VERSION "HNNBNNNYNNNNNNNNNNNNNNNNNNNNNNNNNNNNNNNNNN/4/%%%/4/'%**4NNN///"

NS_ :

BS_:

BU_: Airbag_MQB BAP_Tester_MQB BMS_MQB Datenlogger_MQB Gateway_MQB Getriebe_DQ_Hybrid_MQB Getriebe_DQ_MQB LEH_MQB Motor_Diesel_MQB Motor_Hybrid_MQB Motor_Otto_MQB SAK_MQB Waehlhebel_MQB

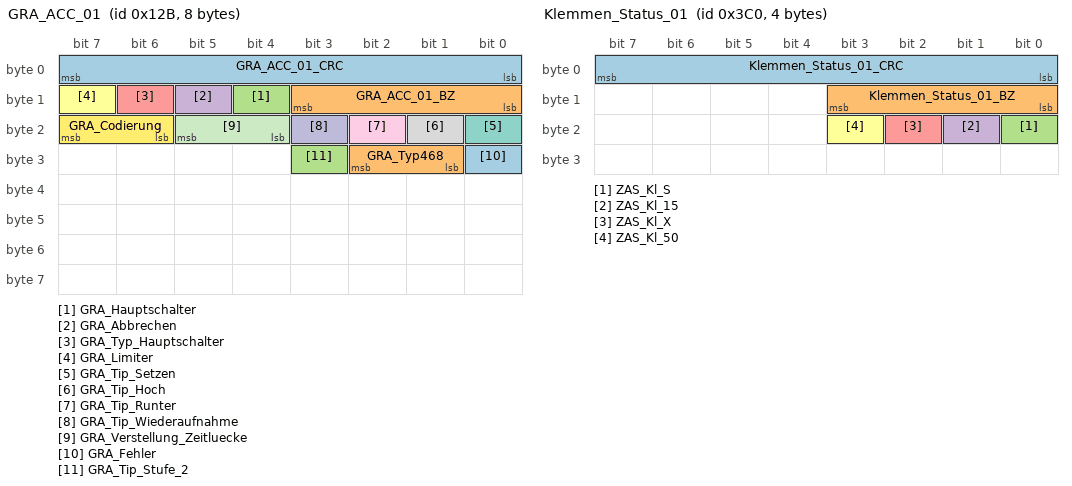
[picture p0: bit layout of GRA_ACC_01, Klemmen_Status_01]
BO_ 299 GRA_ACC_01: 8 Gateway_MQB
 SG_ GRA_ACC_01_CRC : 0|8@1+ (1,0) [0|255] ""  Motor_Diesel_MQB,Motor_Hybrid_MQB,Motor_Otto_MQB
 SG_ GRA_ACC_01_BZ : 8|4@1+ (1,0) [0|15] ""  Motor_Diesel_MQB,Motor_Hybrid_MQB,Motor_Otto_MQB
 SG_ GRA_Hauptschalter : 12|1@1+ (1,0) [0|1] ""  Motor_Diesel_MQB,Motor_Hybrid_MQB,Motor_Otto_MQB
 SG_ GRA_Abbrechen : 13|1@1+ (1,0) [0|1] ""  Motor_Diesel_MQB,Motor_Hybrid_MQB,Motor_Otto_MQB
 SG_ GRA_Typ_Hauptschalter : 14|1@1+ (1,0) [0|1] ""  Motor_Diesel_MQB,Motor_Hybrid_MQB,Motor_Otto_MQB
 SG_ GRA_Limiter : 15|1@1+ (1,0) [0|1] ""  Getriebe_DQ_Hybrid_MQB,Getriebe_DQ_MQB,Motor_Diesel_MQB,Motor_Hybrid_MQB,Motor_Otto_MQB
 SG_ GRA_Tip_Setzen : 16|1@1+ (1,0) [0|1] ""  Getriebe_DQ_Hybrid_MQB,Getriebe_DQ_MQB,Motor_Diesel_MQB,Motor_Hybrid_MQB,Motor_Otto_MQB
 SG_ GRA_Tip_Hoch : 17|1@1+ (1,0) [0|1] ""  Getriebe_DQ_Hybrid_MQB,Getriebe_DQ_MQB,Motor_Diesel_MQB,Motor_Hybrid_MQB,Motor_Otto_MQB
 SG_ GRA_Tip_Runter : 18|1@1+ (1,0) [0|1] ""  Getriebe_DQ_Hybrid_MQB,Getriebe_DQ_MQB,Motor_Diesel_MQB,Motor_Hybrid_MQB,Motor_Otto_MQB
 SG_ GRA_Tip_Wiederaufnahme : 19|1@1+ (1,0) [0|1] ""  Getriebe_DQ_Hybrid_MQB,Getriebe_DQ_MQB,Motor_Diesel_MQB,Motor_Hybrid_MQB,Motor_Otto_MQB
 SG_ GRA_Verstellung_Zeitluecke : 20|2@1+ (1,0) [0|3] ""  Motor_Diesel_MQB,Motor_Hybrid_MQB,Motor_Otto_MQB
 SG_ GRA_Codierung : 22|2@1+ (1,0) [0|3] ""  Motor_Diesel_MQB,Motor_Hybrid_MQB,Motor_Otto_MQB
 SG_ GRA_Fehler : 24|1@1+ (1,0) [0|1] ""  Getriebe_DQ_Hybrid_MQB,Getriebe_DQ_MQB,Motor_Diesel_MQB,Motor_Hybrid_MQB,Motor_Otto_MQB
 SG_ GRA_Typ468 : 25|2@1+ (1,0) [0|3] ""  Motor_Diesel_MQB,Motor_Hybrid_MQB,Motor_Otto_MQB
 SG_ GRA_Tip_Stufe_2 : 27|1@1+ (1,0) [0|1] ""  Motor_Diesel_MQB,Motor_Hybrid_MQB,Motor_Otto_MQB

BO_ 18 GSG_WFS_Anfrage: 8 Getriebe_DQ_Hybrid_MQB
 SG_ WFS_GSG_RND : 0|32@1+ (1,0) [0|4294967295] ""  Gateway_MQB
 SG_ WFS_GSG_CRC : 32|32@1+ (1,0) [0|4294967295] ""  Gateway_MQB

BO_ 19 IMMO_GSG_Antwort: 8 Gateway_MQB
 SG_ WFS_IMMO_GSG_CRC : 0|32@1+ (1,0) [0|4294967295] ""  Getriebe_DQ_Hybrid_MQB,Getriebe_DQ_MQB
 SG_ WFS_IMMO_GSG_Status : 56|8@1+ (1,0) [0|255] ""  Getriebe_DQ_Hybrid_MQB,Getriebe_DQ_MQB

BO_ 17 IMMO_MSG1_Antwort: 8 Gateway_MQB
 SG_ WFS_IMMO_MSG1_CRC : 0|32@1+ (1,0) [0|4294967295] ""  Motor_Diesel_MQB,Motor_Hybrid_MQB,Motor_Otto_MQB
 SG_ WFS_IMMO_MSG1_Status : 56|8@1+ (1,0) [0|255] ""  Motor_Diesel_MQB,Motor_Hybrid_MQB,Motor_Otto_MQB

BO_ 21 IMMO_MSG2_Antwort: 8 Gateway_MQB
 SG_ WFS_IMMO_MSG2_CRC : 0|32@1+ (1,0) [0|4294967295] "" Vector__XXX
 SG_ WFS_IMMO_MSG2_Status : 56|8@1+ (1,0) [0|255] "" Vector__XXX

BO_ 23 IMMO_MSG3_Antwort: 8 Gateway_MQB
 SG_ WFS_IMMO_MSG3_CRC : 0|32@1+ (1,0) [0|4294967295] "" Vector__XXX
 SG_ WFS_IMMO_MSG3_Status : 56|8@1+ (1,0) [0|255] "" Vector__XXX

BO_ 25 IMMO_MSG4_Antwort: 8 Gateway_MQB
 SG_ WFS_IMMO_MSG4_CRC : 0|32@1+ (1,0) [0|4294967295] ""  LEH_MQB
 SG_ WFS_IMMO_MSG4_Status : 56|8@1+ (1,0) [0|255] ""  LEH_MQB

BO_ 1813 ISO_Airbag_01_Req: 8 Gateway_MQB
 SG_ ISO_Airbag_01_Req_Data : 0|64@1+ (1,0) [0|4294967295] ""  Airbag_MQB

BO_ 1919 ISO_Airbag_01_Resp: 8 Airbag_MQB
 SG_ ISO_Airbag_01_Resp_Data : 0|64@1+ (1,0) [0|4294967295] ""  Gateway_MQB

BO_ 2022 ISO_EMotor_01_Req: 8 Gateway_MQB
 SG_ ISO_EMotor_01_Req_Data : 0|64@1+ (1,0) [0|4294967295] ""  LEH_MQB

BO_ 2030 ISO_EMotor_01_Resp: 8 LEH_MQB
 SG_ ISO_EMotor_01_Resp_Data : 0|64@1+ (1,0) [0|4294967295] ""  Gateway_MQB

BO_ 1793 ISO_Funktionaler_Req_01: 8 Gateway_MQB
 SG_ ISO_01_Req_Data : 0|64@1+ (1,0) [0|4294967295] "" Vector__XXX

BO_ 1794 ISO_Funktionaler_Req_02: 8 Gateway_MQB
 SG_ ISO_02_Req_Data : 0|64@1+ (1,0) [0|4294967295] "" Vector__XXX

BO_ 1796 ISO_Funktionaler_Req_04: 8 Gateway_MQB
 SG_ ISO_04_Req_Data : 0|64@1+ (1,0) [0|4294967295] "" Vector__XXX

BO_ 1797 ISO_Funktionaler_Req_05: 8 Gateway_MQB
 SG_ ISO_05_Req_Data : 0|64@1+ (1,0) [0|4294967295] "" Vector__XXX

BO_ 1798 ISO_Funktionaler_Req_06: 8 Gateway_MQB
 SG_ ISO_06_Req_Data : 0|64@1+ (1,0) [0|4294967295] "" Vector__XXX

BO_ 1799 ISO_Funktionaler_Req_07: 8 Gateway_MQB
 SG_ ISO_07_Req_Data : 0|64@1+ (1,0) [0|4294967295] "" Vector__XXX

BO_ 1800 ISO_Funktionaler_Req_08: 8 Gateway_MQB
 SG_ ISO_08_Req_Data : 0|64@1+ (1,0) [0|4294967295] "" Vector__XXX

BO_ 1801 ISO_Funktionaler_Req_09: 8 Gateway_MQB
 SG_ ISO_09_Req_Data : 0|64@1+ (1,0) [0|4294967295] "" Vector__XXX

BO_ 1795 ISO_Funktionaler_Req_Aggregate: 8 Gateway_MQB
 SG_ ISO_Functionaler_Req_Aggregate : 0|64@1+ (1,0) [0|4294967295] ""  Getriebe_DQ_Hybrid_MQB,Getriebe_DQ_MQB,LEH_MQB,Motor_Diesel_MQB,Motor_Hybrid_MQB,Motor_Otto_MQB

BO_ 1792 ISO_Funktionaler_Req_All: 8 Gateway_MQB
 SG_ ISO_ALL_01_Req_Data : 0|64@1+ (1,0) [0|4294967295] ""  Airbag_MQB,BMS_MQB,Getriebe_DQ_Hybrid_MQB,Getriebe_DQ_MQB,LEH_MQB,Motor_Diesel_MQB,Motor_Hybrid_MQB,Motor_Otto_MQB,SAK_MQB

BO_ 2015 ISO_Funktionaler_Req_OBD: 8 Gateway_MQB
 SG_ ISO_OBD_Funktionaler_Req_Data : 0|64@1+ (1,0) [0|4294967295] ""  BMS_MQB,Getriebe_DQ_Hybrid_MQB,Getriebe_DQ_MQB,LEH_MQB,Motor_Diesel_MQB,Motor_Hybrid_MQB,Motor_Otto_MQB

BO_ 2017 ISO_Getriebe_01_Req: 8 Gateway_MQB
 SG_ ISO_Getriebe_01_Req_Data : 0|64@1+ (1,0) [0|4294967295] ""  Getriebe_DQ_Hybrid_MQB,Getriebe_DQ_MQB

BO_ 2025 ISO_Getriebe_01_Resp: 8 Getriebe_DQ_Hybrid_MQB
 SG_ ISO_Getriebe_01_Resp_Data : 0|64@1+ (1,0) [0|4294967295] ""  Gateway_MQB

BO_ 2021 ISO_Hybrid_01_Req: 8 Gateway_MQB
 SG_ ISO_Hybrid_01_Req_Data : 0|64@1+ (1,0) [0|4294967295] ""  BMS_MQB

BO_ 2029 ISO_Hybrid_01_Resp: 8 BMS_MQB
 SG_ ISO_Hybrid_01_Resp_Data : 0|64@1+ (1,0) [0|4294967295] ""  Gateway_MQB

BO_ 2016 ISO_MO_01_Req: 8 Gateway_MQB
 SG_ ISO_MO_01_Req_Data : 0|64@1+ (1,0) [0|4294967295] ""  Motor_Diesel_MQB,Motor_Hybrid_MQB,Motor_Otto_MQB

BO_ 2024 ISO_MO_01_Resp: 8 Motor_Diesel_MQB
 SG_ ISO_MO_01_Resp_Data : 0|64@1+ (1,0) [0|4294967295] ""  Gateway_MQB

BO_ 2018 ISO_MOS_01_Req: 8 Gateway_MQB
 SG_ ISO_MOS_01_Req_Data : 0|64@1+ (1,0) [0|4294967295] "" Vector__XXX

BO_ 2026 ISO_MOS_01_Resp: 8 Vector__XXX
 SG_ ISO_MOS_01_Resp_Data : 0|64@1+ (1,0) [0|4294967295] ""  Gateway_MQB

BO_ 2023 ISO_OBD_reserv3_Req: 8 Gateway_MQB
 SG_ ISO_OBD_reserv3_Req_Data : 0|64@1+ (1,0) [0|4294967295] "" Vector__XXX

BO_ 2031 ISO_OBD_reserv3_Resp: 8 Vector__XXX
 SG_ ISO_OBD_reserv3_Resp_Data : 0|64@1+ (1,0) [0|4294967295] ""  Gateway_MQB

BO_ 2020 ISO_OBD_reserv4_Req: 8 Gateway_MQB
 SG_ ISO_OBD_reserv4_Req_Data : 0|64@1+ (1,0) [0|4294967295] "" Vector__XXX

BO_ 2028 ISO_OBD_reserv4_Resp: 8 Vector__XXX
 SG_ ISO_OBD_reserv4_Resp_Data : 0|64@1+ (1,0) [0|4294967295] ""  Gateway_MQB

BO_ 2019 ISO_OBD_reserv5_Req: 8 Gateway_MQB
 SG_ ISO_OBD_reserv5_Req_Data : 0|64@1+ (1,0) [0|4294967295] "" Vector__XXX

BO_ 2027 ISO_OBD_reserv5_Resp: 8 Vector__XXX
 SG_ ISO_OBD_reserv5_Resp_Data : 0|64@1+ (1,0) [0|4294967295] ""  Gateway_MQB

BO_ 1820 ISO_Soundaktor_Req: 8 Gateway_MQB
 SG_ ISO_Soundaktor_Req_Data : 0|64@1+ (1,0) [0|4294967295] ""  SAK_MQB

BO_ 1926 ISO_Soundaktor_Resp: 8 SAK_MQB
 SG_ ISO_Soundaktor_Resp_Data : 0|64@1+ (1,0) [0|4294967295] ""  Gateway_MQB

BO_ 960 Klemmen_Status_01: 4 Gateway_MQB
 SG_ Klemmen_Status_01_CRC : 0|8@1+ (1,0) [0|255] ""  Airbag_MQB,BMS_MQB,Motor_Diesel_MQB,Motor_Hybrid_MQB,Motor_Otto_MQB
 SG_ Klemmen_Status_01_BZ : 8|4@1+ (1,0) [0|15] ""  Airbag_MQB,BMS_MQB,Motor_Diesel_MQB,Motor_Hybrid_MQB,Motor_Otto_MQB
 SG_ ZAS_Kl_S : 16|1@1+ (1,0) [0|1] "" Vector__XXX
 SG_ ZAS_Kl_15 : 17|1@1+ (1,0) [0|1] ""  Airbag_MQB,BMS_MQB,Motor_Diesel_MQB,Motor_Hybrid_MQB,Motor_Otto_MQB
 SG_ ZAS_Kl_X : 18|1@1+ (1,0) [0|1] "" Vector__XXX
 SG_ ZAS_Kl_50 : 19|1@1+ (1,0) [0|1] "" Vector__XXX

BO_ 949 Klima_11: 8 Gateway_MQB
 SG_ KL_Drehz_Anh : 0|1@1+ (1,0) [0|1] ""  Motor_Diesel_MQB,Motor_Hybrid_MQB,Motor_Otto_MQB
 SG_ KL_Vorwarn_Komp_ein : 1|1@1+ (1,0) [0|1] ""  Motor_Diesel_MQB,Motor_Hybrid_MQB,Motor_Otto_MQB
 SG_ KL_AC_Schalter : 2|1@1+ (1,0) [0|1] "" Vector__XXX
 SG_ KL_Komp_Moment_alt : 3|1@1+ (1,0) [0|1] "" Vector__XXX
 SG_ KL_Zonen : 4|2@1+ (1,0) [0|3] ""  Motor_Diesel_MQB,Motor_Hybrid_MQB,Motor_Otto_MQB
 SG_ KL_Vorwarn_Zuheizer_ein : 6|1@1+ (1,0) [0|1] "" Vector__XXX
 SG_ KL_Zustand : 7|1@1+ (1,0) [0|1] ""  Motor_Diesel_MQB,Motor_Hybrid_MQB,Motor_Otto_MQB
 SG_ KL_Comp_rev_rq : 8|8@1+ (50,0) [0|8600] "Unit_MinutInver" Vector__XXX
 SG_ KL_Charisma_FahrPr : 16|4@1+ (1,0) [0|15] "" Vector__XXX
 SG_ KL_Charisma_Status : 20|2@1+ (1,0) [0|3] "" Vector__XXX
 SG_ KL_Comp_enable : 23|1@1+ (1,0) [0|1] "" Vector__XXX
 SG_ KL_Last_Kompr : 24|8@1+ (0.25,0) [0|63.5] "Unit_NewtoMeter"  Motor_Diesel_MQB,Motor_Hybrid_MQB,Motor_Otto_MQB
 SG_ KL_Spannungs_Anf : 32|2@1+ (1,0) [0|3] "" Vector__XXX
 SG_ KL_Thermomanagement : 34|2@1+ (1,0) [0|3] ""  Motor_Diesel_MQB,Motor_Hybrid_MQB,Motor_Otto_MQB
 SG_ KL_StartStopp_Info : 36|2@1+ (1,0) [0|3] ""  Motor_Diesel_MQB,Motor_Otto_MQB
 SG_ KL_Anf_KL : 40|8@1+ (0.4,0) [0|101.6] "Unit_PerCent"  Motor_Diesel_MQB,Motor_Hybrid_MQB,Motor_Otto_MQB
 SG_ KL_el_Zuheizer_Stufe : 48|3@1+ (1,0) [0|7] ""  Motor_Diesel_MQB

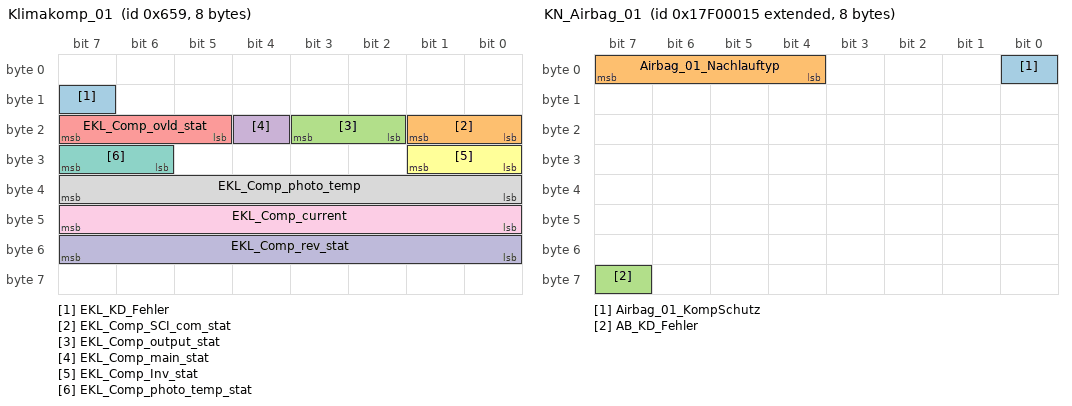
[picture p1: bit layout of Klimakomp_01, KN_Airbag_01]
BO_ 1625 Klimakomp_01: 8 Gateway_MQB
 SG_ EKL_KD_Fehler : 15|1@1+ (1,0) [0|1] "" Vector__XXX
 SG_ EKL_Comp_SCI_com_stat : 16|2@1+ (1,0) [0|3] "" Vector__XXX
 SG_ EKL_Comp_output_stat : 18|2@1+ (1,0) [0|3] "" Vector__XXX
 SG_ EKL_Comp_main_stat : 20|1@1+ (1,0) [0|1] "" Vector__XXX
 SG_ EKL_Comp_ovld_stat : 21|3@1+ (1,0) [0|7] "" Vector__XXX
 SG_ EKL_Comp_Inv_stat : 24|2@1+ (1,0) [0|3] "" Vector__XXX
 SG_ EKL_Comp_photo_temp_stat : 30|2@1+ (1,0) [0|3] "" Vector__XXX
 SG_ EKL_Comp_photo_temp : 32|8@1+ (1,0) [0|254] "Unit_DegreCelsi" Vector__XXX
 SG_ EKL_Comp_current : 40|8@1+ (0.1,0) [0|25.4] "Unit_Amper"  Motor_Hybrid_MQB
 SG_ EKL_Comp_rev_stat : 48|8@1+ (50,0) [0|8600] "Unit_MinutInver" Vector__XXX

BO_ 2549088277 KN_Airbag_01: 8 Airbag_MQB
 SG_ Airbag_01_KompSchutz : 0|1@1+ (1,0) [0|1] "" Vector__XXX
 SG_ Airbag_01_Nachlauftyp : 4|4@1+ (1,0) [0|15] ""  Gateway_MQB
 SG_ AB_KD_Fehler : 63|1@1+ (1,0) [0|1] ""  Gateway_MQB

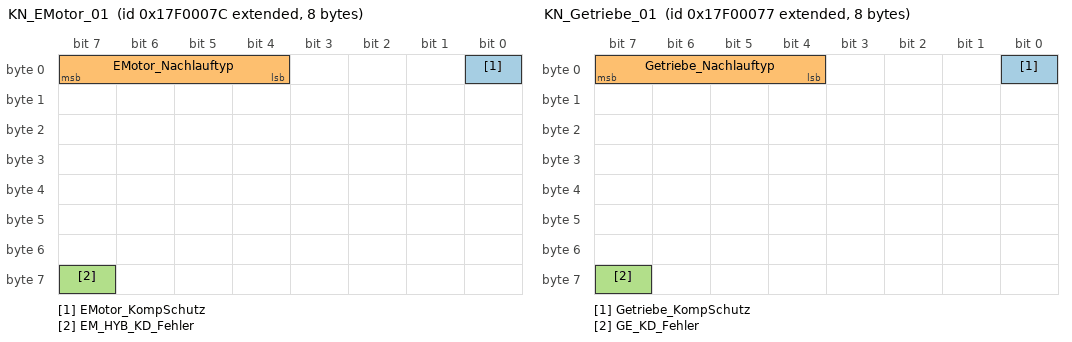
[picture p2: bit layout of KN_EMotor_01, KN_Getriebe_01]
BO_ 2549088380 KN_EMotor_01: 8 LEH_MQB
 SG_ EMotor_KompSchutz : 0|1@1+ (1,0) [0|1] "" Vector__XXX
 SG_ EMotor_Nachlauftyp : 4|4@1+ (1,0) [0|15] ""  Gateway_MQB
 SG_ EM_HYB_KD_Fehler : 63|1@1+ (1,0) [0|1] ""  Gateway_MQB

BO_ 2549088375 KN_Getriebe_01: 8 Getriebe_DQ_Hybrid_MQB
 SG_ Getriebe_KompSchutz : 0|1@1+ (1,0) [0|1] "" Vector__XXX
 SG_ Getriebe_Nachlauftyp : 4|4@1+ (1,0) [0|15] ""  Gateway_MQB
 SG_ GE_KD_Fehler : 63|1@1+ (1,0) [0|1] ""  Gateway_MQB

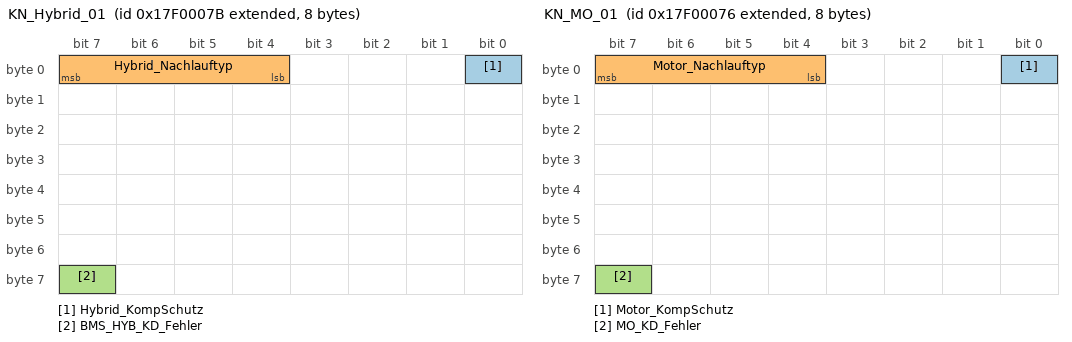
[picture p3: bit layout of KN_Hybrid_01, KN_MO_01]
BO_ 2549088379 KN_Hybrid_01: 8 BMS_MQB
 SG_ Hybrid_KompSchutz : 0|1@1+ (1,0) [0|1] "" Vector__XXX
 SG_ Hybrid_Nachlauftyp : 4|4@1+ (1,0) [0|15] ""  Gateway_MQB
 SG_ BMS_HYB_KD_Fehler : 63|1@1+ (1,0) [0|1] ""  Gateway_MQB

BO_ 2549088374 KN_MO_01: 8 Motor_Diesel_MQB
 SG_ Motor_KompSchutz : 0|1@1+ (1,0) [0|1] "" Vector__XXX
 SG_ Motor_Nachlauftyp : 4|4@1+ (1,0) [0|15] ""  Gateway_MQB
 SG_ MO_KD_Fehler : 63|1@1+ (1,0) [0|1] ""  Gateway_MQB

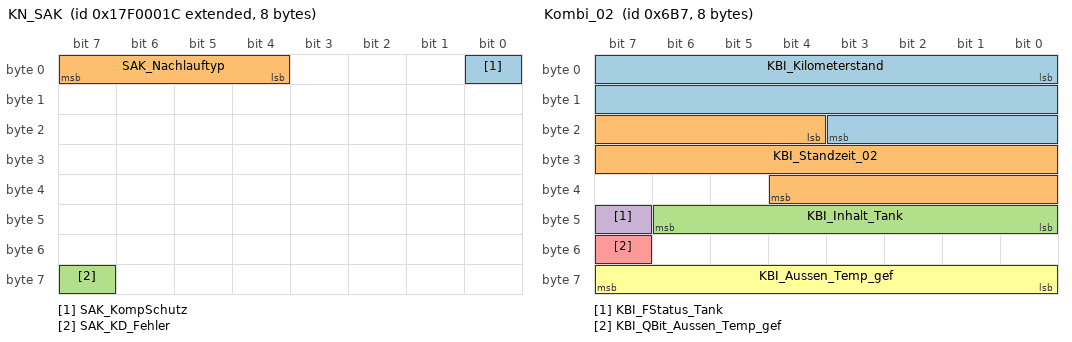
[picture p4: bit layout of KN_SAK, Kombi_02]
BO_ 2549088284 KN_SAK: 8 SAK_MQB
 SG_ SAK_KompSchutz : 0|1@1+ (1,0) [0|1] "" Vector__XXX
 SG_ SAK_Nachlauftyp : 4|4@1+ (1,0) [0|15] ""  Gateway_MQB
 SG_ SAK_KD_Fehler : 63|1@1+ (1,0) [0|1] ""  Gateway_MQB

BO_ 779 Kombi_01: 8 Gateway_MQB
 SG_ KBI_ABS_Lampe : 0|1@1+ (1,0) [0|1] "" Vector__XXX
 SG_ KBI_ESP_Lampe : 1|1@1+ (1,0) [0|1] "" Vector__XXX
 SG_ KBI_BKL_Lampe : 2|1@1+ (1,0) [0|1] "" Vector__XXX
 SG_ KBI_Airbag_Lampe : 3|1@1+ (1,0) [0|1] ""  Airbag_MQB
 SG_ KBI_SILA_gueltig : 4|1@1+ (1,0) [0|1] ""  Airbag_MQB
 SG_ KBI_Lenkung_Lampe : 5|1@1+ (1,0) [0|1] "" Vector__XXX
 SG_ KBI_Vorglueh_System_Lampe : 6|1@1+ (1,0) [0|1] ""  Motor_Diesel_MQB
 SG_ KBI_NV_in_Anzeige : 7|1@1+ (1,0) [0|1] "" Vector__XXX
 SG_ Kombi_01_BZ : 8|4@1+ (1,0) [0|15] ""  Motor_Diesel_MQB,Motor_Hybrid_MQB,Motor_Otto_MQB
 SG_ KBI_Anzeigestatus_ACC : 12|1@1+ (1,0) [0|1] "" Vector__XXX
 SG_ KBI_Anzeigestatus_GRA : 13|2@1+ (1,0) [0|3] ""  Motor_Diesel_MQB,Motor_Hybrid_MQB,Motor_Otto_MQB
 SG_ KBI_Oeldruck_Schalter : 15|1@1+ (1,0) [0|1] "" Vector__XXX
 SG_ KBI_Tankwarnung : 16|1@1+ (1,0) [0|1] ""  Motor_Diesel_MQB,Motor_Hybrid_MQB,Motor_Otto_MQB
 SG_ KBI_MFA_v_Einheit_01 : 17|1@1+ (1,0) [0|1] ""  Motor_Diesel_MQB,Motor_Hybrid_MQB,Motor_Otto_MQB
 SG_ KBI_im_Stellgliedtest : 18|1@1+ (1,0) [0|1] ""  Airbag_MQB
 SG_ KBI_Anzeigefehler_LDW : 19|2@1+ (1,0) [0|3] "" Vector__XXX
 SG_ KBI_Variante_USA : 21|1@1+ (1,0) [0|1] "" Vector__XXX
 SG_ KBI_Oeldruckwarnung : 22|1@1+ (1,0) [0|1] "" Vector__XXX
 SG_ KBI_Handbremse : 23|1@1+ (1,0) [0|1] ""  Getriebe_DQ_Hybrid_MQB,Getriebe_DQ_MQB
 SG_ KBI_V_Digital : 24|9@1+ (1,0) [0|511] "" Vector__XXX
 SG_ KBI_PLA_in_Anzeige : 33|1@1+ (1,0) [0|1] "" Vector__XXX
 SG_ KBI_Anzeigefehler_NV : 34|1@1+ (1,0) [0|1] "" Vector__XXX
 SG_ KBI_Anzeigestatus_LIM : 35|2@1+ (1,0) [0|3] ""  Motor_Diesel_MQB,Motor_Hybrid_MQB,Motor_Otto_MQB
 SG_ KBI_angez_Geschw : 48|10@1+ (0.32,0) [0|325.12] "Unit_KiloMeterPerHour"  Getriebe_DQ_Hybrid_MQB,Getriebe_DQ_MQB,Motor_Diesel_MQB,Motor_Hybrid_MQB,Motor_Otto_MQB
 SG_ KBI_Einheit_Tacho : 58|1@1+ (1,0) [0|1] ""  Motor_Diesel_MQB,Motor_Hybrid_MQB,Motor_Otto_MQB
 SG_ KBI_Konsistenz_ACC : 59|1@1+ (1,0) [0|1] "" Vector__XXX
 SG_ KBI_Fehler_Anzeige_ACC : 60|1@1+ (1,0) [0|1] "" Vector__XXX
 SG_ KBI_Anzeigefehler_SWA : 61|2@1+ (1,0) [0|3] "" Vector__XXX

BO_ 1719 Kombi_02: 8 Gateway_MQB
 SG_ KBI_Kilometerstand : 0|20@1+ (1,0) [0|1048573] "Unit_KiloMeter" Vector__XXX
 SG_ KBI_Standzeit_02 : 20|17@1+ (1,0) [0|131068] "Unit_Secon"  Getriebe_DQ_Hybrid_MQB,Getriebe_DQ_MQB,Motor_Diesel_MQB,Motor_Hybrid_MQB,Motor_Otto_MQB
 SG_ KBI_Inhalt_Tank : 40|7@1+ (1,0) [0|125] "Unit_Liter"  Motor_Diesel_MQB,Motor_Hybrid_MQB,Motor_Otto_MQB
 SG_ KBI_FStatus_Tank : 47|1@1+ (1,0) [0|1] ""  Motor_Diesel_MQB,Motor_Hybrid_MQB,Motor_Otto_MQB
 SG_ KBI_QBit_Aussen_Temp_gef : 55|1@1+ (1,0) [0|1] ""  Getriebe_DQ_Hybrid_MQB,Getriebe_DQ_MQB,Motor_Diesel_MQB,Motor_Hybrid_MQB,Motor_Otto_MQB
 SG_ KBI_Aussen_Temp_gef : 56|8@1+ (0.5,-50) [-50|75] "Unit_DegreCelsi"  Getriebe_DQ_Hybrid_MQB,Getriebe_DQ_MQB,Motor_Diesel_MQB,Motor_Hybrid_MQB,Motor_Otto_MQB

BO_ 2549874965 KS_Airbag_01_Req: 8 Gateway_MQB
 SG_ KS_Airbag_01_Req_Data : 0|64@1+ (1,0) [0|4294967295] ""  Airbag_MQB

BO_ 2550006037 KS_Airbag_01_Resp: 8 Airbag_MQB
 SG_ KS_Airbag_01_Resp_Data : 0|64@1+ (1,0) [0|4294967295] ""  Gateway_MQB

BO_ 982 Licht_hinten_01: 8 Gateway_MQB
 SG_ Licht_hinten_01_BZ : 0|4@1+ (1,0) [0|15] ""  Motor_Diesel_MQB,Motor_Hybrid_MQB,Motor_Otto_MQB
 SG_ BCM2_Bremsl_durch_ECD : 5|1@1+ (1,0) [0|1] ""  Motor_Diesel_MQB,Motor_Hybrid_MQB,Motor_Otto_MQB
 SG_ LH_Aussenlicht_def : 7|1@1+ (1,0) [0|1] "" Vector__XXX
 SG_ LH_Standlicht_H_aktiv : 8|1@1+ (1,0) [0|1] "" Vector__XXX
 SG_ LH_Parklicht_HL_aktiv : 9|1@1+ (1,0) [0|1] "" Vector__XXX
 SG_ LH_Parklicht_HR_aktiv : 10|1@1+ (1,0) [0|1] "" Vector__XXX
 SG_ LH_Bremslicht_H_aktiv : 11|1@1+ (1,0) [0|1] "" Vector__XXX
 SG_ LH_Nebelschluss_aktiv : 12|1@1+ (1,0) [0|1] "" Vector__XXX
 SG_ LH_Rueckfahrlicht_aktiv : 13|1@1+ (1,0) [0|1] "" Vector__XXX
 SG_ LH_Blinker_HL_akt : 14|1@1+ (1,0) [0|1] "" Vector__XXX
 SG_ LH_Blinker_HR_akt : 15|1@1+ (1,0) [0|1] "" Vector__XXX
 SG_ LH_Blinker_li_def : 16|1@1+ (1,0) [0|1] "" Vector__XXX
 SG_ LH_Bremsl_li_def : 17|1@1+ (1,0) [0|1] "" Vector__XXX
 SG_ LH_Schlusslicht_li_def : 18|1@1+ (1,0) [0|1] "" Vector__XXX
 SG_ LH_Rueckf_li_def : 19|1@1+ (1,0) [0|1] "" Vector__XXX
 SG_ LH_Nebel_li_def : 20|1@1+ (1,0) [0|1] "" Vector__XXX
 SG_ LH_Schluss_Brems_Nebel_li_def : 21|1@1+ (1,0) [0|1] "" Vector__XXX
 SG_ LH_Schluss_Brems_Nebel_re_def : 22|1@1+ (1,0) [0|1] "" Vector__XXX
 SG_ LH_Schluss_Brems_li_def : 24|1@1+ (1,0) [0|1] "" Vector__XXX
 SG_ LH_Schluss_Nebel_li_def : 25|1@1+ (1,0) [0|1] "" Vector__XXX
 SG_ LH_SL_BRL_BLK_li_def : 26|1@1+ (1,0) [0|1] "" Vector__XXX
 SG_ LH_Brems_Blk_li_def : 27|1@1+ (1,0) [0|1] "" Vector__XXX
 SG_ LH_Blinker_re_def : 32|1@1+ (1,0) [0|1] "" Vector__XXX
 SG_ LH_Bremsl_re_def : 33|1@1+ (1,0) [0|1] "" Vector__XXX
 SG_ LH_Schlusslicht_re_def : 34|1@1+ (1,0) [0|1] "" Vector__XXX
 SG_ LH_Rueckf_re_def : 35|1@1+ (1,0) [0|1] "" Vector__XXX
 SG_ LH_Nebel_re_def : 36|1@1+ (1,0) [0|1] "" Vector__XXX
 SG_ LH_Schluss_Brems_re_def : 40|1@1+ (1,0) [0|1] "" Vector__XXX
 SG_ LH_Schluss_Nebel_re_def : 41|1@1+ (1,0) [0|1] "" Vector__XXX
 SG_ LH_SL_BRL_BLK_re_def : 42|1@1+ (1,0) [0|1] "" Vector__XXX
 SG_ LH_Brems_Blk_re_def : 43|1@1+ (1,0) [0|1] "" Vector__XXX
 SG_ LH_Kennzl_def : 48|1@1+ (1,0) [0|1] "" Vector__XXX
 SG_ LH_3_Bremsl_def : 49|1@1+ (1,0) [0|1] ""  Motor_Diesel_MQB,Motor_Hybrid_MQB,Motor_Otto_MQB
 SG_ LH_Nebel_mi_def : 50|1@1+ (1,0) [0|1] "" Vector__XXX
 SG_ LH_Rueckf_mi_def : 51|1@1+ (1,0) [0|1] "" Vector__XXX
 SG_ LH_Bremsl_li_ges_def : 54|1@1+ (1,0) [0|1] ""  Motor_Diesel_MQB,Motor_Hybrid_MQB,Motor_Otto_MQB
 SG_ LH_Bremsl_re_ges_def : 55|1@1+ (1,0) [0|1] ""  Motor_Diesel_MQB,Motor_Hybrid_MQB,Motor_Otto_MQB

BO_ 2549875733 Log_Airbag_01_Req: 8 Datenlogger_MQB
 SG_ Log_Airbag_01_Req_Data : 0|64@1+ (1,0) [0|4294967295] ""  Airbag_MQB

BO_ 2550006805 Log_Airbag_01_Resp: 8 Airbag_MQB
 SG_ Log_Airbag_01_Resp_Data : 0|64@1+ (1,0) [0|4294967295] ""  Datenlogger_MQB

BO_ 2549941257 Log_Datenlogger_Req: 8 Datenlogger_MQB
 SG_ Log_Datenlogger_Req_Data : 0|64@1+ (1,0) [0|4294967295] ""  Airbag_MQB,BMS_MQB,Getriebe_DQ_Hybrid_MQB,Getriebe_DQ_MQB,LEH_MQB,Motor_Diesel_MQB,Motor_Hybrid_MQB,Motor_Otto_MQB,SAK_MQB

BO_ 2549875836 Log_EMotor_01_Req: 8 Datenlogger_MQB
 SG_ Log_EMotor_01_Req_Data : 0|64@1+ (1,0) [0|4294967295] ""  LEH_MQB

BO_ 2550006908 Log_EMotor_01_Resp: 8 LEH_MQB
 SG_ Log_EMotor_01_Resp_Data : 0|64@1+ (1,0) [0|4294967295] ""  Datenlogger_MQB

BO_ 2549875831 Log_Getriebe_01_Req: 8 Datenlogger_MQB
 SG_ Log_Getriebe_01_Req_Data : 0|64@1+ (1,0) [0|4294967295] ""  Getriebe_DQ_Hybrid_MQB,Getriebe_DQ_MQB

BO_ 2550006903 Log_Getriebe_01_Resp: 8 Getriebe_DQ_Hybrid_MQB
 SG_ Log_Getriebe_01_Resp_Data : 0|64@1+ (1,0) [0|4294967295] ""  Datenlogger_MQB

BO_ 2549875835 Log_Hybrid_01_Req: 8 Datenlogger_MQB
 SG_ Log_Hybrid_01_Req_Data : 0|64@1+ (1,0) [0|4294967295] ""  BMS_MQB

BO_ 2550006907 Log_Hybrid_01_Resp: 8 BMS_MQB
 SG_ Log_Hybrid_01_Resp_Data : 0|64@1+ (1,0) [0|4294967295] ""  Datenlogger_MQB

BO_ 2549875830 Log_MO_01_Req: 8 Datenlogger_MQB
 SG_ Log_MO_01_Req_Data : 0|64@1+ (1,0) [0|4294967295] ""  Motor_Diesel_MQB,Motor_Hybrid_MQB,Motor_Otto_MQB

BO_ 2550006902 Log_MO_01_Resp: 8 Motor_Diesel_MQB
 SG_ Log_MO_01_Resp_Data : 0|64@1+ (1,0) [0|4294967295] ""  Datenlogger_MQB

BO_ 2549875740 Log_Soundaktor_Req: 8 Datenlogger_MQB
 SG_ Log_Soundaktor_Req_Data : 0|64@1+ (1,0) [0|4294967295] ""  SAK_MQB

BO_ 2550006812 Log_Soundaktor_Resp: 8 SAK_MQB
 SG_ Log_Soundaktor_Resp_Data : 0|64@1+ (1,0) [0|4294967295] ""  Datenlogger_MQB

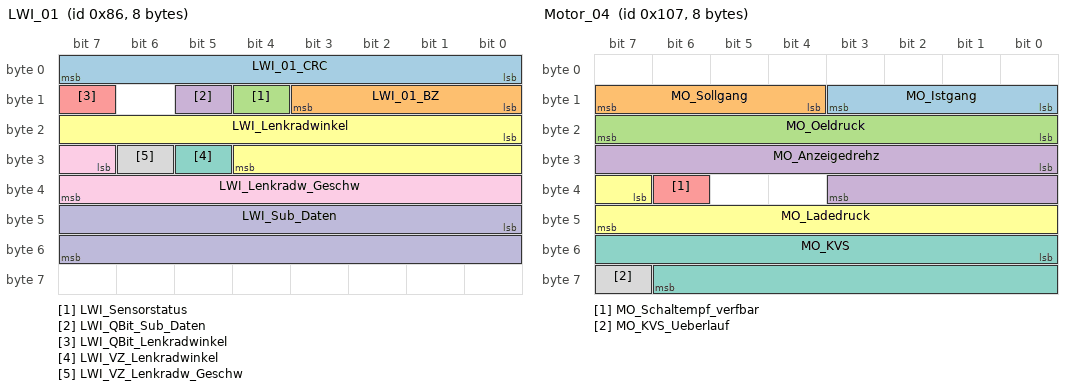
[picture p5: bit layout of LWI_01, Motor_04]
BO_ 134 LWI_01: 8 Gateway_MQB
 SG_ LWI_01_CRC : 0|8@1+ (1,0) [0|255] ""  Airbag_MQB,Getriebe_DQ_Hybrid_MQB,Getriebe_DQ_MQB,Motor_Diesel_MQB,Motor_Hybrid_MQB,Motor_Otto_MQB
 SG_ LWI_01_BZ : 8|4@1+ (1,0) [0|15] ""  Airbag_MQB,Getriebe_DQ_Hybrid_MQB,Getriebe_DQ_MQB,Motor_Diesel_MQB,Motor_Hybrid_MQB,Motor_Otto_MQB
 SG_ LWI_Sensorstatus : 12|1@1+ (1,0) [0|1] ""  Airbag_MQB,Getriebe_DQ_Hybrid_MQB,Getriebe_DQ_MQB,Motor_Diesel_MQB,Motor_Hybrid_MQB,Motor_Otto_MQB
 SG_ LWI_QBit_Sub_Daten : 13|1@1+ (1,0) [0|1] "" Vector__XXX
 SG_ LWI_QBit_Lenkradwinkel : 15|1@1+ (1,0) [0|1] ""  Airbag_MQB,Getriebe_DQ_Hybrid_MQB,Getriebe_DQ_MQB,Motor_Diesel_MQB,Motor_Hybrid_MQB,Motor_Otto_MQB
 SG_ LWI_Lenkradwinkel : 16|13@1+ (0.1,0) [0|800] "Unit_DegreOfArc"  Airbag_MQB,Getriebe_DQ_Hybrid_MQB,Getriebe_DQ_MQB,Motor_Diesel_MQB,Motor_Hybrid_MQB,Motor_Otto_MQB
 SG_ LWI_VZ_Lenkradwinkel : 29|1@1+ (1,0) [0|1] ""  Airbag_MQB,Getriebe_DQ_Hybrid_MQB,Getriebe_DQ_MQB,Motor_Diesel_MQB,Motor_Hybrid_MQB,Motor_Otto_MQB
 SG_ LWI_VZ_Lenkradw_Geschw : 30|1@1+ (1,0) [0|1] "" Vector__XXX
 SG_ LWI_Lenkradw_Geschw : 31|9@1+ (5,0) [0|2500] "Unit_DegreOfArcPerSecon" Vector__XXX
 SG_ LWI_Sub_Daten : 40|16@1+ (1,0) [0|65535] "" Vector__XXX

BO_ 263 Motor_04: 8 Motor_Diesel_MQB
 SG_ MO_Istgang : 8|4@1+ (1,0) [0|15] ""  Gateway_MQB
 SG_ MO_Sollgang : 12|4@1+ (1,0) [0|15] ""  Gateway_MQB
 SG_ MO_Oeldruck : 16|8@1+ (0.04,0) [0|10] "Unit_Bar"  Gateway_MQB
 SG_ MO_Anzeigedrehz : 24|12@1+ (3,0) [0|12282] "Unit_MinutInver"  Gateway_MQB
 SG_ MO_Schaltempf_verfbar : 38|1@1+ (1,0) [0|1] ""  Gateway_MQB
 SG_ MO_Ladedruck : 39|9@1+ (0.01,0) [0|5.1] "Unit_Bar"  Gateway_MQB
 SG_ MO_KVS : 48|15@1+ (1,0) [0|32767] "Unit_MicroLiter"  Gateway_MQB
 SG_ MO_KVS_Ueberlauf : 63|1@1+ (1,0) [0|1] ""  Gateway_MQB

BO_ 1600 Motor_07: 8 Motor_Diesel_MQB
 SG_ MO_QBit_Ansaugluft_Temp : 0|1@1+ (1,0) [0|1] ""  Gateway_MQB
 SG_ MO_QBit_Oel_Temp : 1|1@1+ (1,0) [0|1] ""  Gateway_MQB,Getriebe_DQ_Hybrid_MQB,Getriebe_DQ_MQB
 SG_ MO_QBit_Kuehlmittel_Temp : 2|1@1+ (1,0) [0|1] ""  Gateway_MQB,Getriebe_DQ_Hybrid_MQB,Getriebe_DQ_MQB,LEH_MQB
 SG_ MO_Stellgliedtest_Soundaktuator : 3|1@1+ (1,0) [0|1] ""  Gateway_MQB
 SG_ MO_HYB_Fehler_HV_Netz : 4|1@1+ (1,0) [0|1] ""  Gateway_MQB
 SG_ MO_aktives_Getriebeheizen : 5|1@1+ (1,0) [0|1] ""  Gateway_MQB,Getriebe_DQ_Hybrid_MQB,Getriebe_DQ_MQB
 SG_ MO_Absperrventil_oeffnen : 6|2@1+ (1,0) [0|3] ""  Gateway_MQB
 SG_ MO_Ansaugluft_Temp : 8|8@1+ (0.75,-48) [-48|141.75] "Unit_DegreCelsi"  Gateway_MQB
 SG_ MO_Oel_Temp : 16|8@1+ (1,-60) [-60|192] "Unit_DegreCelsi"  Gateway_MQB,Getriebe_DQ_Hybrid_MQB,Getriebe_DQ_MQB
 SG_ MO_Kuehlmittel_Temp : 24|8@1+ (0.75,-48) [-48|141.75] "Unit_DegreCelsi"  Gateway_MQB,Getriebe_DQ_Hybrid_MQB,Getriebe_DQ_MQB,LEH_MQB
 SG_ MO_Hoeheninfo : 32|8@1+ (0.00781,0) [0|1.98374] ""  Gateway_MQB,Getriebe_DQ_Hybrid_MQB,Getriebe_DQ_MQB
 SG_ MO_Kennfeldk : 40|1@1+ (1,0) [0|1] ""  Gateway_MQB
 SG_ MO_Versionsinfo : 41|6@1+ (1,0) [0|63] ""  Gateway_MQB
 SG_ MO_Getriebe_kuehlen : 47|1@1+ (1,0) [0|1] ""  Gateway_MQB,Getriebe_DQ_Hybrid_MQB,Getriebe_DQ_MQB
 SG_ MO_Mom_Traegheit_02 : 48|5@1+ (0.01,0) [0|0.31] "Unit_KiloGramMeterSquar"  Gateway_MQB,Getriebe_DQ_Hybrid_MQB,Getriebe_DQ_MQB
 SG_ MO_Heizungspumpenansteuerung : 53|4@1+ (10,0) [0|100] "Unit_PerCent"  Gateway_MQB
 SG_ MO_SpannungsAnf : 57|1@1+ (1,0) [0|1] ""  Gateway_MQB
 SG_ MO_Nachlaufzeit_Heizungspumpe : 58|6@1+ (15,0) [0|945] "Unit_Secon"  Gateway_MQB

BO_ 1607 Motor_09: 8 Motor_Diesel_MQB
 SG_ MO_ITM_Kuehlmittel_Temp : 0|8@1+ (0.75,-48) [-45.75|143.25] "Unit_DegreCelsi"  Gateway_MQB,Getriebe_DQ_Hybrid_MQB,Getriebe_DQ_MQB
 SG_ MO_E85_Sensor : 8|4@1+ (10,0) [0|100] "Unit_PerCent"  Gateway_MQB
 SG_ SCR_Anz_Motorstarts : 12|4@1+ (1,0) [0|8] ""  Gateway_MQB
 SG_ SCR_Reichweite : 16|15@1+ (1,0) [0|32766] ""  Gateway_MQB
 SG_ SCR_Warnstufe_1 : 32|1@1+ (1,0) [0|1] ""  Gateway_MQB
 SG_ SCR_Warnstufe_2 : 33|1@1+ (1,0) [0|1] ""  Gateway_MQB
 SG_ SCR_Text : 34|3@1+ (1,0) [0|7] ""  Gateway_MQB
 SG_ SCR_Akustik : 37|2@1+ (1,0) [0|3] ""  Gateway_MQB
 SG_ MO_Kraftstofffilter_Wasser : 40|1@1+ (1,0) [0|1] ""  Gateway_MQB
 SG_ SCR_Systemfehler : 41|1@1+ (1,0) [0|1] ""  Gateway_MQB
 SG_ SCR_Inducement_Strategie : 42|2@1+ (1,0) [0|3] ""  Gateway_MQB
 SG_ MO_CO2_Faktor : 44|12@1+ (1,0) [1|4094] "Unit_GramPerLiter"  Gateway_MQB
 SG_ MO_MKB_MUX M : 56|2@1+ (1,0) [0|3] ""  Gateway_MQB
 SG_ MO_MKB_01 m0 : 59|5@1+ (1,0) [0|31] ""  Gateway_MQB
 SG_ MO_MKB_02 m1 : 59|5@1+ (1,0) [0|31] ""  Gateway_MQB
 SG_ MO_MKB_03 m2 : 59|5@1+ (1,0) [0|31] ""  Gateway_MQB
 SG_ MO_MKB_04 m3 : 59|5@1+ (1,0) [0|31] ""  Gateway_MQB

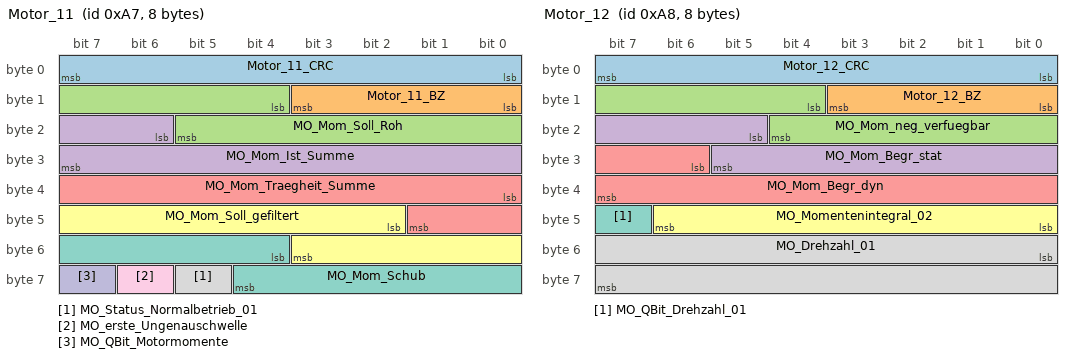
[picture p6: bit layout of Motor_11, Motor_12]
BO_ 167 Motor_11: 8 Motor_Diesel_MQB
 SG_ Motor_11_CRC : 0|8@1+ (1,0) [0|255] ""  Gateway_MQB,Getriebe_DQ_Hybrid_MQB,Getriebe_DQ_MQB
 SG_ Motor_11_BZ : 8|4@1+ (1,0) [0|15] ""  Gateway_MQB,Getriebe_DQ_Hybrid_MQB,Getriebe_DQ_MQB
 SG_ MO_Mom_Soll_Roh : 12|10@1+ (1,-509) [-509|509] "Unit_NewtoMeter"  Gateway_MQB,Getriebe_DQ_Hybrid_MQB,Getriebe_DQ_MQB
 SG_ MO_Mom_Ist_Summe : 22|10@1+ (1,-509) [-509|509] "Unit_NewtoMeter"  Gateway_MQB,Getriebe_DQ_Hybrid_MQB,Getriebe_DQ_MQB,SAK_MQB
 SG_ MO_Mom_Traegheit_Summe : 32|10@1+ (1,-509) [-509|509] "Unit_NewtoMeter"  Gateway_MQB,Getriebe_DQ_Hybrid_MQB,Getriebe_DQ_MQB
 SG_ MO_Mom_Soll_gefiltert : 42|10@1+ (1,-509) [-509|509] "Unit_NewtoMeter"  Gateway_MQB,Getriebe_DQ_Hybrid_MQB,Getriebe_DQ_MQB
 SG_ MO_Mom_Schub : 52|9@1+ (1,-509) [-509|0] "Unit_NewtoMeter"  Gateway_MQB,Getriebe_DQ_Hybrid_MQB,Getriebe_DQ_MQB
 SG_ MO_Status_Normalbetrieb_01 : 61|1@1+ (1,0) [0|1] ""  Gateway_MQB,Getriebe_DQ_Hybrid_MQB,Getriebe_DQ_MQB
 SG_ MO_erste_Ungenauschwelle : 62|1@1+ (1,0) [0|1] ""  Gateway_MQB
 SG_ MO_QBit_Motormomente : 63|1@1+ (1,0) [0|1] ""  Gateway_MQB,Getriebe_DQ_Hybrid_MQB,Getriebe_DQ_MQB

BO_ 168 Motor_12: 8 Motor_Diesel_MQB
 SG_ Motor_12_CRC : 0|8@1+ (1,0) [0|255] ""  Gateway_MQB,Getriebe_DQ_Hybrid_MQB,Getriebe_DQ_MQB,LEH_MQB
 SG_ Motor_12_BZ : 8|4@1+ (1,0) [0|15] ""  BMS_MQB,Gateway_MQB,Getriebe_DQ_Hybrid_MQB,Getriebe_DQ_MQB,LEH_MQB
 SG_ MO_Mom_neg_verfuegbar : 12|9@1+ (1,-509) [-509|0] "Unit_NewtoMeter"  Gateway_MQB
 SG_ MO_Mom_Begr_stat : 21|9@1+ (1,0) [0|509] "Unit_NewtoMeter"  Gateway_MQB,Getriebe_DQ_Hybrid_MQB,Getriebe_DQ_MQB
 SG_ MO_Mom_Begr_dyn : 30|10@1+ (1,-509) [-509|509] "Unit_NewtoMeter"  Gateway_MQB
 SG_ MO_Momentenintegral_02 : 40|7@1+ (1,0) [0|100] "Unit_PerCent"  Gateway_MQB,Getriebe_DQ_Hybrid_MQB,Getriebe_DQ_MQB
 SG_ MO_QBit_Drehzahl_01 : 47|1@1+ (1,0) [0|1] ""  BMS_MQB,Gateway_MQB,Getriebe_DQ_Hybrid_MQB,Getriebe_DQ_MQB,LEH_MQB
 SG_ MO_Drehzahl_01 : 48|16@1+ (0.25,0) [0|16383] "Unit_MinutInver"  BMS_MQB,Gateway_MQB,Getriebe_DQ_Hybrid_MQB,Getriebe_DQ_MQB,LEH_MQB,SAK_MQB

BO_ 958 Motor_14: 8 Motor_Diesel_MQB
 SG_ MO_StartStopp_Status : 12|2@1+ (1,0) [0|3] ""  Gateway_MQB,Getriebe_DQ_Hybrid_MQB,Getriebe_DQ_MQB
 SG_ MO_StartStopp_Wiederstart : 14|1@1+ (1,0) [0|1] ""  Gateway_MQB,Getriebe_DQ_Hybrid_MQB,Getriebe_DQ_MQB
 SG_ MO_StartStopp_Motorstopp : 15|1@1+ (1,0) [0|1] ""  Gateway_MQB,Getriebe_DQ_Hybrid_MQB,Getriebe_DQ_MQB
 SG_ MO_Freig_Reku : 16|2@1+ (1,0) [0|3] ""  Gateway_MQB
 SG_ MO_Kl_75 : 18|1@1+ (1,0) [0|1] ""  Gateway_MQB
 SG_ MO_Kl_50 : 19|1@1+ (1,0) [0|1] ""  Gateway_MQB,LEH_MQB
 SG_ MO_Gangposition : 20|4@1+ (1,0) [0|15] ""  Gateway_MQB
 SG_ MO_StartStopp_Fahrerwunsch : 24|2@1+ (1,0) [0|3] ""  Gateway_MQB,Getriebe_DQ_Hybrid_MQB,Getriebe_DQ_MQB
 SG_ MO_HYB_Fahrbereitschaft : 26|1@1+ (1,0) [0|1] ""  BMS_MQB,Gateway_MQB
 SG_ MO_Ext_E_Fahrt_aktiv : 27|1@1+ (1,0) [0|1] ""  Gateway_MQB
 SG_ MO_Fahrer_bremst : 28|1@1+ (1,0) [0|1] ""  Gateway_MQB,Getriebe_DQ_Hybrid_MQB,Getriebe_DQ_MQB
 SG_ MO_QBit_Fahrer_bremst : 29|1@1+ (1,0) [0|1] ""  Gateway_MQB,Getriebe_DQ_Hybrid_MQB,Getriebe_DQ_MQB
 SG_ MO_BLS : 30|1@1+ (1,0) [0|1] ""  Gateway_MQB,Getriebe_DQ_Hybrid_MQB,Getriebe_DQ_MQB
 SG_ MO_Konsistenz_Bremsped : 31|1@1+ (1,0) [0|1] ""  Gateway_MQB
 SG_ MO_Timeout_ESP : 32|1@1+ (1,0) [0|1] ""  Gateway_MQB
 SG_ MO_Klima_Eingr : 33|2@1+ (1,0) [0|3] ""  Gateway_MQB
 SG_ MO_Aussp_Anlass : 35|1@1+ (1,0) [0|1] ""  Gateway_MQB
 SG_ MO_Freig_Anlass : 36|1@1+ (1,0) [0|1] ""  Gateway_MQB
 SG_ MO_Kuppl_schalter : 37|1@1+ (1,0) [0|1] ""  Gateway_MQB
 SG_ MO_Interlock : 38|1@1+ (1,0) [0|1] ""  Gateway_MQB
 SG_ MO_Motor_laeuft : 39|1@1+ (1,0) [0|1] ""  Gateway_MQB,Getriebe_DQ_Hybrid_MQB,Getriebe_DQ_MQB
 SG_ MO_Kickdown : 40|1@1+ (1,0) [0|1] ""  Gateway_MQB,Getriebe_DQ_Hybrid_MQB,Getriebe_DQ_MQB
 SG_ MO_Status_Zylabschalt_01 : 41|1@1+ (1,0) [0|1] ""  Gateway_MQB
 SG_ MO_EKlKomLeiRed : 42|2@1+ (1,0) [0|3] ""  Gateway_MQB
 SG_ MO_Handshake_STH : 44|1@1+ (1,0) [0|1] ""  Gateway_MQB
 SG_ MO_BKV_Unterdruckwarnung : 45|1@1+ (1,0) [0|1] ""  Gateway_MQB
 SG_ MO_Freigabe_Segeln : 46|1@1+ (1,0) [0|1] ""  Gateway_MQB,Getriebe_DQ_Hybrid_MQB,Getriebe_DQ_MQB
 SG_ MO_PTC_Status : 47|3@1+ (1,0) [0|7] ""  Gateway_MQB
 SG_ MO_QBit_Gangposition : 50|1@1+ (1,0) [0|1] ""  Gateway_MQB
 SG_ MO_Signalquelle_Gangposition : 51|1@1+ (1,0) [0|1] ""  Gateway_MQB
 SG_ MO_Remotestart_Betrieb : 52|1@1+ (1,0) [0|1] ""  Gateway_MQB

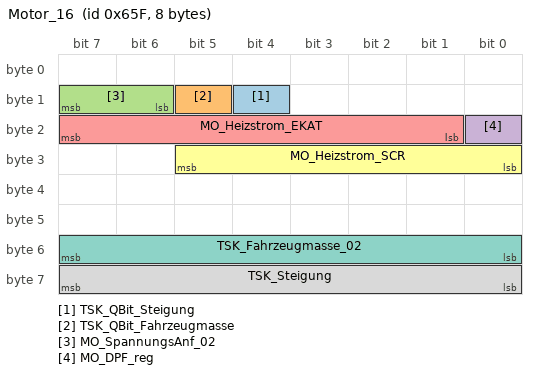
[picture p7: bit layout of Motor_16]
BO_ 1631 Motor_16: 8 Motor_Diesel_MQB
 SG_ TSK_QBit_Steigung : 12|1@1+ (1,0) [0|1] ""  Gateway_MQB,Getriebe_DQ_Hybrid_MQB,Getriebe_DQ_MQB
 SG_ TSK_QBit_Fahrzeugmasse : 13|1@1+ (1,0) [0|1] ""  Gateway_MQB,Getriebe_DQ_Hybrid_MQB,Getriebe_DQ_MQB
 SG_ MO_SpannungsAnf_02 : 14|2@1+ (1,0) [0|3] ""  Gateway_MQB
 SG_ MO_DPF_reg : 16|1@1+ (1,0) [0|1] ""  Gateway_MQB,Getriebe_DQ_Hybrid_MQB,Getriebe_DQ_MQB
 SG_ MO_Heizstrom_EKAT : 17|7@1+ (1,0) [0|126] "Unit_Amper"  Gateway_MQB
 SG_ MO_Heizstrom_SCR : 24|6@1+ (1,0) [0|62] "Unit_Amper"  Gateway_MQB
 SG_ TSK_Fahrzeugmasse_02 : 48|8@1+ (32,0) [0|8128] "Unit_KiloGram"  Gateway_MQB,Getriebe_DQ_Hybrid_MQB,Getriebe_DQ_MQB
 SG_ TSK_Steigung : 56|8@1+ (0.8,-101.6) [-101.6|101.6] "Unit_PerCent"  Gateway_MQB,Getriebe_DQ_Hybrid_MQB,Getriebe_DQ_MQB

BO_TX_BU_ 18 : Getriebe_DQ_Hybrid_MQB,Getriebe_DQ_MQB;
BO_TX_BU_ 2025 : Getriebe_DQ_Hybrid_MQB,Getriebe_DQ_MQB;
BO_TX_BU_ 2024 : Motor_Diesel_MQB,Motor_Hybrid_MQB,Motor_Otto_MQB;
BO_TX_BU_ 2549088375 : Getriebe_DQ_Hybrid_MQB,Getriebe_DQ_MQB;
BO_TX_BU_ 2549088374 : Motor_Diesel_MQB,Motor_Hybrid_MQB,Motor_Otto_MQB;
BO_TX_BU_ 2550006903 : Getriebe_DQ_Hybrid_MQB,Getriebe_DQ_MQB;
BO_TX_BU_ 2550006902 : Motor_Diesel_MQB,Motor_Hybrid_MQB,Motor_Otto_MQB;
BO_TX_BU_ 263 : Motor_Diesel_MQB,Motor_Hybrid_MQB,Motor_Otto_MQB;
BO_TX_BU_ 1600 : Motor_Diesel_MQB,Motor_Hybrid_MQB,Motor_Otto_MQB;
BO_TX_BU_ 1607 : Motor_Diesel_MQB,Motor_Hybrid_MQB,Motor_Otto_MQB;
BO_TX_BU_ 167 : Motor_Diesel_MQB,Motor_Hybrid_MQB,Motor_Otto_MQB;
BO_TX_BU_ 168 : Motor_Diesel_MQB,Motor_Hybrid_MQB,Motor_Otto_MQB;
BO_TX_BU_ 958 : Motor_Diesel_MQB,Motor_Hybrid_MQB,Motor_Otto_MQB;
BO_TX_BU_ 1631 : Motor_Diesel_MQB,Motor_Hybrid_MQB,Motor_Otto_MQB;
CM_ SG_ 299 GRA_ACC_01_CRC "Für MLB:
Berechnung siehe Lastenheft 'Kommunikationsabsicherung für FlexRay und CAN''

Ab MQB und MLBevo:
Berechnung siehe Lastenheft 'End-to-End Kommunikationsabsicherung''

Endwerte siehe Begleitdokument 'S-PDU Kennungsfolgen'";
CM_ SG_ 299 GRA_ACC_01_BZ "4bit Botschaftszaehler, wird mit jeder Sendebotschaft inkrementiert";
CM_ SG_ 299 GRA_Abbrechen "GRA : aus mit speichern
ACC : Soft aus";
CM_ SG_ 299 GRA_Limiter "Limiter setzen";
CM_ SG_ 299 GRA_Tip_Setzen "ACC : Tippschalter Set";
CM_ SG_ 299 GRA_Tip_Hoch "GRA : Tip Up 
ACC : Tip Up";
CM_ SG_ 299 GRA_Tip_Runter "GRA : Tip Down 
ACC : Tip Down";
CM_ SG_ 299 GRA_Tip_Wiederaufnahme "ACC : Tippschalter Wiederaufnahme";
CM_ SG_ 299 GRA_Verstellung_Zeitluecke "Verstellung der Zeitlücke für ACC

DIST -1 = Zeitluecke um 1 Stufe kleiner
DIST +1 = Zeitluecke um 1 Stufe groeßer";
CM_ SG_ 299 GRA_Fehler "0 = in Ordnung
1 = Fehler Bedienteil";
CM_ SG_ 299 GRA_Tip_Stufe_2 "Signal zeigt an, dass der zweistufige GRA/ACC-Hebel in der 2. Tip-Stufe betätigt wird. Das Signal wird nur gleichzeitig mit dem Signal GRA_Tip_Hoch oder GRA_Tip_Runter gesetzt, wobei die Bits GRA_Tip_Hoch bzw. GRA_Tip_Runter die Richtung der Hebelbetätigu";
CM_ BO_ 960 "MQB";
CM_ SG_ 960 Klemmen_Status_01_CRC "Für MLB:
Berechnung siehe Lastenheft 'Kommunikationsabsicherung für FlexRay und CAN''

Ab MQB und MLBevo:
Berechnung siehe Lastenheft 'End-to-End Kommunikationsabsicherung''

Endwerte siehe Begleitdokument 'S-PDU Kennungsfolgen'";
CM_ SG_ 960 Klemmen_Status_01_BZ "4bit Botschaftszaehler; wird in jeder Sendebotschaft inkrementiert";
CM_ SG_ 960 ZAS_Kl_S "Klemme S: S-Kontakt (Schluessel steckt)
";
CM_ SG_ 960 ZAS_Kl_15 "Klemme 15: Zuendung (SW-Kl.15)
";
CM_ SG_ 960 ZAS_Kl_X "Klemme 75
";
CM_ SG_ 960 ZAS_Kl_50 "Klemme 50: Startwunsch Fahrer
";
CM_ BO_ 949 "ab MQB 7.4";
CM_ SG_ 949 KL_Drehz_Anh "Drehzahlanhebung vom Motor angefordert

";
CM_ SG_ 949 KL_Vorwarn_Komp_ein "Vorwarnung Kompressor ein; 140ms vorher; Information für Motor zum Aufbau Momentenreserve";
CM_ SG_ 949 KL_AC_Schalter "AC Schalter
";
CM_ SG_ 949 KL_Komp_Moment_alt "Veraltet-Bit für Kompressor-Moment
";
CM_ SG_ 949 KL_Zonen "Mittelung der Anzahl an Klimazonen im Fahrzeug. (1 bis 4 Zonen)
";
CM_ SG_ 949 KL_Vorwarn_Zuheizer_ein "Vorwarnung Zuheizerbetrieb
";
CM_ SG_ 949 KL_Zustand "Betrieb Klimaanlage
";
CM_ SG_ 949 KL_Comp_rev_rq "Requested compressor revolution
over 8600 rpm = compressor stop";
CM_ SG_ 949 KL_Charisma_FahrPr "MLBevo: Aktuelles Fahrprogramm des Charisma-Teilnehmers (siehe Systemlastenheft Drive Select)
MQB: Istwert der Kennlinie (siehe Systemlastenheft MQB FPA)";
CM_ SG_ 949 KL_Charisma_Status "Charisma Systemstatus des Charisma-Teilnehmers

Wert 0x3 ist nur für Fahrzeuge ab MQB relevant";
CM_ SG_ 949 KL_Comp_enable "Enable to start for compressor
After 1 second when High-voltage becomes available, turn on '1'";
CM_ SG_ 949 KL_Last_Kompr "Verlustmoment der Klimaanlage

";
CM_ SG_ 949 KL_Spannungs_Anf "Mit diesem Signal kann die Klimaanlage den Spannungsvariationsbereich der Rekuperation z.B. bei hohen Lüfterstufen einschränken.

0 = keine Anforderung
1 = Spannungsanforderung 13,5 V
2 = Spanungsanforderung 14,7 V
3 = Rekuperation verboten";
CM_ SG_ 949 KL_Thermomanagement "Stufen des Thermomanagements";
CM_ SG_ 949 KL_StartStopp_Info "Stopp-Freigabe und Start-Anforderung an den Start-Stopp-Koordinator";
CM_ SG_ 949 KL_Anf_KL "Anforderung Kühlerlüfter der Klimaanlage in Prozent

";
CM_ SG_ 949 KL_el_Zuheizer_Stufe "Vorgabe für Motorsteuergeraet PTC-Stufe; im B8 nur Stufe 0...3
Nur für B8 und C7 relevant
";
CM_ SG_ 1625 EKL_KD_Fehler "Bei gesetztem Bit ist mindestens ein Kundendienstfehler eingetragen";
CM_ SG_ 1625 EKL_Comp_SCI_com_stat "'00' normal
x1' CAN_error (abnormal)
1x' Inverter_error";
CM_ SG_ 1625 EKL_Comp_output_stat "Diagnosis series 1 'Output'
0' normal
1' output line short
2' output line cut out
3' abnormal current detection";
CM_ SG_ 1625 EKL_Comp_main_stat "Real compressor status not CAN board status";
CM_ SG_ 1625 EKL_Comp_ovld_stat "Diagnosis series 1 'Over load'
0 normal
1 voltage restriction
2 current restriction
3 software over current
4 over load
6 over input current";
CM_ SG_ 1625 EKL_Comp_Inv_stat "Diagnosis series 2 'Startability'
0' normal
1' start fail
2' temperature protection
3' system abnormal stop";
CM_ SG_ 1625 EKL_Comp_photo_temp_stat "Diagnosis series 2 'Inverter temp.'
0' normal
1' over heat L
2' over heat S
3' sermister abnormal";
CM_ SG_ 1625 EKL_Comp_photo_temp "IGBT temp. measured by inverter.
Photo coupler temp. is not  measured in compressor temp. of IGBT (same as EK1_Comp_Inv_temp) will be sent";
CM_ SG_ 1625 EKL_Comp_current "Compressor input current";
CM_ SG_ 1625 EKL_Comp_rev_stat "compressor real revolution
0-8624 rpm is outputted
output = (actual speed + 25) / 50'   speed over 8625rpm: '172'";
CM_ SG_ 2549088277 Airbag_01_KompSchutz "Funktionseinschränkung aufgrund Komponentenschutz aktiv";
CM_ SG_ 2549088277 Airbag_01_Nachlauftyp "Abgebildet wird die von der Hardware vorgegebene Möglichkeit, die Kommunikation nach Klemme 15 = AUS aufrecht zu erhalten. Es wird ein Init-Wert gesendet.
0 = Kommunikation nur bei KL15=EIN (kein Nachlauf, nicht weckfähig)
1 = Kommunikation nach KL15=AU";
CM_ SG_ 2549088277 AB_KD_Fehler "Bei gesetztem Bit ist mindestens ein Kundendienstfehler eingetragen
";
CM_ SG_ 2549088380 EMotor_KompSchutz "Funktionseinschränkung aufgrund Komponentenschutz aktiv";
CM_ SG_ 2549088380 EMotor_Nachlauftyp "Abgebildet wird die von der Hardware vorgegebene Möglichkeit, die Kommunikation nach Klemme 15 = AUS aufrecht zu erhalten. Es wird ein Init-Wert gesendet.
0 = Kommunikation nur bei KL15=EIN (kein Nachlauf, nicht weckfähig)
1 = Kommunikation nach KL15=AU";
CM_ SG_ 2549088380 EM_HYB_KD_Fehler "Bei gesetztem Bit ist mindestens ein Kundendienstfehler eingetragen";
CM_ SG_ 2549088375 Getriebe_KompSchutz "Funktionseinschränkung aufgrund Komponentenschutz aktiv";
CM_ SG_ 2549088375 Getriebe_Nachlauftyp "Abgebildet wird die von der Hardware vorgegebene Möglichkeit, die Kommunikation nach Klemme 15 = AUS aufrecht zu erhalten. Es wird ein Init-Wert gesendet.
0 = Kommunikation nur bei KL15=EIN (kein Nachlauf, nicht weckfähig)
1 = Kommunikation nach KL15=AU";
CM_ SG_ 2549088375 GE_KD_Fehler "Status Kundendienst-Fehlerspeicher";
CM_ SG_ 2549088379 Hybrid_KompSchutz "Funktionseinschränkung aufgrund Komponentenschutz aktiv";
CM_ SG_ 2549088379 Hybrid_Nachlauftyp "Abgebildet wird die von der Hardware vorgegebene Möglichkeit, die Kommunikation nach Klemme 15 = AUS aufrecht zu erhalten. Es wird ein Init-Wert gesendet.
0 = Kommunikation nur bei KL15=EIN (kein Nachlauf, nicht weckfähig)
1 = Kommunikation nach KL15=AU";
CM_ SG_ 2549088379 BMS_HYB_KD_Fehler "Bei gesetztem Bit ist mindestens ein Kundendienstfehler eingetragen";
CM_ SG_ 2549088374 Motor_KompSchutz "Funktionseinschränkung aufgrund Komponentenschutz aktiv";
CM_ SG_ 2549088374 Motor_Nachlauftyp "Abgebildet wird die von der Hardware vorgegebene Möglichkeit, die Kommunikation nach Klemme 15 = AUS aufrecht zu erhalten. Es wird ein Init-Wert gesendet.
0 = Kommunikation nur bei KL15=EIN (kein Nachlauf, nicht weckfähig)
1 = Kommunikation nach KL15=AU";
CM_ SG_ 2549088374 MO_KD_Fehler "Kundendienstfehlerspeicherbit";
CM_ SG_ 2549088284 SAK_KompSchutz "Funktionseinschränkung aufgrund Komponentenschutz aktiv";
CM_ SG_ 2549088284 SAK_Nachlauftyp "Abgebildet wird die von der Hardware vorgegebene Möglichkeit, die Kommunikation nach Klemme 15 = AUS aufrecht zu erhalten. Es wird ein Init-Wert gesendet.
0 = Kommunikation nur bei KL15=EIN (kein Nachlauf, nicht weckfähig)
1 = Kommunikation nach KL15=AU";
CM_ SG_ 2549088284 SAK_KD_Fehler "Bei gesetztem Bit ist mindestens ein Kundendienstfehler eingetragen";
CM_ BO_ 779 "MQB";
CM_ SG_ 779 KBI_ABS_Lampe "ABS-Sicherheits-Lampe wurde eingeschaltet.";
CM_ SG_ 779 KBI_ESP_Lampe "ESP-Sicherheits-Lampe wurde eingeschaltet ";
CM_ SG_ 779 KBI_BKL_Lampe "Sicherheits-Lampe Bremskontrolle wurde eingeschaltet;
";
CM_ SG_ 779 KBI_Airbag_Lampe "Airbag Sicherheits-Lampe wurde eingeschaltet ";
CM_ SG_ 779 KBI_SILA_gueltig "Rückmeldeinformation (Bit 1-6) ist gültig";
CM_ SG_ 779 KBI_Lenkung_Lampe "Sicherheits-Lampe der Lenkung (Lenkhilfe EPS, Audi-Dynamic-Steering ...) wurde eingeschaltet.

0x0 = Lenkungs-Lampe aus
0x1 = Lenkungs-Lampe ein";
CM_ SG_ 779 KBI_Vorglueh_System_Lampe "Rückmeldung der Vorglühlampe bzw. Motor Systemlampe (MO_Systemlampe) an den Motor (bei Diesel und Otto!). Hardwaremässig gleiche LED im Kombi (EPC- oder Glühwendel), Unterscheidung nur über Ziffernblatt.";
CM_ SG_ 779 KBI_NV_in_Anzeige "Das Bit gibt dem NV die Information, ob NV-Bild im Kombi in der Anzeige ist. (Information ist notwendig um Kontrasverstellungen nur dann zuzulassen, wenn der Fahrer das Feedback über das  Kombidisplay bekommt.)";
CM_ SG_ 779 KBI_Anzeigestatus_ACC "Status der ACC-Anzeige im nicht permanenten Displaybereich";
CM_ SG_ 779 KBI_Anzeigestatus_GRA "Anzeigestatus der GRA High Wunschgeschwindigkeitsanzeige im Kombiinstrument.
Bei VW bedeutet 'nicht vorhanden' GRA-low fähig (LED immer verbaut).
0 = nicht vorhanden
1 = Wunschgeschwindigkeits-Anzeigemöglichkeit vorhanden
2 = reserviert
3 = Fehler (B";
CM_ SG_ 779 KBI_Oeldruck_Schalter "Das Signal bildet den Status des Öldrucks über den am Kombi angeschlossenen Öldruckschalter ab.";
CM_ SG_ 779 KBI_Tankwarnung "Fahrer wird gewarnt, dass er den Reservebereich erreicht hat. Fzg.spezifische Warnschwelle";
CM_ SG_ 779 KBI_MFA_v_Einheit_01 "Einheit der Geschwindigkeit, die vom Fahrer im Car-Menü gewählt wurde. Veränderliche Grösse, im Gegensatz zur Einheit des Tachokranzes.";
CM_ SG_ 779 KBI_im_Stellgliedtest "Kombi im Stellgliedtest, Signal muss eingelesen werden, um Fehlfunktion aufgrund der Bewegung der Stellglieder (Drehzahlmesser, Tacho) des Kombis zu verhindern";
CM_ SG_ 779 KBI_Variante_USA "In diesem Signal wird die HW-Variante des Kombis ausgegeben, ACC plausibilisiert auf dieses Signal hin seine US-Codierung";
CM_ SG_ 779 KBI_Oeldruckwarnung "Öldruckwarnung im Kombi aktiv";
CM_ SG_ 779 KBI_Handbremse "Handbremsen-Information vom Kombi";
CM_ SG_ 779 KBI_V_Digital "Ausgabe der im Kombi angezeigten digitalen Geschwindigkeit.

Einheit ist im KBI_MFA_v_Einheit_01 definiert";
CM_ SG_ 779 KBI_PLA_in_Anzeige "Das Signal wird als aktive Rückmeldung genutzt, ob die Info des PLA im Kombi angezeigt wird. Wenn nach Anforderung des Displays das Signal zweimal auf 0 ist, wird der Parkvorgang abgebrochen.
Ein Kombi, dass PLA Anzeige nicht unterstützt, schickt dauerha";
CM_ SG_ 779 KBI_Anzeigefehler_NV "Über dieses Signal teilt das Kombiinstrument dem Nightvision-Steuergerät mit, dass ein Fehler vom Kombiinstrument diagnostiziert wurde, der zur Abschaltung der Nightvision-Funktion führen muss.";
CM_ SG_ 779 KBI_Anzeigestatus_LIM "Anzeigestatus der Speedlimiter Wunschgeschwindigkeitsanzeige im Kombiinstrument (permanenter Anzeigebereich)
0 = nicht vorhanden
1 = Wunschgeschwindigkeits-Anzeigemöglichkeit vorhanden
2 = reserviert
3 = Fehler (Botschaftsüberwachung, Timeout, Akustik";
CM_ SG_ 779 KBI_angez_Geschw "Im Tacho angezeigte Geschwindigkeit inklusive der Voreilung

";
CM_ SG_ 779 KBI_Einheit_Tacho "Information, ob es sich um Meilen- oder Kmh-Kombi handelt, Einheit des Tachos entspricht dem Zifferblatt, Grösse ist nicht veränderlich";
CM_ SG_ 779 KBI_Konsistenz_ACC "Rückmeldung an ACC, dass die Botschaften zur Ansteuerung von Anzeigen nicht bzw. nicht konsistent empfangen wurden (Timeout-, BZ-, CHK- und DLC-Fehler)                                                                                                        ";
CM_ SG_ 779 KBI_Fehler_Anzeige_ACC "Rückmeldung an ACC, dass mindestens eine der ACC-relevanten Anzeigen -rote Fahrerübernahme, Mitteldisplay, Gong - fehlerhaft sind.";
CM_ SG_ 779 KBI_Anzeigefehler_SWA "Signal bezieht sich nur auf die SWA-Lampe, Vorhalt für Kombis mit SWA-Lampe. ";
CM_ SG_ 1719 KBI_Kilometerstand "Fehler wird ausgegeben, falls Kilometerstand nicht restaurierbar
";
CM_ SG_ 1719 KBI_Standzeit_02 "Zähler welcher die Standzeit des Motors wiedergibt.
Das Signal beschreibt den Anteil der Motor-Standzeit zwischen Zündung aus und nächstem Motorstart.";
CM_ SG_ 1719 KBI_Inhalt_Tank "Restmenge 2 bzw. 2,5l nicht auflösbar

";
CM_ SG_ 1719 KBI_FStatus_Tank "Signal wird gesetzt:

a) Während der Fehlerentprellzeit (20 s Entprellung)

b) Bei erkanntem Fehler wird der Tankinhalt während der laufenden KL15-Phase über den 
    Verbrauch zurückgerechnet. In dieser Zeit ist das Bit ebenfalls gesetzt. Nach einem";
CM_ SG_ 1719 KBI_QBit_Aussen_Temp_gef "0x0 = gültiger Wert
0x1 = Ersatz-, Init- oder Fehlerwert";
CM_ SG_ 2549874965 KS_Airbag_01_Req_Data "Komponentenschutz (Funktion 01h). Request mit NA des Slaves.";
CM_ SG_ 2550006037 KS_Airbag_01_Resp_Data "Komponentenschutz (Funktion 01h). Response mit eigener NA.";
CM_ BO_ 982 "MQB";
CM_ SG_ 982 Licht_hinten_01_BZ "überlaufender 4bit Botschaftszaehler; wird in jeder Sendebotschaft inkrementiert";
CM_ SG_ 982 BCM2_Bremsl_durch_ECD "Bremslicht (ECD-Bremsung)
";
CM_ SG_ 982 LH_Aussenlicht_def "Aussenlicht kann nicht mehr korrekt angesteuert werden (EEPROM Codierung kann nicht mehr ausgelesen werden)
";
CM_ SG_ 982 LH_Standlicht_H_aktiv "Standlicht hinten
";
CM_ SG_ 982 LH_Parklicht_HL_aktiv "Parklicht hinten links 
";
CM_ SG_ 982 LH_Parklicht_HR_aktiv "Parklicht hinten rechts 
";
CM_ SG_ 982 LH_Bremslicht_H_aktiv "Bremslicht hinten
";
CM_ SG_ 982 LH_Nebelschluss_aktiv "Nebelschlusslicht
";
CM_ SG_ 982 LH_Rueckfahrlicht_aktiv "Rueckfahrlicht
";
CM_ SG_ 982 LH_Blinker_HL_akt "Blinker hinten links
";
CM_ SG_ 982 LH_Blinker_HR_akt "Blinker hinten rechts
";
CM_ SG_ 982 LH_Blinker_li_def "Fehlerstatus Blinker hinten links
";
CM_ SG_ 982 LH_Bremsl_li_def "Fehlerstatus Bremslicht hinten links (Detektion Einzelausfall)
";
CM_ SG_ 982 LH_Schlusslicht_li_def "Fehlererkennung Schlusslicht hinten links
";
CM_ SG_ 982 LH_Rueckf_li_def "Fehlererkennung Rückfahrlicht hinten links
";
CM_ SG_ 982 LH_Nebel_li_def "Fehlererkennung Nebelschlusslicht hinten links
";
CM_ SG_ 982 LH_Schluss_Brems_Nebel_li_def "Signal wird gesetzt, wenn eine Unterbrechung oder  ein Kurzschluss am Lampenausgang für Schluss_Brems_Nebelschlusslicht erkannt wird.";
CM_ SG_ 982 LH_Schluss_Brems_Nebel_re_def "Signal wird gesetzt, wenn eine Unterbrechung oder  ein Kurzschluss am Lampenausgang für Schluss_Brems_Nebelschlusslicht erkannt wird.";
CM_ SG_ 982 LH_Schluss_Brems_li_def "Konfiguration SL+ BRL + PL links und SL+ BRL  links
";
CM_ SG_ 982 LH_Schluss_Nebel_li_def "Konfiguration SL + NSL links oder SL + NSL + PL links
";
CM_ SG_ 982 LH_SL_BRL_BLK_li_def "Konfiguration SL + BRL + BLK links oder SL + BRL + BLK + PL links
";
CM_ SG_ 982 LH_Brems_Blk_li_def "Konfiguration BRL + BLK links 
";
CM_ SG_ 982 LH_Blinker_re_def "Fehlerstatus Blinker hinten rechts
";
CM_ SG_ 982 LH_Bremsl_re_def "Fehlerstatus Bremslicht hinten rechts  (Detektion Einzelausfall)
";
CM_ SG_ 982 LH_Schlusslicht_re_def "Fehlererkennung Schlusslicht hinten rechts
";
CM_ SG_ 982 LH_Rueckf_re_def "Fehlererkennung Rückfahrlicht hinten rechts
";
CM_ SG_ 982 LH_Nebel_re_def "Fehlererkennung Nebelschlusslicht hinten rechts
";
CM_ SG_ 982 LH_Schluss_Brems_re_def "Konfiguration SL+ BRL + PL rechts und SL+ BRL  rechts
";
CM_ SG_ 982 LH_Schluss_Nebel_re_def "Konfiguration SL + NSL rechts oder SL + NSL + PL rechts
";
CM_ SG_ 982 LH_SL_BRL_BLK_re_def "Konfiguration SL + BRL + BLK rechts oder SL + BRL + BLK + PL rechts
";
CM_ SG_ 982 LH_Brems_Blk_re_def "Konfiguration BRL + BLK rechts
";
CM_ SG_ 982 LH_Kennzl_def "Fehlerstatus Kennzeichenbeleuchtung hinten
";
CM_ SG_ 982 LH_3_Bremsl_def "Fehlerstatus 3. Bremsleuchte
";
CM_ SG_ 982 LH_Nebel_mi_def "Fehlererkennung Nebelschlusslicht hinten Mitte


";
CM_ SG_ 982 LH_Rueckf_mi_def "Fehlererkennung Rückfahrlicht Mitte
";
CM_ SG_ 982 LH_Bremsl_li_ges_def "Fehlerstatus Bremslicht hinten links (Detektion Totalausfall)
";
CM_ SG_ 982 LH_Bremsl_re_ges_def "Fehlerstatus Bremslicht hinten links (Detektion Totalausfall)
";
CM_ BO_ 134 "ab MQB mit CRC in Byte 1";
CM_ SG_ 134 LWI_01_CRC "Für MLB:
Berechnung siehe Lastenheft 'Kommunikationsabsicherung für FlexRay und CAN''

Ab MQB und MLBevo:
Berechnung siehe Lastenheft 'End-to-End Kommunikationsabsicherung'

Endwerte siehe Begleitdokument 'S-PDU Kennungsfolgen'";
CM_ SG_ 134 LWI_QBit_Sub_Daten "Es gilt die Signalspezifikation laut LAH";
CM_ SG_ 134 LWI_QBit_Lenkradwinkel "Das QBit wird auch bei nicht abgeglichenem Lenkradwinkelsensor gesetzt";
CM_ SG_ 134 LWI_Lenkradwinkel "Wertebereich = +/- 800 Grad
Auflösung = 0,1 Grad
ACHTUNG: spezifizierte Interne Auflösung des Sensors beträgt aber nur Schrittweite 0,5 Grad!

Hinweis: Zusätzlich gestellte Winkel bei Dynamiklenkung beachten !";
CM_ SG_ 134 LWI_VZ_Lenkradwinkel "Vorzeichen Lenkradwinkel gemäss DIN70000; 
Nullstellung = +0";
CM_ SG_ 134 LWI_VZ_Lenkradw_Geschw "Vorzeichen Lenkradwinkelgeschwindigkeit gemäss DIN70000; 
Nullstellung = +0";
CM_ SG_ 134 LWI_Lenkradw_Geschw "Wertebereich = +/- 2500 Grad/s
Auflösung = 5 Grad/s

Hinweis: Zusätzlich gestellte Winkel bei Dynamiklenkung beachten !";
CM_ SG_ 134 LWI_Sub_Daten "Verschlüsseltes Datenpaket vom Sub-Rechner des LWS, Verwendung nur durch SCU und ESP_ADS
Verwendung gemäß 'Sicherheitsanforderungen an Empfängersteuergeräte'

Im B8 gilt die Signalspezifikation: LAH 8K0953B";
CM_ SG_ 263 MO_Istgang "Aktueller Gang für Anzeige Hochschaltempfehlung (gültig, wenn MO_Schaltempf_verfbar = 1).

Anzeige im Kombi:
Sollgang == Istgang         ==> Anzeige Istgang
Sollgang !=   Istgang         ==> Schaltempfehlung
Sollgang == Istgang == 0 ==> keine Anzeige";
CM_ SG_ 263 MO_Sollgang "Motor sendet den Sollgang in den der Fahrer schalten soll. Wird im Kombi als Hochschaltempfehlung hervorgehoben (gültig, wenn MO_Schaltempf_verfbar = 1).

Anzeige im Kombi:
Sollgang == Istgang          ==> Anzeige Istgang
Sollgang !=  Istgang         ";
CM_ SG_ 263 MO_Oeldruck "Öldruck analog zur Anzeige";
CM_ SG_ 263 MO_Anzeigedrehz "Optimierte Anzeigedrehzahl wegen sportlicherem Drehzahlmesser im Kombi. 
Bei Parallelhybrid: Anzeige VKM- Drehzahl nach Anzeigekonzept";
CM_ SG_ 263 MO_Schaltempf_verfbar "Info, ob Schaltempfehlung im Fzg. verfügbar. Statischer Wert, ändert sich für ein Fzg. nicht!";
CM_ SG_ 263 MO_Ladedruck "Zur Anzeige im Kombi, z.Zt. nur Porsche Colorado und PQ35 Biturbo, ab B8 Vorhalt";
CM_ SG_ 263 MO_KVS "Motorsteuergerätinterner Verbrauchszähler, der vom Kombi zyklisch ausgelesen wird, um die Einspritzmenge zur Verbrauchsmessung aufzusummieren; aus diesem Zählerstand werden Momentan- und Durchschnittsverbrauch berechnet; das Überlauf-Bit ist zu berücksich";
CM_ SG_ 263 MO_KVS_Ueberlauf "Der motorsteuergeräteinterne Verbrauchszähler ist mindestens einmal übergelaufen. Dieses Bit wird genutzt, um erkennen zu können, daß das Motorsteuergerät aus dem Reset-Zustand hochläuft.";
CM_ SG_ 1600 MO_QBit_Ansaugluft_Temp "
";
CM_ SG_ 1600 MO_QBit_Kuehlmittel_Temp "
";
CM_ SG_ 1600 MO_Stellgliedtest_Soundaktuator "Ansteuerung des Stellgliedtest";
CM_ SG_ 1600 MO_HYB_Fehler_HV_Netz "Im HV-Bordnetz ist fehlerbedingt kein generatorischer Betrieb möglich. Das 12V-Bordnetz wird über den DC/DC-Wandler allein aus der Traktionsbatterie gespeist. Um diesen Zustand möglichst lange aufrechterhalten zu können, sollten Komfort-Verbraucher abgesc";
CM_ SG_ 1600 MO_aktives_Getriebeheizen "Information für Getriebe, ob ein Ventil für Getriebheizen angesteuert werden muss";
CM_ SG_ 1600 MO_Absperrventil_oeffnen "Signal an Klima-SG das Absperrrventil anzusteuern. Ab D4 auch 0x3 Ventil_schließen.

Im MQB wird hier der Soll-Status des Absperrventils ausgegeben.
Achtung: bei z. B. klemmendem Ventil entspricht das Signal nicht dem tatsächlichen Status!";
CM_ SG_ 1600 MO_Ansaugluft_Temp "In Fahrzeugen ohne Außentemperatur vom Kombi kann aus der Ansauglufttemperatur auf die Außentemperatur geschlossen werden. Beim SDI ist das mit einer gewissen Genauigkeit gegeben. Genutzt wird es vom ASG.";
CM_ SG_ 1600 MO_Oel_Temp "Realer Meßbereich ca. -40..150 Grad";
CM_ SG_ 1600 MO_Kuehlmittel_Temp "Kuehlmitteltemperatur";
CM_ SG_ 1600 MO_Hoeheninfo "Korrekturfaktor Höhe (1 entspricht 1013 mbar)";
CM_ SG_ 1600 MO_Kennfeldk "Die Kennfeldkühlung ist in diesem Fahrzeug verbaut und hat keinen Systemfehler";
CM_ SG_ 1600 MO_Versionsinfo "Versioninformation vom Motor zur Steuerung bei inkompatiblen KMatrix-Änderung bzw. Einführung von neuen Funktionen, die in den Empfängern verriegelt werden müssen. Zu jedem Ereignis wird ein fixer Zählerstand zugeordnet, um dem Empfänger die funktionale Ä";
CM_ SG_ 1600 MO_Getriebe_kuehlen "Anforderung Getriebekühlventilansteuerung";
CM_ SG_ 1600 MO_Mom_Traegheit_02 "Massenträgheit des Motors (J) in kgm²
Bei Handschaltern wird das Zweimassenschwungrad mit berücksichtigt.
Bei eingebautem Getriebesteuergerät wird nur das Motorträgheitsmoment angegeben (Ohne Anteile des Massenschwungrades).";
CM_ SG_ 1600 MO_Heizungspumpenansteuerung "Anforderung Heizungspumpenansteuerung
MQB und Hybrid: Status der Heizungsunterstützungspumpe am MSG
";
CM_ SG_ 1600 MO_SpannungsAnf "Forderung des Motor-SGs zur Spannungsanhebung";
CM_ SG_ 1600 MO_Nachlaufzeit_Heizungspumpe "Nachlaufzeit für Heizungspumpe für Turboladerschutz";
CM_ SG_ 1607 MO_ITM_Kuehlmittel_Temp "Kuehlmitteltemperatur: Ersatzkühlmitteltemperatur für Motoren mit ITM (Thermomanagement)";
CM_ SG_ 1607 MO_E85_Sensor "Information über den E85 Gehalt (%-mass.) im Ottokraftstoff";
CM_ SG_ 1607 MO_Kraftstofffilter_Wasser "Für Schlechtkraftstoffländer wird das Wasserabscheidevolumen im Dieselkraftstofffilter mit einem  Wassersensor überwacht. Ist das Volumen erschöpft, erfolgt im Kombi eine entsprechende Anzeige.";
CM_ SG_ 1607 SCR_Systemfehler "Ansteuerung Anzeige für SCR-Systemfehler";
CM_ SG_ 1607 SCR_Inducement_Strategie "Art des Motor-Inducement-Konzepts. Abhängig von diesem Signal sind die Warntexte zwischen 'Kein Motorstart (in...km)' und 'eingeschränkte Fahrbarkeit (in ...km)' auszuwählen.";
CM_ SG_ 1607 MO_CO2_Faktor "dynamischer Umrechnungsfaktor von l in CO2";
CM_ SG_ 1607 MO_MKB_MUX "Die vier Motorkennbuchstaben werden gemultiplext in MO_MKB übertragen. Das Signal MO_MKB_MUX stellt das Steuersignal für diesen Multiplexer dar.";
CM_ SG_ 1607 MO_MKB_01 "Motorkennbuchstabe 1";
CM_ SG_ 1607 MO_MKB_02 "Motorkennbuchstabe 2";
CM_ SG_ 1607 MO_MKB_03 "Motorkennbuchstabe 3";
CM_ SG_ 1607 MO_MKB_04 "Motorkennbuchstabe 4";
CM_ SG_ 167 Motor_11_CRC "Für MLB:
Berechnung siehe Lastenheft 'Kommunikationsabsicherung für FlexRay und CAN''

Ab MQB und MLBevo:
Berechnung siehe Lastenheft 'End-to-End Kommunikationsabsicherung''

Endwerte siehe Begleitdokument 'S-PDU Kennungsfolgen'";
CM_ SG_ 167 MO_Mom_Soll_Roh "Faktor in MO_Faktor_Momente_02 in Motor_Code_01 beachten!
Momentenanforderung aus Fahrpedal bzw. von ACC/GRA bzw. aus dem Leerlaufregler (quasistatischer Anteil) bzw. aus Rekuperationsanforderung; keine Begrenzungen, keine Filterungen, keine Abbildung ex";
CM_ SG_ 167 MO_Mom_Ist_Summe "Faktor in MO_Faktor_Momente_02 in Motor_Code_01 beachten!
Ist-Moment als Summe aus Verbrennungsmotor und E-Motor (bei Hybrid-Konzepten) incl. allen Eingriffen und Korrekturen; definiert als Kupplungsmoment an Kurbelwelle nach Abgriff der Nebenaggregate";
CM_ SG_ 167 MO_Mom_Traegheit_Summe "Faktor in MO_Faktor_Momente_02 in Motor_Code_01 beachten!
Moment, das zur Beschleunigung der trägen Massen aufgewendet wird bzw. frei wird; Summen aus Anteilen für Verbrennungsmotor und E-Motor (in Abhängigkeit davon, ob angekoppelt oder nicht); definier";
CM_ SG_ 167 MO_Mom_Soll_gefiltert "Faktor in MO_Faktor_Momente_02 in Motor_Code_01 beachten!
MO_Mom_Soll_Roh nach Fahrverhaltensfilter, begrenzt nach oben mit MO_Mom_Begr_dyn, begrenzt nach unten mit Brenngrenze (wenn Motor brennt); Einrechnung der plausibilisierten Bremsen-Eingriffe; ohn";
CM_ SG_ 167 MO_Mom_Schub "Faktor in MO_Faktor_Momente_02 in Motor_Code_01 beachten!
Moment das sich einstellt, wenn der Fahrer 0% Fahrpedal gibt; bei konventionellen Projekten = alle Verluste (mechanische Reibung und sonstige Verluste) des Verbrennungsmotors + Momentenaufnahme de";
CM_ SG_ 167 MO_Status_Normalbetrieb_01 "Das Motorsteuergerät sendet das Informationsbit, wenn die Initialisierungsphase des Steuergerätes abgeschlossen ist. Zusätzlich muss die Klemme 15 eingeschalten sein und eine applizierbare Mindestdrehzahlschwelle (Kennlinie in Abh. von der Kühlwassertempe";
CM_ SG_ 167 MO_erste_Ungenauschwelle "Zusätzliche Ungenauigkeit (zur Grundungenauigkeit). Motormomente ungenau >8% (kleinste Ungenauschwelle)
";
CM_ SG_ 167 MO_QBit_Motormomente "AUDI D4: Zykluszeit: 10ms (siehe Zykluszeit schnell/Cycletime Fast)

Ungenaue Momentenangaben, weil die Momente aus Ersatzwerten berechnet wurden (z.B. HFM ausgefallen). Qualifizierungsbit für die Motormomente.

Achtung:
Reduktion der Zykluszeit Moto";
CM_ BO_ 168 "Teil 2 neue Momentenschnittstelle MLB";
CM_ SG_ 168 Motor_12_CRC "Für MLB:
Berechnung siehe Lastenheft 'Kommunikationsabsicherung für FlexRay und CAN''

Ab MQB und MLBevo:
Berechnung siehe Lastenheft 'End-to-End Kommunikationsabsicherung'

Endwerte siehe Begleitdokument 'S-PDU Kennungsfolgen'";
CM_ SG_ 168 MO_Mom_neg_verfuegbar "Faktor in MO_Faktor_Momente_02 in Motor_Code_01 beachten!
Bei aktueller Drehzahl im nächsten Task (bei CAN-Übertragung z.B. 10ms) tatsächlich verfügbares negatives Moment (Summe aus Verlusten des Verbrennungsmotor und neg. E-Motor-Moment), zeigt Begrenzu";
CM_ SG_ 168 MO_Mom_Begr_stat "Faktor in MO_Faktor_Momente_02 in Motor_Code_01 beachten!
Bei aktueller Drehzahl max. mögliches Moment (Summe aus Verbrennungsmotor und E-Motor) aus stat. Vollastkurve, korrigiert für aktuelle Umgebungsbedingungen (Luftdruck/Höhe, Ansaugluft-Temperatur),";
CM_ SG_ 168 MO_Mom_Begr_dyn "Faktor in MO_Faktor_Momente_02 in Motor_Code_01 beachten!
Bei aktueller Drehzahl im nächsten Task (bei CAN-Übertragung z.B. 10ms) max. mögliches Moment (Summe aus Verbrennungsmotor und E-Motor), zeigt alle MSG-internen Begrenzungen (u.a. Rauchbegrenzung,";
CM_ SG_ 168 MO_Momentenintegral_02 "100  %  entspricht volle Verfügbarkeit aktuell vorhanden. 0 % entspricht Integral bis Limit gefüllt, erhöhender Eingriff kann aktuell nicht berücksichtigt werden oder aufgrund eines Fehlers nicht verfügbar
";
CM_ SG_ 168 MO_QBit_Drehzahl_01 "AUDI D4: Zykluszeit: 10ms (siehe Zykluszeit schnell/Cycletime Fast)

Achtung:
Reduktion der Zykluszeit Motor_03 auf 10ms geplant.
Projektabhängig soll künftig mit 10ms gesendet werden.
Empfänger die in weiteren Konzern-Projekten eingesetzt werden müs";
CM_ SG_ 168 MO_Drehzahl_01 "Im Fehlerfall wird die Motordrehzahl über die Nockenwellendrehzahl als Ersatzgrösse ausgegeben

Bei Parallelhybrid: Getriebeeingangsdrehzahl (=E-Maschinen Drehzahl)";
CM_ SG_ 958 MO_StartStopp_Status "Aktivitätsstatus Start/Stopp-Koordinator
HYBRID:
Wenn MO_Hybridfahrzeug = 1 gilt:
Signal bezieht sich nur auf den Verbrennungsmotor, nicht auf den Hybridantrieb
";
CM_ SG_ 958 MO_StartStopp_Wiederstart "Motorwiederstart durch Start/Stopp-Koordinator
HYBRID:
Wenn MO_Hybridfahrzeug =1 gilt:
Warnung vor Spannungseinbruch beim Zustart des Verbrennungsmotors. 
-nicht relevant, da derzeit kein Start über 12V-Starter geplant-
Dieses Signal wird nur vom Hyb";
CM_ SG_ 958 MO_StartStopp_Motorstopp "Motor-Stopp durch Start/Stopp-Koordinator
HYBRID:
Wenn MO_Hybridfahrzeug = 1 gilt:
Verbrennungsmotor durch Hybrid-Koordinator im MSG ausgeschaltet. 
Die definierten Start/Stopp-Signale beziehen sich nur auf den Verbrennungsmotor!";
CM_ SG_ 958 MO_Freig_Reku "Empfehlung des Motor-SG's zur Spannungsabsenkung/-anhebung für den Rekuperationsbetrieb";
CM_ SG_ 958 MO_Kl_75 "Klemme X
";
CM_ SG_ 958 MO_Kl_50 "Klemme 50: Startausführung Fahrer
";
CM_ SG_ 958 MO_Gangposition "MLB:
Stellung des Wählhebels in der Schaltgasse des Handschaltgetriebes.
MQB:
Abhängig vom Signal MO_Signalquelle_Gangposition: Stellung des Wählhebels in der Schaltgasse des Handschaltgetriebes aus Gangpositionssensor oder Modellwert aus Motordrehzahl";
CM_ SG_ 958 MO_StartStopp_Fahrerwunsch "Fahreraktivität Start/Stop";
CM_ SG_ 958 MO_HYB_Fahrbereitschaft "Signal steuert u.a. in der Lenkhilfe zusammen mit weiteren Informationen den Modewechsel in den 'Drivemode'
Grüne Anzeige im Kombiinstrument zur Signalisierung der Bereitschaft des Hybridsystems.";
CM_ SG_ 958 MO_Ext_E_Fahrt_aktiv "Funktionsrückmeldung zum erw. E-Fahr-Betrieb über Lampe/LED im E-Mode-Taster";
CM_ SG_ 958 MO_Fahrer_bremst "Redundante Bremsinformation vom Motor.";
CM_ SG_ 958 MO_BLS "Ungefiltertes Rohsignal des Bremslichtschalters, nur wenn HW-Eingang bestückt und ausgewertet wird. Bei Motoren ohne genutzten HW-Eingang wird kein Ersatzwert (bspw. SW-Signal über CAN) ausgegeben!
Bei AUDI muss das Signal wg. Bremslichtfunktion immer be";
CM_ SG_ 958 MO_Timeout_ESP "500 ms Timeout auf Bremsen-Botschaft ist >= 1 mal aufgelaufen, Löschen des Bits nach Neustart (KL15).";
CM_ SG_ 958 MO_Klima_Eingr "Eingriffe des Motor bei der Klima";
CM_ SG_ 958 MO_Aussp_Anlass "Bit wird gesetzt, wenn der Motorhochlauf ohne Anlasserunterstützung beendet werden kann oder ein Start-Timeout erreicht wurde.";
CM_ SG_ 958 MO_Freig_Anlass "Bit wird gesetzt, wenn der Motor beim Automatikstart gestartet werden darf (Motorstillstand, Emissionsmaßnahmen sind erfüllt).";
CM_ SG_ 958 MO_Kuppl_schalter "Nur Handschalter; aktiv, wenn Schalter verbaut; sonst konstant auf '0' gesetzt; Bit wird gesetzt, wenn Kupplungspedal betätigt wird (Kupplungsschalter hoch), Triebstrang kann noch eingekuppelt sein.";
CM_ SG_ 958 MO_Interlock "Das Motorsteuergerät gibt die Information aus, ab wann der Kupplungsschalter durch das Motorsteuergerät als getreten gesehen wird.
Bei Systemen für Start Stopp muss das Interlocksignal für einen Start durch das MSG generiert werden, sobald der Schalthebe";
CM_ SG_ 958 MO_Motor_laeuft "Das Motorsteuergerät gibt die Information aus, ab wann der Motor verbrennungsbedingt autark läuft und durch zuschaltbare Nebenaggregate mechanisch belastbar ist (z.B. durch Generator, Klimakompressor, etc.).

Die 'Motor läuft' Information wird ausgegebe";
CM_ SG_ 958 MO_Kickdown "Es gilt: Signalspec MO_Kickdown v1.0";
CM_ SG_ 958 MO_Status_Zylabschalt_01 "Statusbit: Motor ist in Zylinderabschaltregelung";
CM_ SG_ 958 MO_EKlKomLeiRed "Anforderung an die Klimasteuerung, die Leistungsaufnahme des E-Kompressors bei schlechtem SOC und in bestimmten Fahrsituationen zu begrenzen. (Das bereits bestehende Signal 'Klimakompressor aus' als stets umzusetzende Anforderung bleibt unverändert besteh";
CM_ SG_ 958 MO_Handshake_STH "Es gilt: Signalspec MO_Handshake v1.0

Handshake zwischen MSG und STH. Wenn das MSG die EKP aufgrund einer STH-Anforderung ansteuert und kein Fehlereintrag bzgl. EKP/KPE/NDR vorliegt, wird das Bit gesetzt.";
CM_ SG_ 958 MO_BKV_Unterdruckwarnung "Über die Unterdruckwarnung signalisiert das MSG dem ESP, dass kein ausreichender Unterdruck für den BKV zur Verfügung gestellt werden kann.";
CM_ SG_ 958 MO_Freigabe_Segeln "Freigabebit des Segelbetriebs im Getriebe. Bedingt durch bestimmte Diagnosen und Adaptionen des MSGs, die nur im Schub möglich sind, darf nicht jede Schubphase für einen Segelbetrieb genutzt werden. Eine Freigabe bleibt auch außerhalb einer Schubphase bes";
CM_ SG_ 958 MO_PTC_Status "Rückmeldung vom MSG zum aktuellen PTC-Status (stufiges PTC)";
CM_ SG_ 958 MO_QBit_Gangposition "Qualitätsbit zum Signal MO_Gangposition";
CM_ SG_ 958 MO_Signalquelle_Gangposition "Signalquelle des Signals MO_Gangposition
0: Signalquelle Gangpositionssensor
1: Signalquelle Modellwert (v/n)";
CM_ SG_ 958 MO_Remotestart_Betrieb "Das MSG ist für den Remotestartbetrieb bereit.
Nach Empfang des Kl.50 Freigabe Signals wird der Fahrzeugmotor gestartet und solange der Motor läuft, bleibt dieses Bit aktiv.";
CM_ SG_ 1631 MO_SpannungsAnf_02 "mehrstufige Anforderung des MSG zum Einstellen einer Mindestbordnetzspannung";
CM_ SG_ 1631 MO_DPF_reg "Regeneration Diesel-Partikel-Filter";
CM_ SG_ 1631 MO_Heizstrom_EKAT "Aktuelle Gesamtstromaufnahme des E-Katalysators";
CM_ SG_ 1631 MO_Heizstrom_SCR "Aktuelle Gesamtstromaufnahme der Tank-, Fördermodul- und Leitungsheizung des SCR-Systems";
CM_ SG_ 1631 TSK_Fahrzeugmasse_02 "Neue Definition ab D4
Fahrzeugmasse in kg. Das Signal dient der Anpassung der Sollbeschleunigung vom ACC


";
CM_ SG_ 1631 TSK_Steigung "Steigung in % Berg. Das Signal dient der Anpassung der Sollbeschleunigung vom ACC

Positive Werte > bergauf; 
Negative Werte < bergab

Fehler: Die Steigung aufgrund eines Fehlers (mit KD-Fehlereintrag) nicht mehr berechnet werden";
BA_DEF_ BO_  "GenMsgPDUConstants" STRING ;
BA_DEF_ BO_  "GenMsgAutoGenDsp" ENUM  "No","Yes";
BA_DEF_ BO_  "GenMsgAutoGenSnd" ENUM  "No","Yes";
BA_DEF_ BO_  "GenMsgCycleTime" INT 0 65535;
BA_DEF_ BO_  "GenMsgCycleTimeFast" INT 0 65535;
BA_DEF_ BO_  "GenMsgDelayTime" INT 0 100000;
BA_DEF_ BO_  "GenMsgILSupport" ENUM  "No","Yes";
BA_DEF_ BO_  "GenMsgNrOfRepetition" INT 0 100;
BA_DEF_ BO_  "GenMsgSendType" ENUM  "Cyclic","not_used","not_used","not_used","not_used","not_used","not_used","IfActive","NoMsgSendType";
BA_DEF_ BO_  "GenMsgStartDelayTime" INT 0 100000;
BA_DEF_ BO_  "NmMessage" ENUM  "No","Yes";
BA_DEF_ BO_  "NmhMessage" ENUM  "No","Yes";
BA_DEF_ BO_  "VAGTP20_API" HEX 0 255;
BA_DEF_ BO_  "VAGTP20_DynConnection" ENUM  "No","Yes";
BA_DEF_ BO_  "VAGTP20_DynSetup" ENUM  "No","Yes";
BA_DEF_ BO_  "VAGTP20_StatConnection" ENUM  "No","Yes";
BA_DEF_ BO_  "Timeoutzeit" INT 0 1000000;
BA_DEF_ BO_  "DiagRequest" ENUM  "No","Yes";
BA_DEF_ BO_  "DiagResponse" ENUM  "No","Yes";
BA_DEF_ BO_  "DiagState" ENUM  "No","Yes";
BA_DEF_ BO_  "GenMsgChkConstant" HEX 0 4095;
BA_DEF_ SG_  "GenSigAutoGenDsp" ENUM  "No","Yes";
BA_DEF_ SG_  "GenSigAutoGenSnd" ENUM  "No","Yes";
BA_DEF_ SG_  "GenSigEnvVarType" ENUM  "int","float","undef";
BA_DEF_ SG_  "GenSigInactiveValue" INT -2147483648 2147483647;
BA_DEF_ SG_  "GenSigSendType" ENUM  "Cyclic","OnWrite","OnWriteWithRepetition","OnChange","OnChangeWithRepetition","IfActive","IfActiveWithRepetition","NoSigSendType","OnChangeAndIfActive","OnChangeAndIfActiveWithRepetition";
BA_DEF_ SG_  "GenSigStartValue" INT -2147483648 2147483647;
BA_DEF_ SG_  "NWM-WakeupAllowed" ENUM  "No","Yes";
BA_DEF_ SG_  "GenSigFuncType" ENUM  "NoFunction","MsgCounter","CRC-8","XOR","XOR-2","DatedBit","SW-Kl15","CHK","Constant","Protocol";
BA_DEF_ SG_  "GenSigSwitchedByIgnition" ENUM  "No","Yes";
BA_DEF_ SG_  "Fehlerwert" HEX 0 2147483647;
BA_DEF_ SG_  "GenSigMissingSourceValue" HEX 0 2147483647;
BA_DEF_REL_ BU_SG_REL_  "GenSigTimeoutTime" INT 0 65535;
BA_DEF_DEF_  "GenMsgPDUConstants" "";
BA_DEF_DEF_  "GenMsgAutoGenDsp" "Yes";
BA_DEF_DEF_  "GenMsgAutoGenSnd" "Yes";
BA_DEF_DEF_  "GenMsgCycleTime" 0;
BA_DEF_DEF_  "GenMsgCycleTimeFast" 0;
BA_DEF_DEF_  "GenMsgDelayTime" 0;
BA_DEF_DEF_  "GenMsgILSupport" "No";
BA_DEF_DEF_  "GenMsgNrOfRepetition" 0;
BA_DEF_DEF_  "GenMsgSendType" "NoMsgSendType";
BA_DEF_DEF_  "GenMsgStartDelayTime" 0;
BA_DEF_DEF_  "NmMessage" "No";
BA_DEF_DEF_  "NmhMessage" "No";
BA_DEF_DEF_  "VAGTP20_API" 0;
BA_DEF_DEF_  "VAGTP20_DynConnection" "No";
BA_DEF_DEF_  "VAGTP20_DynSetup" "No";
BA_DEF_DEF_  "VAGTP20_StatConnection" "No";
BA_DEF_DEF_  "Timeoutzeit" 0;
BA_DEF_DEF_  "DiagRequest" "No";
BA_DEF_DEF_  "DiagResponse" "No";
BA_DEF_DEF_  "DiagState" "No";
BA_DEF_DEF_  "GenMsgChkConstant" 0;
BA_DEF_DEF_  "GenSigAutoGenDsp" "No";
BA_DEF_DEF_  "GenSigAutoGenSnd" "No";
BA_DEF_DEF_  "GenSigEnvVarType" "undef";
BA_DEF_DEF_  "GenSigInactiveValue" 0;
BA_DEF_DEF_  "GenSigSendType" "NoSigSendType";
BA_DEF_DEF_  "GenSigStartValue" 0;
BA_DEF_DEF_  "NWM-WakeupAllowed" "No";
BA_DEF_DEF_  "GenSigFuncType" "NoFunction";
BA_DEF_DEF_  "GenSigSwitchedByIgnition" "Yes";
BA_DEF_DEF_  "Fehlerwert" 0;
BA_DEF_DEF_  "GenSigMissingSourceValue" 0;
BA_DEF_DEF_REL_ "GenSigTimeoutTime" 0;
BA_ "GenMsgPDUConstants" BO_ 299 "0x6a,0x38,0xb4,0x27,0x22,0xef,0xe1,0xbb,0xf8,0x80,0x84,0x49,0xc7,0x9e,0x1e,0x2b";
BA_ "GenMsgSendType" BO_ 299 0;
BA_ "GenMsgILSupport" BO_ 299 1;
BA_ "GenMsgCycleTime" BO_ 299 30;
BA_ "GenMsgILSupport" BO_ 18 1;
BA_ "GenMsgILSupport" BO_ 19 1;
BA_ "GenMsgILSupport" BO_ 17 1;
BA_ "GenMsgILSupport" BO_ 21 1;
BA_ "GenMsgILSupport" BO_ 23 1;
BA_ "GenMsgILSupport" BO_ 25 1;
BA_ "DiagRequest" BO_ 1813 1;
BA_ "GenMsgAutoGenSnd" BO_ 1813 0;
BA_ "GenMsgAutoGenDsp" BO_ 1813 0;
BA_ "DiagResponse" BO_ 1919 1;
BA_ "GenMsgAutoGenSnd" BO_ 1919 0;
BA_ "GenMsgAutoGenDsp" BO_ 1919 0;
BA_ "DiagRequest" BO_ 2022 1;
BA_ "GenMsgAutoGenSnd" BO_ 2022 0;
BA_ "GenMsgAutoGenDsp" BO_ 2022 0;
BA_ "DiagResponse" BO_ 2030 1;
BA_ "GenMsgAutoGenSnd" BO_ 2030 0;
BA_ "GenMsgAutoGenDsp" BO_ 2030 0;
BA_ "DiagState" BO_ 1793 1;
BA_ "GenMsgAutoGenSnd" BO_ 1793 0;
BA_ "GenMsgAutoGenDsp" BO_ 1793 0;
BA_ "DiagState" BO_ 1794 1;
BA_ "GenMsgAutoGenSnd" BO_ 1794 0;
BA_ "GenMsgAutoGenDsp" BO_ 1794 0;
BA_ "DiagState" BO_ 1796 1;
BA_ "GenMsgAutoGenSnd" BO_ 1796 0;
BA_ "GenMsgAutoGenDsp" BO_ 1796 0;
BA_ "DiagState" BO_ 1797 1;
BA_ "GenMsgAutoGenSnd" BO_ 1797 0;
BA_ "GenMsgAutoGenDsp" BO_ 1797 0;
BA_ "DiagState" BO_ 1798 1;
BA_ "GenMsgAutoGenSnd" BO_ 1798 0;
BA_ "GenMsgAutoGenDsp" BO_ 1798 0;
BA_ "DiagState" BO_ 1799 1;
BA_ "GenMsgAutoGenSnd" BO_ 1799 0;
BA_ "GenMsgAutoGenDsp" BO_ 1799 0;
BA_ "DiagState" BO_ 1800 1;
BA_ "GenMsgAutoGenSnd" BO_ 1800 0;
BA_ "GenMsgAutoGenDsp" BO_ 1800 0;
BA_ "DiagState" BO_ 1801 1;
BA_ "GenMsgAutoGenSnd" BO_ 1801 0;
BA_ "GenMsgAutoGenDsp" BO_ 1801 0;
BA_ "DiagState" BO_ 1795 1;
BA_ "GenMsgAutoGenSnd" BO_ 1795 0;
BA_ "GenMsgAutoGenDsp" BO_ 1795 0;
BA_ "DiagState" BO_ 1792 1;
BA_ "GenMsgAutoGenSnd" BO_ 1792 0;
BA_ "GenMsgAutoGenDsp" BO_ 1792 0;
BA_ "DiagState" BO_ 2015 1;
BA_ "GenMsgAutoGenSnd" BO_ 2015 0;
BA_ "GenMsgAutoGenDsp" BO_ 2015 0;
BA_ "DiagRequest" BO_ 2017 1;
BA_ "GenMsgAutoGenSnd" BO_ 2017 0;
BA_ "GenMsgAutoGenDsp" BO_ 2017 0;
BA_ "DiagResponse" BO_ 2025 1;
BA_ "GenMsgAutoGenSnd" BO_ 2025 0;
BA_ "GenMsgAutoGenDsp" BO_ 2025 0;
BA_ "DiagRequest" BO_ 2021 1;
BA_ "GenMsgAutoGenSnd" BO_ 2021 0;
BA_ "GenMsgAutoGenDsp" BO_ 2021 0;
BA_ "DiagResponse" BO_ 2029 1;
BA_ "GenMsgAutoGenSnd" BO_ 2029 0;
BA_ "GenMsgAutoGenDsp" BO_ 2029 0;
BA_ "DiagRequest" BO_ 2016 1;
BA_ "GenMsgAutoGenSnd" BO_ 2016 0;
BA_ "GenMsgAutoGenDsp" BO_ 2016 0;
BA_ "DiagResponse" BO_ 2024 1;
BA_ "GenMsgAutoGenSnd" BO_ 2024 0;
BA_ "GenMsgAutoGenDsp" BO_ 2024 0;
BA_ "DiagRequest" BO_ 2018 1;
BA_ "GenMsgAutoGenSnd" BO_ 2018 0;
BA_ "GenMsgAutoGenDsp" BO_ 2018 0;
BA_ "DiagResponse" BO_ 2026 1;
BA_ "GenMsgAutoGenSnd" BO_ 2026 0;
BA_ "GenMsgAutoGenDsp" BO_ 2026 0;
BA_ "DiagRequest" BO_ 2023 1;
BA_ "GenMsgAutoGenSnd" BO_ 2023 0;
BA_ "GenMsgAutoGenDsp" BO_ 2023 0;
BA_ "DiagResponse" BO_ 2031 1;
BA_ "GenMsgAutoGenSnd" BO_ 2031 0;
BA_ "GenMsgAutoGenDsp" BO_ 2031 0;
BA_ "DiagRequest" BO_ 2020 1;
BA_ "GenMsgAutoGenSnd" BO_ 2020 0;
BA_ "GenMsgAutoGenDsp" BO_ 2020 0;
BA_ "DiagResponse" BO_ 2028 1;
BA_ "GenMsgAutoGenSnd" BO_ 2028 0;
BA_ "GenMsgAutoGenDsp" BO_ 2028 0;
BA_ "DiagRequest" BO_ 2019 1;
BA_ "GenMsgAutoGenSnd" BO_ 2019 0;
BA_ "GenMsgAutoGenDsp" BO_ 2019 0;
BA_ "DiagResponse" BO_ 2027 1;
BA_ "GenMsgAutoGenSnd" BO_ 2027 0;
BA_ "GenMsgAutoGenDsp" BO_ 2027 0;
BA_ "DiagRequest" BO_ 1820 1;
BA_ "GenMsgAutoGenSnd" BO_ 1820 0;
BA_ "GenMsgAutoGenDsp" BO_ 1820 0;
BA_ "DiagResponse" BO_ 1926 1;
BA_ "GenMsgAutoGenSnd" BO_ 1926 0;
BA_ "GenMsgAutoGenDsp" BO_ 1926 0;
BA_ "GenMsgPDUConstants" BO_ 960 "0xc3,0xc3,0xc3,0xc3,0xc3,0xc3,0xc3,0xc3,0xc3,0xc3,0xc3,0xc3,0xc3,0xc3,0xc3,0xc3";
BA_ "GenMsgChkConstant" BO_ 960 195;
BA_ "GenMsgSendType" BO_ 960 0;
BA_ "GenMsgILSupport" BO_ 960 1;
BA_ "GenMsgDelayTime" BO_ 960 10;
BA_ "GenMsgCycleTime" BO_ 960 100;
BA_ "GenMsgSendType" BO_ 949 0;
BA_ "GenMsgILSupport" BO_ 949 1;
BA_ "GenMsgCycleTime" BO_ 949 100;
BA_ "GenMsgSendType" BO_ 1625 0;
BA_ "GenMsgILSupport" BO_ 1625 1;
BA_ "GenMsgCycleTime" BO_ 1625 500;
BA_ "GenMsgSendType" BO_ 2549088277 0;
BA_ "GenMsgILSupport" BO_ 2549088277 1;
BA_ "GenMsgCycleTime" BO_ 2549088277 500;
BA_ "GenMsgSendType" BO_ 2549088380 0;
BA_ "GenMsgILSupport" BO_ 2549088380 1;
BA_ "GenMsgCycleTime" BO_ 2549088380 500;
BA_ "GenMsgSendType" BO_ 2549088375 0;
BA_ "GenMsgILSupport" BO_ 2549088375 1;
BA_ "GenMsgCycleTime" BO_ 2549088375 500;
BA_ "GenMsgSendType" BO_ 2549088379 0;
BA_ "GenMsgILSupport" BO_ 2549088379 1;
BA_ "GenMsgCycleTime" BO_ 2549088379 500;
BA_ "GenMsgSendType" BO_ 2549088374 0;
BA_ "GenMsgILSupport" BO_ 2549088374 1;
BA_ "GenMsgCycleTime" BO_ 2549088374 500;
BA_ "GenMsgSendType" BO_ 2549088284 0;
BA_ "GenMsgILSupport" BO_ 2549088284 1;
BA_ "GenMsgCycleTime" BO_ 2549088284 500;
BA_ "GenMsgSendType" BO_ 779 0;
BA_ "GenMsgILSupport" BO_ 779 1;
BA_ "GenMsgCycleTime" BO_ 779 50;
BA_ "GenMsgSendType" BO_ 1719 0;
BA_ "GenMsgILSupport" BO_ 1719 1;
BA_ "GenMsgCycleTime" BO_ 1719 1000;
BA_ "GenMsgSendType" BO_ 982 0;
BA_ "GenMsgILSupport" BO_ 982 1;
BA_ "GenMsgCycleTime" BO_ 982 100;
BA_ "GenMsgAutoGenSnd" BO_ 2549875733 0;
BA_ "GenMsgAutoGenDsp" BO_ 2549875733 0;
BA_ "GenMsgAutoGenSnd" BO_ 2550006805 0;
BA_ "GenMsgAutoGenDsp" BO_ 2550006805 0;
BA_ "GenMsgAutoGenSnd" BO_ 2549941257 0;
BA_ "GenMsgAutoGenDsp" BO_ 2549941257 0;
BA_ "GenMsgAutoGenSnd" BO_ 2549875836 0;
BA_ "GenMsgAutoGenDsp" BO_ 2549875836 0;
BA_ "GenMsgAutoGenSnd" BO_ 2550006908 0;
BA_ "GenMsgAutoGenDsp" BO_ 2550006908 0;
BA_ "GenMsgAutoGenSnd" BO_ 2549875831 0;
BA_ "GenMsgAutoGenDsp" BO_ 2549875831 0;
BA_ "GenMsgAutoGenSnd" BO_ 2550006903 0;
BA_ "GenMsgAutoGenDsp" BO_ 2550006903 0;
BA_ "GenMsgAutoGenSnd" BO_ 2549875835 0;
BA_ "GenMsgAutoGenDsp" BO_ 2549875835 0;
BA_ "GenMsgAutoGenSnd" BO_ 2550006907 0;
BA_ "GenMsgAutoGenDsp" BO_ 2550006907 0;
BA_ "GenMsgAutoGenSnd" BO_ 2549875830 0;
BA_ "GenMsgAutoGenDsp" BO_ 2549875830 0;
BA_ "GenMsgAutoGenSnd" BO_ 2550006902 0;
BA_ "GenMsgAutoGenDsp" BO_ 2550006902 0;
BA_ "GenMsgAutoGenSnd" BO_ 2549875740 0;
BA_ "GenMsgAutoGenDsp" BO_ 2549875740 0;
BA_ "GenMsgAutoGenSnd" BO_ 2550006812 0;
BA_ "GenMsgAutoGenDsp" BO_ 2550006812 0;
BA_ "GenMsgPDUConstants" BO_ 134 "0x86,0x86,0x86,0x86,0x86,0x86,0x86,0x86,0x86,0x86,0x86,0x86,0x86,0x86,0x86,0x86";
BA_ "GenMsgChkConstant" BO_ 134 134;
BA_ "GenMsgSendType" BO_ 134 0;
BA_ "GenMsgILSupport" BO_ 134 1;
BA_ "GenMsgCycleTime" BO_ 134 10;
BA_ "GenMsgSendType" BO_ 263 0;
BA_ "GenMsgILSupport" BO_ 263 1;
BA_ "GenMsgCycleTime" BO_ 263 20;
BA_ "GenMsgSendType" BO_ 1600 0;
BA_ "GenMsgILSupport" BO_ 1600 1;
BA_ "GenMsgCycleTime" BO_ 1600 500;
BA_ "GenMsgSendType" BO_ 1607 0;
BA_ "GenMsgILSupport" BO_ 1607 1;
BA_ "GenMsgCycleTime" BO_ 1607 500;
BA_ "GenMsgPDUConstants" BO_ 167 "0xd2,0x3d,0xcd,0x28,0x4c,0x14,0x22,0x4b,0x24,0xac,0xfa,0x55,0x66,0x80,0x0d,0x6c";
BA_ "GenMsgSendType" BO_ 167 0;
BA_ "GenMsgILSupport" BO_ 167 1;
BA_ "GenMsgCycleTime" BO_ 167 10;
BA_ "GenMsgPDUConstants" BO_ 168 "0x52,0x8c,0x50,0xee,0x4f,0xa6,0xcc,0xcf,0x7d,0x2f,0x98,0x6b,0x27,0x41,0x9f,0x93";
BA_ "Timeoutzeit" BO_ 168 500;
BA_ "GenMsgSendType" BO_ 168 0;
BA_ "GenMsgILSupport" BO_ 168 1;
BA_ "GenMsgCycleTime" BO_ 168 10;
BA_ "GenMsgSendType" BO_ 958 0;
BA_ "GenMsgILSupport" BO_ 958 1;
BA_ "GenMsgDelayTime" BO_ 958 10;
BA_ "GenMsgCycleTime" BO_ 958 100;
BA_ "GenMsgSendType" BO_ 1631 0;
BA_ "GenMsgILSupport" BO_ 1631 1;
BA_ "GenMsgCycleTime" BO_ 1631 500;
BA_ "GenSigFuncType" SG_ 299 GRA_ACC_01_CRC 2;
BA_ "GenSigSendType" SG_ 299 GRA_ACC_01_CRC 0;
BA_ "GenSigEnvVarType" SG_ 299 GRA_ACC_01_CRC 0;
BA_ "GenSigAutoGenSnd" SG_ 299 GRA_ACC_01_CRC 1;
BA_ "GenSigAutoGenDsp" SG_ 299 GRA_ACC_01_CRC 1;
BA_ "GenSigFuncType" SG_ 299 GRA_ACC_01_BZ 1;
BA_ "GenSigSendType" SG_ 299 GRA_ACC_01_BZ 0;
BA_ "GenSigEnvVarType" SG_ 299 GRA_ACC_01_BZ 0;
BA_ "GenSigAutoGenSnd" SG_ 299 GRA_ACC_01_BZ 1;
BA_ "GenSigAutoGenDsp" SG_ 299 GRA_ACC_01_BZ 1;
BA_ "GenSigSendType" SG_ 299 GRA_Hauptschalter 0;
BA_ "GenSigEnvVarType" SG_ 299 GRA_Hauptschalter 0;
BA_ "GenSigAutoGenSnd" SG_ 299 GRA_Hauptschalter 1;
BA_ "GenSigAutoGenDsp" SG_ 299 GRA_Hauptschalter 1;
BA_ "GenSigSendType" SG_ 299 GRA_Abbrechen 0;
BA_ "GenSigEnvVarType" SG_ 299 GRA_Abbrechen 0;
BA_ "GenSigAutoGenSnd" SG_ 299 GRA_Abbrechen 1;
BA_ "GenSigAutoGenDsp" SG_ 299 GRA_Abbrechen 1;
BA_ "GenSigSendType" SG_ 299 GRA_Typ_Hauptschalter 0;
BA_ "GenSigEnvVarType" SG_ 299 GRA_Typ_Hauptschalter 0;
BA_ "GenSigAutoGenSnd" SG_ 299 GRA_Typ_Hauptschalter 1;
BA_ "GenSigAutoGenDsp" SG_ 299 GRA_Typ_Hauptschalter 1;
BA_ "GenSigSendType" SG_ 299 GRA_Limiter 0;
BA_ "GenSigEnvVarType" SG_ 299 GRA_Limiter 0;
BA_ "GenSigAutoGenSnd" SG_ 299 GRA_Limiter 1;
BA_ "GenSigAutoGenDsp" SG_ 299 GRA_Limiter 1;
BA_ "GenSigSendType" SG_ 299 GRA_Tip_Setzen 0;
BA_ "GenSigEnvVarType" SG_ 299 GRA_Tip_Setzen 0;
BA_ "GenSigAutoGenSnd" SG_ 299 GRA_Tip_Setzen 1;
BA_ "GenSigAutoGenDsp" SG_ 299 GRA_Tip_Setzen 1;
BA_ "GenSigSendType" SG_ 299 GRA_Tip_Hoch 0;
BA_ "GenSigEnvVarType" SG_ 299 GRA_Tip_Hoch 0;
BA_ "GenSigAutoGenSnd" SG_ 299 GRA_Tip_Hoch 1;
BA_ "GenSigAutoGenDsp" SG_ 299 GRA_Tip_Hoch 1;
BA_ "GenSigSendType" SG_ 299 GRA_Tip_Runter 0;
BA_ "GenSigEnvVarType" SG_ 299 GRA_Tip_Runter 0;
BA_ "GenSigAutoGenSnd" SG_ 299 GRA_Tip_Runter 1;
BA_ "GenSigAutoGenDsp" SG_ 299 GRA_Tip_Runter 1;
BA_ "GenSigSendType" SG_ 299 GRA_Tip_Wiederaufnahme 0;
BA_ "GenSigEnvVarType" SG_ 299 GRA_Tip_Wiederaufnahme 0;
BA_ "GenSigAutoGenSnd" SG_ 299 GRA_Tip_Wiederaufnahme 1;
BA_ "GenSigAutoGenDsp" SG_ 299 GRA_Tip_Wiederaufnahme 1;
BA_ "GenSigSendType" SG_ 299 GRA_Verstellung_Zeitluecke 0;
BA_ "GenSigEnvVarType" SG_ 299 GRA_Verstellung_Zeitluecke 0;
BA_ "GenSigAutoGenSnd" SG_ 299 GRA_Verstellung_Zeitluecke 1;
BA_ "GenSigAutoGenDsp" SG_ 299 GRA_Verstellung_Zeitluecke 1;
BA_ "GenSigSendType" SG_ 299 GRA_Codierung 0;
BA_ "GenSigEnvVarType" SG_ 299 GRA_Codierung 0;
BA_ "GenSigAutoGenSnd" SG_ 299 GRA_Codierung 1;
BA_ "GenSigAutoGenDsp" SG_ 299 GRA_Codierung 1;
BA_ "GenSigSendType" SG_ 299 GRA_Fehler 0;
BA_ "GenSigEnvVarType" SG_ 299 GRA_Fehler 0;
BA_ "GenSigAutoGenSnd" SG_ 299 GRA_Fehler 1;
BA_ "GenSigAutoGenDsp" SG_ 299 GRA_Fehler 1;
BA_ "GenSigSendType" SG_ 299 GRA_Typ468 0;
BA_ "GenSigEnvVarType" SG_ 299 GRA_Typ468 0;
BA_ "GenSigAutoGenSnd" SG_ 299 GRA_Typ468 1;
BA_ "GenSigAutoGenDsp" SG_ 299 GRA_Typ468 1;
BA_ "GenSigSwitchedByIgnition" SG_ 299 GRA_Tip_Stufe_2 0;
BA_ "GenSigSendType" SG_ 299 GRA_Tip_Stufe_2 0;
BA_ "GenSigEnvVarType" SG_ 299 GRA_Tip_Stufe_2 0;
BA_ "GenSigSwitchedByIgnition" SG_ 18 WFS_GSG_RND 0;
BA_ "GenSigSendType" SG_ 18 WFS_GSG_RND 1;
BA_ "GenSigEnvVarType" SG_ 18 WFS_GSG_RND 0;
BA_ "GenSigAutoGenSnd" SG_ 18 WFS_GSG_RND 1;
BA_ "GenSigAutoGenDsp" SG_ 18 WFS_GSG_RND 1;
BA_ "GenSigSwitchedByIgnition" SG_ 18 WFS_GSG_CRC 0;
BA_ "GenSigEnvVarType" SG_ 18 WFS_GSG_CRC 0;
BA_ "GenSigAutoGenSnd" SG_ 18 WFS_GSG_CRC 1;
BA_ "GenSigAutoGenDsp" SG_ 18 WFS_GSG_CRC 1;
BA_ "GenSigSwitchedByIgnition" SG_ 19 WFS_IMMO_GSG_CRC 0;
BA_ "GenSigEnvVarType" SG_ 19 WFS_IMMO_GSG_CRC 0;
BA_ "GenSigAutoGenSnd" SG_ 19 WFS_IMMO_GSG_CRC 1;
BA_ "GenSigAutoGenDsp" SG_ 19 WFS_IMMO_GSG_CRC 1;
BA_ "GenSigSwitchedByIgnition" SG_ 19 WFS_IMMO_GSG_Status 0;
BA_ "GenSigSendType" SG_ 19 WFS_IMMO_GSG_Status 1;
BA_ "GenSigEnvVarType" SG_ 19 WFS_IMMO_GSG_Status 0;
BA_ "GenSigAutoGenSnd" SG_ 19 WFS_IMMO_GSG_Status 1;
BA_ "GenSigAutoGenDsp" SG_ 19 WFS_IMMO_GSG_Status 1;
BA_ "GenSigSwitchedByIgnition" SG_ 17 WFS_IMMO_MSG1_CRC 0;
BA_ "GenSigEnvVarType" SG_ 17 WFS_IMMO_MSG1_CRC 0;
BA_ "GenSigAutoGenSnd" SG_ 17 WFS_IMMO_MSG1_CRC 1;
BA_ "GenSigAutoGenDsp" SG_ 17 WFS_IMMO_MSG1_CRC 1;
BA_ "GenSigSwitchedByIgnition" SG_ 17 WFS_IMMO_MSG1_Status 0;
BA_ "GenSigSendType" SG_ 17 WFS_IMMO_MSG1_Status 1;
BA_ "GenSigEnvVarType" SG_ 17 WFS_IMMO_MSG1_Status 0;
BA_ "GenSigAutoGenSnd" SG_ 17 WFS_IMMO_MSG1_Status 1;
BA_ "GenSigAutoGenDsp" SG_ 17 WFS_IMMO_MSG1_Status 1;
BA_ "GenSigSwitchedByIgnition" SG_ 21 WFS_IMMO_MSG2_CRC 0;
BA_ "GenSigEnvVarType" SG_ 21 WFS_IMMO_MSG2_CRC 0;
BA_ "GenSigAutoGenSnd" SG_ 21 WFS_IMMO_MSG2_CRC 1;
BA_ "GenSigAutoGenDsp" SG_ 21 WFS_IMMO_MSG2_CRC 1;
BA_ "GenSigSwitchedByIgnition" SG_ 21 WFS_IMMO_MSG2_Status 0;
BA_ "GenSigSendType" SG_ 21 WFS_IMMO_MSG2_Status 1;
BA_ "GenSigEnvVarType" SG_ 21 WFS_IMMO_MSG2_Status 0;
BA_ "GenSigAutoGenSnd" SG_ 21 WFS_IMMO_MSG2_Status 1;
BA_ "GenSigAutoGenDsp" SG_ 21 WFS_IMMO_MSG2_Status 1;
BA_ "GenSigSwitchedByIgnition" SG_ 23 WFS_IMMO_MSG3_CRC 0;
BA_ "GenSigEnvVarType" SG_ 23 WFS_IMMO_MSG3_CRC 0;
BA_ "GenSigAutoGenSnd" SG_ 23 WFS_IMMO_MSG3_CRC 1;
BA_ "GenSigAutoGenDsp" SG_ 23 WFS_IMMO_MSG3_CRC 1;
BA_ "GenSigSwitchedByIgnition" SG_ 23 WFS_IMMO_MSG3_Status 0;
BA_ "GenSigSendType" SG_ 23 WFS_IMMO_MSG3_Status 1;
BA_ "GenSigEnvVarType" SG_ 23 WFS_IMMO_MSG3_Status 0;
BA_ "GenSigAutoGenSnd" SG_ 23 WFS_IMMO_MSG3_Status 1;
BA_ "GenSigAutoGenDsp" SG_ 23 WFS_IMMO_MSG3_Status 1;
BA_ "GenSigSwitchedByIgnition" SG_ 25 WFS_IMMO_MSG4_CRC 0;
BA_ "GenSigEnvVarType" SG_ 25 WFS_IMMO_MSG4_CRC 0;
BA_ "GenSigAutoGenSnd" SG_ 25 WFS_IMMO_MSG4_CRC 1;
BA_ "GenSigAutoGenDsp" SG_ 25 WFS_IMMO_MSG4_CRC 1;
BA_ "GenSigSwitchedByIgnition" SG_ 25 WFS_IMMO_MSG4_Status 0;
BA_ "GenSigSendType" SG_ 25 WFS_IMMO_MSG4_Status 1;
BA_ "GenSigEnvVarType" SG_ 25 WFS_IMMO_MSG4_Status 0;
BA_ "GenSigAutoGenSnd" SG_ 25 WFS_IMMO_MSG4_Status 1;
BA_ "GenSigAutoGenDsp" SG_ 25 WFS_IMMO_MSG4_Status 1;
BA_ "GenSigSwitchedByIgnition" SG_ 1813 ISO_Airbag_01_Req_Data 0;
BA_ "GenSigSendType" SG_ 1813 ISO_Airbag_01_Req_Data 3;
BA_ "GenSigEnvVarType" SG_ 1813 ISO_Airbag_01_Req_Data 0;
BA_ "GenSigSwitchedByIgnition" SG_ 1919 ISO_Airbag_01_Resp_Data 0;
BA_ "GenSigSendType" SG_ 1919 ISO_Airbag_01_Resp_Data 3;
BA_ "GenSigEnvVarType" SG_ 1919 ISO_Airbag_01_Resp_Data 0;
BA_ "GenSigSwitchedByIgnition" SG_ 2022 ISO_EMotor_01_Req_Data 0;
BA_ "GenSigSendType" SG_ 2022 ISO_EMotor_01_Req_Data 3;
BA_ "GenSigEnvVarType" SG_ 2022 ISO_EMotor_01_Req_Data 0;
BA_ "GenSigSwitchedByIgnition" SG_ 2030 ISO_EMotor_01_Resp_Data 0;
BA_ "GenSigSendType" SG_ 2030 ISO_EMotor_01_Resp_Data 3;
BA_ "GenSigEnvVarType" SG_ 2030 ISO_EMotor_01_Resp_Data 0;
BA_ "GenSigSwitchedByIgnition" SG_ 1793 ISO_01_Req_Data 0;
BA_ "GenSigSendType" SG_ 1793 ISO_01_Req_Data 3;
BA_ "GenSigEnvVarType" SG_ 1793 ISO_01_Req_Data 0;
BA_ "GenSigSwitchedByIgnition" SG_ 1794 ISO_02_Req_Data 0;
BA_ "GenSigSendType" SG_ 1794 ISO_02_Req_Data 3;
BA_ "GenSigEnvVarType" SG_ 1794 ISO_02_Req_Data 0;
BA_ "GenSigSwitchedByIgnition" SG_ 1796 ISO_04_Req_Data 0;
BA_ "GenSigSendType" SG_ 1796 ISO_04_Req_Data 3;
BA_ "GenSigEnvVarType" SG_ 1796 ISO_04_Req_Data 0;
BA_ "GenSigSwitchedByIgnition" SG_ 1797 ISO_05_Req_Data 0;
BA_ "GenSigSendType" SG_ 1797 ISO_05_Req_Data 3;
BA_ "GenSigEnvVarType" SG_ 1797 ISO_05_Req_Data 0;
BA_ "GenSigSwitchedByIgnition" SG_ 1798 ISO_06_Req_Data 0;
BA_ "GenSigSendType" SG_ 1798 ISO_06_Req_Data 3;
BA_ "GenSigEnvVarType" SG_ 1798 ISO_06_Req_Data 0;
BA_ "GenSigSwitchedByIgnition" SG_ 1799 ISO_07_Req_Data 0;
BA_ "GenSigSendType" SG_ 1799 ISO_07_Req_Data 3;
BA_ "GenSigEnvVarType" SG_ 1799 ISO_07_Req_Data 0;
BA_ "GenSigSwitchedByIgnition" SG_ 1800 ISO_08_Req_Data 0;
BA_ "GenSigSendType" SG_ 1800 ISO_08_Req_Data 3;
BA_ "GenSigEnvVarType" SG_ 1800 ISO_08_Req_Data 0;
BA_ "GenSigSwitchedByIgnition" SG_ 1801 ISO_09_Req_Data 0;
BA_ "GenSigSendType" SG_ 1801 ISO_09_Req_Data 3;
BA_ "GenSigEnvVarType" SG_ 1801 ISO_09_Req_Data 0;
BA_ "GenSigSwitchedByIgnition" SG_ 1795 ISO_Functionaler_Req_Aggregate 0;
BA_ "GenSigSendType" SG_ 1795 ISO_Functionaler_Req_Aggregate 3;
BA_ "GenSigEnvVarType" SG_ 1795 ISO_Functionaler_Req_Aggregate 0;
BA_ "GenSigSwitchedByIgnition" SG_ 1792 ISO_ALL_01_Req_Data 0;
BA_ "GenSigSendType" SG_ 1792 ISO_ALL_01_Req_Data 3;
BA_ "GenSigEnvVarType" SG_ 1792 ISO_ALL_01_Req_Data 0;
BA_ "GenSigSwitchedByIgnition" SG_ 2015 ISO_OBD_Funktionaler_Req_Data 0;
BA_ "GenSigSendType" SG_ 2015 ISO_OBD_Funktionaler_Req_Data 3;
BA_ "GenSigEnvVarType" SG_ 2015 ISO_OBD_Funktionaler_Req_Data 0;
BA_ "GenSigSwitchedByIgnition" SG_ 2017 ISO_Getriebe_01_Req_Data 0;
BA_ "GenSigSendType" SG_ 2017 ISO_Getriebe_01_Req_Data 3;
BA_ "GenSigEnvVarType" SG_ 2017 ISO_Getriebe_01_Req_Data 0;
BA_ "GenSigSwitchedByIgnition" SG_ 2025 ISO_Getriebe_01_Resp_Data 0;
BA_ "GenSigSendType" SG_ 2025 ISO_Getriebe_01_Resp_Data 3;
BA_ "GenSigEnvVarType" SG_ 2025 ISO_Getriebe_01_Resp_Data 0;
BA_ "GenSigSwitchedByIgnition" SG_ 2021 ISO_Hybrid_01_Req_Data 0;
BA_ "GenSigSendType" SG_ 2021 ISO_Hybrid_01_Req_Data 3;
BA_ "GenSigEnvVarType" SG_ 2021 ISO_Hybrid_01_Req_Data 0;
BA_ "GenSigSwitchedByIgnition" SG_ 2029 ISO_Hybrid_01_Resp_Data 0;
BA_ "GenSigSendType" SG_ 2029 ISO_Hybrid_01_Resp_Data 3;
BA_ "GenSigEnvVarType" SG_ 2029 ISO_Hybrid_01_Resp_Data 0;
BA_ "GenSigSwitchedByIgnition" SG_ 2016 ISO_MO_01_Req_Data 0;
BA_ "GenSigSendType" SG_ 2016 ISO_MO_01_Req_Data 3;
BA_ "GenSigEnvVarType" SG_ 2016 ISO_MO_01_Req_Data 0;
BA_ "GenSigSwitchedByIgnition" SG_ 2024 ISO_MO_01_Resp_Data 0;
BA_ "GenSigSendType" SG_ 2024 ISO_MO_01_Resp_Data 3;
BA_ "GenSigEnvVarType" SG_ 2024 ISO_MO_01_Resp_Data 0;
BA_ "GenSigSwitchedByIgnition" SG_ 2018 ISO_MOS_01_Req_Data 0;
BA_ "GenSigSendType" SG_ 2018 ISO_MOS_01_Req_Data 3;
BA_ "GenSigEnvVarType" SG_ 2018 ISO_MOS_01_Req_Data 0;
BA_ "GenSigSwitchedByIgnition" SG_ 2026 ISO_MOS_01_Resp_Data 0;
BA_ "GenSigSendType" SG_ 2026 ISO_MOS_01_Resp_Data 3;
BA_ "GenSigEnvVarType" SG_ 2026 ISO_MOS_01_Resp_Data 0;
BA_ "GenSigSwitchedByIgnition" SG_ 2023 ISO_OBD_reserv3_Req_Data 0;
BA_ "GenSigSendType" SG_ 2023 ISO_OBD_reserv3_Req_Data 3;
BA_ "GenSigEnvVarType" SG_ 2023 ISO_OBD_reserv3_Req_Data 0;
BA_ "GenSigSwitchedByIgnition" SG_ 2031 ISO_OBD_reserv3_Resp_Data 0;
BA_ "GenSigSendType" SG_ 2031 ISO_OBD_reserv3_Resp_Data 3;
BA_ "GenSigEnvVarType" SG_ 2031 ISO_OBD_reserv3_Resp_Data 0;
BA_ "GenSigSwitchedByIgnition" SG_ 2020 ISO_OBD_reserv4_Req_Data 0;
BA_ "GenSigSendType" SG_ 2020 ISO_OBD_reserv4_Req_Data 3;
BA_ "GenSigEnvVarType" SG_ 2020 ISO_OBD_reserv4_Req_Data 0;
BA_ "GenSigSwitchedByIgnition" SG_ 2028 ISO_OBD_reserv4_Resp_Data 0;
BA_ "GenSigSendType" SG_ 2028 ISO_OBD_reserv4_Resp_Data 3;
BA_ "GenSigEnvVarType" SG_ 2028 ISO_OBD_reserv4_Resp_Data 0;
BA_ "GenSigSwitchedByIgnition" SG_ 2019 ISO_OBD_reserv5_Req_Data 0;
BA_ "GenSigSendType" SG_ 2019 ISO_OBD_reserv5_Req_Data 3;
BA_ "GenSigEnvVarType" SG_ 2019 ISO_OBD_reserv5_Req_Data 0;
BA_ "GenSigSwitchedByIgnition" SG_ 2027 ISO_OBD_reserv5_Resp_Data 0;
BA_ "GenSigSendType" SG_ 2027 ISO_OBD_reserv5_Resp_Data 3;
BA_ "GenSigEnvVarType" SG_ 2027 ISO_OBD_reserv5_Resp_Data 0;
BA_ "GenSigSwitchedByIgnition" SG_ 1820 ISO_Soundaktor_Req_Data 0;
BA_ "GenSigFuncType" SG_ 1820 ISO_Soundaktor_Req_Data 9;
BA_ "GenSigSendType" SG_ 1820 ISO_Soundaktor_Req_Data 3;
BA_ "GenSigAutoGenSnd" SG_ 1820 ISO_Soundaktor_Req_Data 1;
BA_ "GenSigAutoGenDsp" SG_ 1820 ISO_Soundaktor_Req_Data 1;
BA_ "GenSigSwitchedByIgnition" SG_ 1926 ISO_Soundaktor_Resp_Data 0;
BA_ "GenSigFuncType" SG_ 1926 ISO_Soundaktor_Resp_Data 9;
BA_ "GenSigSendType" SG_ 1926 ISO_Soundaktor_Resp_Data 3;
BA_ "GenSigAutoGenSnd" SG_ 1926 ISO_Soundaktor_Resp_Data 1;
BA_ "GenSigAutoGenDsp" SG_ 1926 ISO_Soundaktor_Resp_Data 1;
BA_ "GenSigSwitchedByIgnition" SG_ 960 Klemmen_Status_01_CRC 0;
BA_ "GenSigFuncType" SG_ 960 Klemmen_Status_01_CRC 2;
BA_ "GenSigSendType" SG_ 960 Klemmen_Status_01_CRC 0;
BA_ "GenSigEnvVarType" SG_ 960 Klemmen_Status_01_CRC 0;
BA_ "GenSigAutoGenSnd" SG_ 960 Klemmen_Status_01_CRC 1;
BA_ "GenSigAutoGenDsp" SG_ 960 Klemmen_Status_01_CRC 1;
BA_ "GenSigSwitchedByIgnition" SG_ 960 Klemmen_Status_01_BZ 0;
BA_ "GenSigFuncType" SG_ 960 Klemmen_Status_01_BZ 1;
BA_ "GenSigSendType" SG_ 960 Klemmen_Status_01_BZ 0;
BA_ "GenSigEnvVarType" SG_ 960 Klemmen_Status_01_BZ 0;
BA_ "GenSigAutoGenSnd" SG_ 960 Klemmen_Status_01_BZ 1;
BA_ "GenSigAutoGenDsp" SG_ 960 Klemmen_Status_01_BZ 1;
BA_ "GenSigSwitchedByIgnition" SG_ 960 ZAS_Kl_S 0;
BA_ "GenSigSendType" SG_ 960 ZAS_Kl_S 3;
BA_ "GenSigEnvVarType" SG_ 960 ZAS_Kl_S 0;
BA_ "GenSigAutoGenSnd" SG_ 960 ZAS_Kl_S 1;
BA_ "GenSigAutoGenDsp" SG_ 960 ZAS_Kl_S 1;
BA_ "GenSigSwitchedByIgnition" SG_ 960 ZAS_Kl_15 0;
BA_ "GenSigFuncType" SG_ 960 ZAS_Kl_15 6;
BA_ "NWM-WakeupAllowed" SG_ 960 ZAS_Kl_15 1;
BA_ "GenSigSendType" SG_ 960 ZAS_Kl_15 3;
BA_ "GenSigEnvVarType" SG_ 960 ZAS_Kl_15 0;
BA_ "GenSigAutoGenSnd" SG_ 960 ZAS_Kl_15 1;
BA_ "GenSigAutoGenDsp" SG_ 960 ZAS_Kl_15 1;
BA_ "GenSigSwitchedByIgnition" SG_ 960 ZAS_Kl_X 0;
BA_ "GenSigSendType" SG_ 960 ZAS_Kl_X 3;
BA_ "GenSigEnvVarType" SG_ 960 ZAS_Kl_X 0;
BA_ "GenSigAutoGenSnd" SG_ 960 ZAS_Kl_X 1;
BA_ "GenSigAutoGenDsp" SG_ 960 ZAS_Kl_X 1;
BA_ "GenSigSwitchedByIgnition" SG_ 960 ZAS_Kl_50 0;
BA_ "GenSigSendType" SG_ 960 ZAS_Kl_50 3;
BA_ "GenSigEnvVarType" SG_ 960 ZAS_Kl_50 0;
BA_ "GenSigAutoGenSnd" SG_ 960 ZAS_Kl_50 1;
BA_ "GenSigAutoGenDsp" SG_ 960 ZAS_Kl_50 1;
BA_ "GenSigSwitchedByIgnition" SG_ 949 KL_Drehz_Anh 0;
BA_ "GenSigSendType" SG_ 949 KL_Drehz_Anh 0;
BA_ "GenSigEnvVarType" SG_ 949 KL_Drehz_Anh 0;
BA_ "GenSigAutoGenSnd" SG_ 949 KL_Drehz_Anh 1;
BA_ "GenSigAutoGenDsp" SG_ 949 KL_Drehz_Anh 1;
BA_ "GenSigSwitchedByIgnition" SG_ 949 KL_Vorwarn_Komp_ein 0;
BA_ "GenSigSendType" SG_ 949 KL_Vorwarn_Komp_ein 0;
BA_ "GenSigEnvVarType" SG_ 949 KL_Vorwarn_Komp_ein 0;
BA_ "GenSigAutoGenSnd" SG_ 949 KL_Vorwarn_Komp_ein 1;
BA_ "GenSigAutoGenDsp" SG_ 949 KL_Vorwarn_Komp_ein 1;
BA_ "GenSigSwitchedByIgnition" SG_ 949 KL_AC_Schalter 0;
BA_ "GenSigSendType" SG_ 949 KL_AC_Schalter 0;
BA_ "GenSigEnvVarType" SG_ 949 KL_AC_Schalter 0;
BA_ "GenSigAutoGenSnd" SG_ 949 KL_AC_Schalter 1;
BA_ "GenSigAutoGenDsp" SG_ 949 KL_AC_Schalter 1;
BA_ "GenSigSwitchedByIgnition" SG_ 949 KL_Komp_Moment_alt 0;
BA_ "GenSigFuncType" SG_ 949 KL_Komp_Moment_alt 5;
BA_ "GenSigSendType" SG_ 949 KL_Komp_Moment_alt 0;
BA_ "GenSigEnvVarType" SG_ 949 KL_Komp_Moment_alt 0;
BA_ "GenSigAutoGenSnd" SG_ 949 KL_Komp_Moment_alt 1;
BA_ "GenSigAutoGenDsp" SG_ 949 KL_Komp_Moment_alt 1;
BA_ "GenSigSwitchedByIgnition" SG_ 949 KL_Zonen 0;
BA_ "GenSigSendType" SG_ 949 KL_Zonen 0;
BA_ "GenSigEnvVarType" SG_ 949 KL_Zonen 0;
BA_ "GenSigAutoGenSnd" SG_ 949 KL_Zonen 1;
BA_ "GenSigAutoGenDsp" SG_ 949 KL_Zonen 1;
BA_ "GenSigSwitchedByIgnition" SG_ 949 KL_Vorwarn_Zuheizer_ein 0;
BA_ "GenSigSendType" SG_ 949 KL_Vorwarn_Zuheizer_ein 0;
BA_ "GenSigEnvVarType" SG_ 949 KL_Vorwarn_Zuheizer_ein 0;
BA_ "GenSigAutoGenSnd" SG_ 949 KL_Vorwarn_Zuheizer_ein 1;
BA_ "GenSigAutoGenDsp" SG_ 949 KL_Vorwarn_Zuheizer_ein 1;
BA_ "GenSigSwitchedByIgnition" SG_ 949 KL_Zustand 0;
BA_ "GenSigSendType" SG_ 949 KL_Zustand 0;
BA_ "GenSigEnvVarType" SG_ 949 KL_Zustand 0;
BA_ "GenSigAutoGenSnd" SG_ 949 KL_Zustand 1;
BA_ "GenSigAutoGenDsp" SG_ 949 KL_Zustand 1;
BA_ "Fehlerwert" SG_ 949 KL_Comp_rev_rq 255;
BA_ "GenSigSwitchedByIgnition" SG_ 949 KL_Comp_rev_rq 0;
BA_ "GenSigSendType" SG_ 949 KL_Comp_rev_rq 0;
BA_ "GenSigAutoGenSnd" SG_ 949 KL_Comp_rev_rq 1;
BA_ "GenSigAutoGenDsp" SG_ 949 KL_Comp_rev_rq 1;
BA_ "GenSigSwitchedByIgnition" SG_ 949 KL_Charisma_FahrPr 0;
BA_ "GenSigSendType" SG_ 949 KL_Charisma_FahrPr 0;
BA_ "GenSigEnvVarType" SG_ 949 KL_Charisma_FahrPr 0;
BA_ "GenSigAutoGenSnd" SG_ 949 KL_Charisma_FahrPr 1;
BA_ "GenSigAutoGenDsp" SG_ 949 KL_Charisma_FahrPr 1;
BA_ "GenSigSwitchedByIgnition" SG_ 949 KL_Charisma_Status 0;
BA_ "GenSigSendType" SG_ 949 KL_Charisma_Status 0;
BA_ "GenSigEnvVarType" SG_ 949 KL_Charisma_Status 0;
BA_ "GenSigAutoGenSnd" SG_ 949 KL_Charisma_Status 1;
BA_ "GenSigAutoGenDsp" SG_ 949 KL_Charisma_Status 1;
BA_ "GenSigSwitchedByIgnition" SG_ 949 KL_Comp_enable 0;
BA_ "GenSigSendType" SG_ 949 KL_Comp_enable 0;
BA_ "GenSigAutoGenSnd" SG_ 949 KL_Comp_enable 1;
BA_ "GenSigAutoGenDsp" SG_ 949 KL_Comp_enable 1;
BA_ "Fehlerwert" SG_ 949 KL_Last_Kompr 255;
BA_ "GenSigSwitchedByIgnition" SG_ 949 KL_Last_Kompr 0;
BA_ "GenSigSendType" SG_ 949 KL_Last_Kompr 0;
BA_ "GenSigEnvVarType" SG_ 949 KL_Last_Kompr 1;
BA_ "GenSigAutoGenSnd" SG_ 949 KL_Last_Kompr 1;
BA_ "GenSigAutoGenDsp" SG_ 949 KL_Last_Kompr 1;
BA_ "GenSigSwitchedByIgnition" SG_ 949 KL_Spannungs_Anf 0;
BA_ "GenSigSendType" SG_ 949 KL_Spannungs_Anf 0;
BA_ "GenSigEnvVarType" SG_ 949 KL_Spannungs_Anf 0;
BA_ "GenSigAutoGenSnd" SG_ 949 KL_Spannungs_Anf 1;
BA_ "GenSigAutoGenDsp" SG_ 949 KL_Spannungs_Anf 1;
BA_ "GenSigSwitchedByIgnition" SG_ 949 KL_Thermomanagement 0;
BA_ "GenSigSendType" SG_ 949 KL_Thermomanagement 0;
BA_ "GenSigEnvVarType" SG_ 949 KL_Thermomanagement 0;
BA_ "GenSigAutoGenSnd" SG_ 949 KL_Thermomanagement 1;
BA_ "GenSigAutoGenDsp" SG_ 949 KL_Thermomanagement 1;
BA_ "GenSigSwitchedByIgnition" SG_ 949 KL_StartStopp_Info 0;
BA_ "GenSigSendType" SG_ 949 KL_StartStopp_Info 0;
BA_ "GenSigAutoGenSnd" SG_ 949 KL_StartStopp_Info 1;
BA_ "GenSigAutoGenDsp" SG_ 949 KL_StartStopp_Info 1;
BA_ "Fehlerwert" SG_ 949 KL_Anf_KL 255;
BA_ "GenSigSwitchedByIgnition" SG_ 949 KL_Anf_KL 0;
BA_ "GenSigSendType" SG_ 949 KL_Anf_KL 0;
BA_ "GenSigEnvVarType" SG_ 949 KL_Anf_KL 1;
BA_ "GenSigAutoGenSnd" SG_ 949 KL_Anf_KL 1;
BA_ "GenSigAutoGenDsp" SG_ 949 KL_Anf_KL 1;
BA_ "GenSigSwitchedByIgnition" SG_ 949 KL_el_Zuheizer_Stufe 0;
BA_ "GenSigSendType" SG_ 949 KL_el_Zuheizer_Stufe 0;
BA_ "GenSigEnvVarType" SG_ 949 KL_el_Zuheizer_Stufe 0;
BA_ "GenSigAutoGenSnd" SG_ 949 KL_el_Zuheizer_Stufe 1;
BA_ "GenSigAutoGenDsp" SG_ 949 KL_el_Zuheizer_Stufe 1;
BA_ "GenSigSendType" SG_ 1625 EKL_KD_Fehler 0;
BA_ "GenSigEnvVarType" SG_ 1625 EKL_KD_Fehler 0;
BA_ "GenSigAutoGenSnd" SG_ 1625 EKL_KD_Fehler 1;
BA_ "GenSigAutoGenDsp" SG_ 1625 EKL_KD_Fehler 1;
BA_ "GenSigSendType" SG_ 1625 EKL_Comp_SCI_com_stat 0;
BA_ "GenSigAutoGenSnd" SG_ 1625 EKL_Comp_SCI_com_stat 1;
BA_ "GenSigAutoGenDsp" SG_ 1625 EKL_Comp_SCI_com_stat 1;
BA_ "GenSigSendType" SG_ 1625 EKL_Comp_output_stat 0;
BA_ "GenSigAutoGenSnd" SG_ 1625 EKL_Comp_output_stat 1;
BA_ "GenSigAutoGenDsp" SG_ 1625 EKL_Comp_output_stat 1;
BA_ "GenSigSendType" SG_ 1625 EKL_Comp_main_stat 0;
BA_ "GenSigAutoGenSnd" SG_ 1625 EKL_Comp_main_stat 1;
BA_ "GenSigAutoGenDsp" SG_ 1625 EKL_Comp_main_stat 1;
BA_ "GenSigSendType" SG_ 1625 EKL_Comp_ovld_stat 0;
BA_ "GenSigAutoGenSnd" SG_ 1625 EKL_Comp_ovld_stat 1;
BA_ "GenSigAutoGenDsp" SG_ 1625 EKL_Comp_ovld_stat 1;
BA_ "GenSigSendType" SG_ 1625 EKL_Comp_Inv_stat 0;
BA_ "GenSigAutoGenSnd" SG_ 1625 EKL_Comp_Inv_stat 1;
BA_ "GenSigAutoGenDsp" SG_ 1625 EKL_Comp_Inv_stat 1;
BA_ "GenSigSendType" SG_ 1625 EKL_Comp_photo_temp_stat 0;
BA_ "GenSigAutoGenSnd" SG_ 1625 EKL_Comp_photo_temp_stat 1;
BA_ "GenSigAutoGenDsp" SG_ 1625 EKL_Comp_photo_temp_stat 1;
BA_ "Fehlerwert" SG_ 1625 EKL_Comp_photo_temp 255;
BA_ "GenSigStartValue" SG_ 1625 EKL_Comp_photo_temp 255;
BA_ "GenSigSendType" SG_ 1625 EKL_Comp_photo_temp 0;
BA_ "GenSigAutoGenSnd" SG_ 1625 EKL_Comp_photo_temp 1;
BA_ "GenSigAutoGenDsp" SG_ 1625 EKL_Comp_photo_temp 1;
BA_ "Fehlerwert" SG_ 1625 EKL_Comp_current 255;
BA_ "GenSigStartValue" SG_ 1625 EKL_Comp_current 255;
BA_ "GenSigSendType" SG_ 1625 EKL_Comp_current 0;
BA_ "GenSigAutoGenSnd" SG_ 1625 EKL_Comp_current 1;
BA_ "GenSigAutoGenDsp" SG_ 1625 EKL_Comp_current 1;
BA_ "Fehlerwert" SG_ 1625 EKL_Comp_rev_stat 255;
BA_ "GenSigSendType" SG_ 1625 EKL_Comp_rev_stat 0;
BA_ "GenSigAutoGenSnd" SG_ 1625 EKL_Comp_rev_stat 1;
BA_ "GenSigAutoGenDsp" SG_ 1625 EKL_Comp_rev_stat 1;
BA_ "GenSigSendType" SG_ 2549088277 Airbag_01_KompSchutz 0;
BA_ "GenSigEnvVarType" SG_ 2549088277 Airbag_01_KompSchutz 0;
BA_ "GenSigSendType" SG_ 2549088277 Airbag_01_Nachlauftyp 0;
BA_ "GenSigEnvVarType" SG_ 2549088277 Airbag_01_Nachlauftyp 0;
BA_ "GenSigSendType" SG_ 2549088277 AB_KD_Fehler 0;
BA_ "GenSigEnvVarType" SG_ 2549088277 AB_KD_Fehler 0;
BA_ "GenSigAutoGenSnd" SG_ 2549088277 AB_KD_Fehler 1;
BA_ "GenSigAutoGenDsp" SG_ 2549088277 AB_KD_Fehler 1;
BA_ "GenSigSwitchedByIgnition" SG_ 2549088380 EMotor_KompSchutz 0;
BA_ "GenSigSendType" SG_ 2549088380 EMotor_KompSchutz 0;
BA_ "GenSigEnvVarType" SG_ 2549088380 EMotor_KompSchutz 0;
BA_ "GenSigSwitchedByIgnition" SG_ 2549088380 EMotor_Nachlauftyp 0;
BA_ "GenSigStartValue" SG_ 2549088380 EMotor_Nachlauftyp 1;
BA_ "GenSigSendType" SG_ 2549088380 EMotor_Nachlauftyp 0;
BA_ "GenSigEnvVarType" SG_ 2549088380 EMotor_Nachlauftyp 0;
BA_ "GenSigSwitchedByIgnition" SG_ 2549088380 EM_HYB_KD_Fehler 0;
BA_ "GenSigSendType" SG_ 2549088380 EM_HYB_KD_Fehler 0;
BA_ "GenSigEnvVarType" SG_ 2549088380 EM_HYB_KD_Fehler 0;
BA_ "GenSigAutoGenSnd" SG_ 2549088380 EM_HYB_KD_Fehler 1;
BA_ "GenSigAutoGenDsp" SG_ 2549088380 EM_HYB_KD_Fehler 1;
BA_ "GenSigSwitchedByIgnition" SG_ 2549088375 Getriebe_KompSchutz 0;
BA_ "GenSigSendType" SG_ 2549088375 Getriebe_KompSchutz 0;
BA_ "GenSigEnvVarType" SG_ 2549088375 Getriebe_KompSchutz 0;
BA_ "GenSigSwitchedByIgnition" SG_ 2549088375 Getriebe_Nachlauftyp 0;
BA_ "GenSigStartValue" SG_ 2549088375 Getriebe_Nachlauftyp 1;
BA_ "GenSigSendType" SG_ 2549088375 Getriebe_Nachlauftyp 0;
BA_ "GenSigEnvVarType" SG_ 2549088375 Getriebe_Nachlauftyp 0;
BA_ "GenSigSwitchedByIgnition" SG_ 2549088375 GE_KD_Fehler 0;
BA_ "GenSigSendType" SG_ 2549088375 GE_KD_Fehler 0;
BA_ "GenSigEnvVarType" SG_ 2549088375 GE_KD_Fehler 0;
BA_ "GenSigAutoGenSnd" SG_ 2549088375 GE_KD_Fehler 1;
BA_ "GenSigAutoGenDsp" SG_ 2549088375 GE_KD_Fehler 1;
BA_ "GenSigSwitchedByIgnition" SG_ 2549088379 Hybrid_KompSchutz 0;
BA_ "GenSigSendType" SG_ 2549088379 Hybrid_KompSchutz 0;
BA_ "GenSigEnvVarType" SG_ 2549088379 Hybrid_KompSchutz 0;
BA_ "GenSigSwitchedByIgnition" SG_ 2549088379 Hybrid_Nachlauftyp 0;
BA_ "GenSigStartValue" SG_ 2549088379 Hybrid_Nachlauftyp 1;
BA_ "GenSigSendType" SG_ 2549088379 Hybrid_Nachlauftyp 0;
BA_ "GenSigEnvVarType" SG_ 2549088379 Hybrid_Nachlauftyp 0;
BA_ "GenSigSwitchedByIgnition" SG_ 2549088379 BMS_HYB_KD_Fehler 0;
BA_ "GenSigSendType" SG_ 2549088379 BMS_HYB_KD_Fehler 0;
BA_ "GenSigEnvVarType" SG_ 2549088379 BMS_HYB_KD_Fehler 0;
BA_ "GenSigAutoGenSnd" SG_ 2549088379 BMS_HYB_KD_Fehler 1;
BA_ "GenSigAutoGenDsp" SG_ 2549088379 BMS_HYB_KD_Fehler 1;
BA_ "GenSigSwitchedByIgnition" SG_ 2549088374 Motor_KompSchutz 0;
BA_ "GenSigSendType" SG_ 2549088374 Motor_KompSchutz 0;
BA_ "GenSigEnvVarType" SG_ 2549088374 Motor_KompSchutz 0;
BA_ "GenSigSwitchedByIgnition" SG_ 2549088374 Motor_Nachlauftyp 0;
BA_ "GenSigStartValue" SG_ 2549088374 Motor_Nachlauftyp 2;
BA_ "GenSigSendType" SG_ 2549088374 Motor_Nachlauftyp 0;
BA_ "GenSigEnvVarType" SG_ 2549088374 Motor_Nachlauftyp 0;
BA_ "GenSigSwitchedByIgnition" SG_ 2549088374 MO_KD_Fehler 0;
BA_ "GenSigSendType" SG_ 2549088374 MO_KD_Fehler 0;
BA_ "GenSigEnvVarType" SG_ 2549088374 MO_KD_Fehler 0;
BA_ "GenSigAutoGenSnd" SG_ 2549088374 MO_KD_Fehler 1;
BA_ "GenSigAutoGenDsp" SG_ 2549088374 MO_KD_Fehler 1;
BA_ "GenSigSendType" SG_ 2549088284 SAK_KompSchutz 0;
BA_ "GenSigEnvVarType" SG_ 2549088284 SAK_KompSchutz 0;
BA_ "GenSigSendType" SG_ 2549088284 SAK_Nachlauftyp 0;
BA_ "GenSigEnvVarType" SG_ 2549088284 SAK_Nachlauftyp 0;
BA_ "GenSigSendType" SG_ 2549088284 SAK_KD_Fehler 0;
BA_ "GenSigEnvVarType" SG_ 2549088284 SAK_KD_Fehler 0;
BA_ "GenSigAutoGenSnd" SG_ 2549088284 SAK_KD_Fehler 1;
BA_ "GenSigAutoGenDsp" SG_ 2549088284 SAK_KD_Fehler 1;
BA_ "GenSigSwitchedByIgnition" SG_ 779 KBI_ABS_Lampe 0;
BA_ "GenSigSendType" SG_ 779 KBI_ABS_Lampe 0;
BA_ "GenSigEnvVarType" SG_ 779 KBI_ABS_Lampe 0;
BA_ "GenSigAutoGenSnd" SG_ 779 KBI_ABS_Lampe 1;
BA_ "GenSigAutoGenDsp" SG_ 779 KBI_ABS_Lampe 1;
BA_ "GenSigSwitchedByIgnition" SG_ 779 KBI_ESP_Lampe 0;
BA_ "GenSigSendType" SG_ 779 KBI_ESP_Lampe 0;
BA_ "GenSigEnvVarType" SG_ 779 KBI_ESP_Lampe 0;
BA_ "GenSigAutoGenSnd" SG_ 779 KBI_ESP_Lampe 1;
BA_ "GenSigAutoGenDsp" SG_ 779 KBI_ESP_Lampe 1;
BA_ "GenSigSwitchedByIgnition" SG_ 779 KBI_BKL_Lampe 0;
BA_ "GenSigSendType" SG_ 779 KBI_BKL_Lampe 0;
BA_ "GenSigEnvVarType" SG_ 779 KBI_BKL_Lampe 0;
BA_ "GenSigAutoGenSnd" SG_ 779 KBI_BKL_Lampe 1;
BA_ "GenSigAutoGenDsp" SG_ 779 KBI_BKL_Lampe 1;
BA_ "GenSigSwitchedByIgnition" SG_ 779 KBI_Airbag_Lampe 0;
BA_ "GenSigSendType" SG_ 779 KBI_Airbag_Lampe 0;
BA_ "GenSigEnvVarType" SG_ 779 KBI_Airbag_Lampe 0;
BA_ "GenSigAutoGenSnd" SG_ 779 KBI_Airbag_Lampe 1;
BA_ "GenSigAutoGenDsp" SG_ 779 KBI_Airbag_Lampe 1;
BA_ "GenSigSwitchedByIgnition" SG_ 779 KBI_SILA_gueltig 0;
BA_ "GenSigSendType" SG_ 779 KBI_SILA_gueltig 0;
BA_ "GenSigEnvVarType" SG_ 779 KBI_SILA_gueltig 0;
BA_ "GenSigAutoGenSnd" SG_ 779 KBI_SILA_gueltig 1;
BA_ "GenSigAutoGenDsp" SG_ 779 KBI_SILA_gueltig 1;
BA_ "GenSigSwitchedByIgnition" SG_ 779 KBI_Lenkung_Lampe 0;
BA_ "GenSigSendType" SG_ 779 KBI_Lenkung_Lampe 0;
BA_ "GenSigEnvVarType" SG_ 779 KBI_Lenkung_Lampe 0;
BA_ "GenSigAutoGenSnd" SG_ 779 KBI_Lenkung_Lampe 1;
BA_ "GenSigAutoGenDsp" SG_ 779 KBI_Lenkung_Lampe 1;
BA_ "GenSigSwitchedByIgnition" SG_ 779 KBI_Vorglueh_System_Lampe 0;
BA_ "GenSigSendType" SG_ 779 KBI_Vorglueh_System_Lampe 0;
BA_ "GenSigEnvVarType" SG_ 779 KBI_Vorglueh_System_Lampe 0;
BA_ "GenSigAutoGenSnd" SG_ 779 KBI_Vorglueh_System_Lampe 1;
BA_ "GenSigAutoGenDsp" SG_ 779 KBI_Vorglueh_System_Lampe 1;
BA_ "GenSigSwitchedByIgnition" SG_ 779 KBI_NV_in_Anzeige 0;
BA_ "GenSigSendType" SG_ 779 KBI_NV_in_Anzeige 0;
BA_ "GenSigAutoGenSnd" SG_ 779 KBI_NV_in_Anzeige 1;
BA_ "GenSigAutoGenDsp" SG_ 779 KBI_NV_in_Anzeige 1;
BA_ "GenSigSwitchedByIgnition" SG_ 779 Kombi_01_BZ 0;
BA_ "GenSigFuncType" SG_ 779 Kombi_01_BZ 1;
BA_ "GenSigSendType" SG_ 779 Kombi_01_BZ 0;
BA_ "GenSigEnvVarType" SG_ 779 Kombi_01_BZ 0;
BA_ "GenSigAutoGenSnd" SG_ 779 Kombi_01_BZ 1;
BA_ "GenSigAutoGenDsp" SG_ 779 Kombi_01_BZ 1;
BA_ "GenSigSwitchedByIgnition" SG_ 779 KBI_Anzeigestatus_ACC 0;
BA_ "GenSigSendType" SG_ 779 KBI_Anzeigestatus_ACC 0;
BA_ "GenSigAutoGenSnd" SG_ 779 KBI_Anzeigestatus_ACC 1;
BA_ "GenSigAutoGenDsp" SG_ 779 KBI_Anzeigestatus_ACC 1;
BA_ "Fehlerwert" SG_ 779 KBI_Anzeigestatus_GRA 3;
BA_ "GenSigSwitchedByIgnition" SG_ 779 KBI_Anzeigestatus_GRA 0;
BA_ "GenSigSendType" SG_ 779 KBI_Anzeigestatus_GRA 0;
BA_ "GenSigAutoGenSnd" SG_ 779 KBI_Anzeigestatus_GRA 1;
BA_ "GenSigAutoGenDsp" SG_ 779 KBI_Anzeigestatus_GRA 1;
BA_ "GenSigSwitchedByIgnition" SG_ 779 KBI_Oeldruck_Schalter 0;
BA_ "GenSigSendType" SG_ 779 KBI_Oeldruck_Schalter 0;
BA_ "GenSigEnvVarType" SG_ 779 KBI_Oeldruck_Schalter 0;
BA_ "GenSigAutoGenSnd" SG_ 779 KBI_Oeldruck_Schalter 1;
BA_ "GenSigAutoGenDsp" SG_ 779 KBI_Oeldruck_Schalter 1;
BA_ "GenSigSwitchedByIgnition" SG_ 779 KBI_Tankwarnung 0;
BA_ "GenSigSendType" SG_ 779 KBI_Tankwarnung 0;
BA_ "GenSigEnvVarType" SG_ 779 KBI_Tankwarnung 0;
BA_ "GenSigAutoGenSnd" SG_ 779 KBI_Tankwarnung 1;
BA_ "GenSigAutoGenDsp" SG_ 779 KBI_Tankwarnung 1;
BA_ "GenSigSwitchedByIgnition" SG_ 779 KBI_MFA_v_Einheit_01 0;
BA_ "GenSigSendType" SG_ 779 KBI_MFA_v_Einheit_01 0;
BA_ "GenSigEnvVarType" SG_ 779 KBI_MFA_v_Einheit_01 0;
BA_ "GenSigAutoGenSnd" SG_ 779 KBI_MFA_v_Einheit_01 1;
BA_ "GenSigAutoGenDsp" SG_ 779 KBI_MFA_v_Einheit_01 1;
BA_ "GenSigSwitchedByIgnition" SG_ 779 KBI_im_Stellgliedtest 0;
BA_ "GenSigSendType" SG_ 779 KBI_im_Stellgliedtest 0;
BA_ "GenSigEnvVarType" SG_ 779 KBI_im_Stellgliedtest 0;
BA_ "GenSigAutoGenSnd" SG_ 779 KBI_im_Stellgliedtest 1;
BA_ "GenSigAutoGenDsp" SG_ 779 KBI_im_Stellgliedtest 1;
BA_ "GenSigSwitchedByIgnition" SG_ 779 KBI_Anzeigefehler_LDW 0;
BA_ "GenSigSendType" SG_ 779 KBI_Anzeigefehler_LDW 0;
BA_ "GenSigEnvVarType" SG_ 779 KBI_Anzeigefehler_LDW 0;
BA_ "GenSigAutoGenSnd" SG_ 779 KBI_Anzeigefehler_LDW 1;
BA_ "GenSigAutoGenDsp" SG_ 779 KBI_Anzeigefehler_LDW 1;
BA_ "GenSigSwitchedByIgnition" SG_ 779 KBI_Variante_USA 0;
BA_ "GenSigSendType" SG_ 779 KBI_Variante_USA 0;
BA_ "GenSigEnvVarType" SG_ 779 KBI_Variante_USA 0;
BA_ "GenSigAutoGenSnd" SG_ 779 KBI_Variante_USA 1;
BA_ "GenSigAutoGenDsp" SG_ 779 KBI_Variante_USA 1;
BA_ "GenSigSwitchedByIgnition" SG_ 779 KBI_Oeldruckwarnung 0;
BA_ "GenSigSendType" SG_ 779 KBI_Oeldruckwarnung 0;
BA_ "GenSigEnvVarType" SG_ 779 KBI_Oeldruckwarnung 0;
BA_ "GenSigAutoGenSnd" SG_ 779 KBI_Oeldruckwarnung 1;
BA_ "GenSigAutoGenDsp" SG_ 779 KBI_Oeldruckwarnung 1;
BA_ "GenSigSwitchedByIgnition" SG_ 779 KBI_Handbremse 0;
BA_ "GenSigSendType" SG_ 779 KBI_Handbremse 0;
BA_ "GenSigAutoGenSnd" SG_ 779 KBI_Handbremse 1;
BA_ "GenSigAutoGenDsp" SG_ 779 KBI_Handbremse 1;
BA_ "GenSigSwitchedByIgnition" SG_ 779 KBI_V_Digital 0;
BA_ "GenSigSendType" SG_ 779 KBI_V_Digital 0;
BA_ "GenSigAutoGenSnd" SG_ 779 KBI_V_Digital 1;
BA_ "GenSigAutoGenDsp" SG_ 779 KBI_V_Digital 1;
BA_ "GenSigSwitchedByIgnition" SG_ 779 KBI_PLA_in_Anzeige 0;
BA_ "GenSigSendType" SG_ 779 KBI_PLA_in_Anzeige 0;
BA_ "GenSigSwitchedByIgnition" SG_ 779 KBI_Anzeigefehler_NV 0;
BA_ "GenSigSendType" SG_ 779 KBI_Anzeigefehler_NV 0;
BA_ "GenSigAutoGenSnd" SG_ 779 KBI_Anzeigefehler_NV 1;
BA_ "GenSigAutoGenDsp" SG_ 779 KBI_Anzeigefehler_NV 1;
BA_ "Fehlerwert" SG_ 779 KBI_Anzeigestatus_LIM 3;
BA_ "GenSigSwitchedByIgnition" SG_ 779 KBI_Anzeigestatus_LIM 0;
BA_ "GenSigSendType" SG_ 779 KBI_Anzeigestatus_LIM 0;
BA_ "GenSigAutoGenSnd" SG_ 779 KBI_Anzeigestatus_LIM 1;
BA_ "GenSigAutoGenDsp" SG_ 779 KBI_Anzeigestatus_LIM 1;
BA_ "GenSigSwitchedByIgnition" SG_ 779 KBI_angez_Geschw 0;
BA_ "GenSigSendType" SG_ 779 KBI_angez_Geschw 0;
BA_ "GenSigEnvVarType" SG_ 779 KBI_angez_Geschw 1;
BA_ "GenSigAutoGenSnd" SG_ 779 KBI_angez_Geschw 1;
BA_ "GenSigAutoGenDsp" SG_ 779 KBI_angez_Geschw 1;
BA_ "GenSigSwitchedByIgnition" SG_ 779 KBI_Einheit_Tacho 0;
BA_ "GenSigSendType" SG_ 779 KBI_Einheit_Tacho 0;
BA_ "GenSigEnvVarType" SG_ 779 KBI_Einheit_Tacho 0;
BA_ "GenSigAutoGenSnd" SG_ 779 KBI_Einheit_Tacho 1;
BA_ "GenSigAutoGenDsp" SG_ 779 KBI_Einheit_Tacho 1;
BA_ "GenSigSwitchedByIgnition" SG_ 779 KBI_Konsistenz_ACC 0;
BA_ "GenSigSendType" SG_ 779 KBI_Konsistenz_ACC 0;
BA_ "GenSigEnvVarType" SG_ 779 KBI_Konsistenz_ACC 0;
BA_ "GenSigAutoGenSnd" SG_ 779 KBI_Konsistenz_ACC 1;
BA_ "GenSigAutoGenDsp" SG_ 779 KBI_Konsistenz_ACC 1;
BA_ "GenSigSwitchedByIgnition" SG_ 779 KBI_Fehler_Anzeige_ACC 0;
BA_ "GenSigSendType" SG_ 779 KBI_Fehler_Anzeige_ACC 0;
BA_ "GenSigEnvVarType" SG_ 779 KBI_Fehler_Anzeige_ACC 0;
BA_ "GenSigAutoGenSnd" SG_ 779 KBI_Fehler_Anzeige_ACC 1;
BA_ "GenSigAutoGenDsp" SG_ 779 KBI_Fehler_Anzeige_ACC 1;
BA_ "GenSigSwitchedByIgnition" SG_ 779 KBI_Anzeigefehler_SWA 0;
BA_ "GenSigSendType" SG_ 779 KBI_Anzeigefehler_SWA 0;
BA_ "GenSigEnvVarType" SG_ 779 KBI_Anzeigefehler_SWA 0;
BA_ "GenSigAutoGenSnd" SG_ 779 KBI_Anzeigefehler_SWA 1;
BA_ "GenSigAutoGenDsp" SG_ 779 KBI_Anzeigefehler_SWA 1;
BA_ "Fehlerwert" SG_ 1719 KBI_Kilometerstand 1048575;
BA_ "GenSigSwitchedByIgnition" SG_ 1719 KBI_Kilometerstand 0;
BA_ "GenSigStartValue" SG_ 1719 KBI_Kilometerstand 1048574;
BA_ "GenSigSendType" SG_ 1719 KBI_Kilometerstand 0;
BA_ "GenSigEnvVarType" SG_ 1719 KBI_Kilometerstand 0;
BA_ "GenSigAutoGenSnd" SG_ 1719 KBI_Kilometerstand 1;
BA_ "GenSigAutoGenDsp" SG_ 1719 KBI_Kilometerstand 1;
BA_ "Fehlerwert" SG_ 1719 KBI_Standzeit_02 131071;
BA_ "GenSigSwitchedByIgnition" SG_ 1719 KBI_Standzeit_02 0;
BA_ "GenSigStartValue" SG_ 1719 KBI_Standzeit_02 131070;
BA_ "GenSigSendType" SG_ 1719 KBI_Standzeit_02 0;
BA_ "GenSigEnvVarType" SG_ 1719 KBI_Standzeit_02 0;
BA_ "GenSigAutoGenSnd" SG_ 1719 KBI_Standzeit_02 1;
BA_ "GenSigAutoGenDsp" SG_ 1719 KBI_Standzeit_02 1;
BA_ "Fehlerwert" SG_ 1719 KBI_Inhalt_Tank 127;
BA_ "GenSigSwitchedByIgnition" SG_ 1719 KBI_Inhalt_Tank 0;
BA_ "GenSigStartValue" SG_ 1719 KBI_Inhalt_Tank 126;
BA_ "GenSigSendType" SG_ 1719 KBI_Inhalt_Tank 0;
BA_ "GenSigEnvVarType" SG_ 1719 KBI_Inhalt_Tank 0;
BA_ "GenSigAutoGenSnd" SG_ 1719 KBI_Inhalt_Tank 1;
BA_ "GenSigAutoGenDsp" SG_ 1719 KBI_Inhalt_Tank 1;
BA_ "GenSigSwitchedByIgnition" SG_ 1719 KBI_FStatus_Tank 0;
BA_ "GenSigSendType" SG_ 1719 KBI_FStatus_Tank 0;
BA_ "GenSigEnvVarType" SG_ 1719 KBI_FStatus_Tank 0;
BA_ "GenSigAutoGenSnd" SG_ 1719 KBI_FStatus_Tank 1;
BA_ "GenSigAutoGenDsp" SG_ 1719 KBI_FStatus_Tank 1;
BA_ "GenSigSwitchedByIgnition" SG_ 1719 KBI_QBit_Aussen_Temp_gef 0;
BA_ "GenSigStartValue" SG_ 1719 KBI_QBit_Aussen_Temp_gef 1;
BA_ "GenSigSendType" SG_ 1719 KBI_QBit_Aussen_Temp_gef 0;
BA_ "GenSigEnvVarType" SG_ 1719 KBI_QBit_Aussen_Temp_gef 0;
BA_ "GenSigAutoGenSnd" SG_ 1719 KBI_QBit_Aussen_Temp_gef 1;
BA_ "GenSigAutoGenDsp" SG_ 1719 KBI_QBit_Aussen_Temp_gef 1;
BA_ "Fehlerwert" SG_ 1719 KBI_Aussen_Temp_gef 255;
BA_ "GenSigSwitchedByIgnition" SG_ 1719 KBI_Aussen_Temp_gef 0;
BA_ "GenSigStartValue" SG_ 1719 KBI_Aussen_Temp_gef 254;
BA_ "GenSigSendType" SG_ 1719 KBI_Aussen_Temp_gef 0;
BA_ "GenSigEnvVarType" SG_ 1719 KBI_Aussen_Temp_gef 1;
BA_ "GenSigAutoGenSnd" SG_ 1719 KBI_Aussen_Temp_gef 1;
BA_ "GenSigAutoGenDsp" SG_ 1719 KBI_Aussen_Temp_gef 1;
BA_ "GenSigSwitchedByIgnition" SG_ 2549874965 KS_Airbag_01_Req_Data 0;
BA_ "GenSigFuncType" SG_ 2549874965 KS_Airbag_01_Req_Data 9;
BA_ "GenSigEnvVarType" SG_ 2549874965 KS_Airbag_01_Req_Data 0;
BA_ "GenSigSwitchedByIgnition" SG_ 2550006037 KS_Airbag_01_Resp_Data 0;
BA_ "GenSigFuncType" SG_ 2550006037 KS_Airbag_01_Resp_Data 9;
BA_ "GenSigEnvVarType" SG_ 2550006037 KS_Airbag_01_Resp_Data 0;
BA_ "GenSigSwitchedByIgnition" SG_ 982 Licht_hinten_01_BZ 0;
BA_ "GenSigFuncType" SG_ 982 Licht_hinten_01_BZ 1;
BA_ "GenSigSendType" SG_ 982 Licht_hinten_01_BZ 0;
BA_ "GenSigEnvVarType" SG_ 982 Licht_hinten_01_BZ 0;
BA_ "GenSigAutoGenSnd" SG_ 982 Licht_hinten_01_BZ 1;
BA_ "GenSigAutoGenDsp" SG_ 982 Licht_hinten_01_BZ 1;
BA_ "GenSigSwitchedByIgnition" SG_ 982 BCM2_Bremsl_durch_ECD 0;
BA_ "GenSigSendType" SG_ 982 BCM2_Bremsl_durch_ECD 0;
BA_ "GenSigEnvVarType" SG_ 982 BCM2_Bremsl_durch_ECD 0;
BA_ "GenSigAutoGenSnd" SG_ 982 BCM2_Bremsl_durch_ECD 1;
BA_ "GenSigAutoGenDsp" SG_ 982 BCM2_Bremsl_durch_ECD 1;
BA_ "GenSigSwitchedByIgnition" SG_ 982 LH_Aussenlicht_def 0;
BA_ "GenSigSendType" SG_ 982 LH_Aussenlicht_def 0;
BA_ "GenSigEnvVarType" SG_ 982 LH_Aussenlicht_def 0;
BA_ "GenSigAutoGenSnd" SG_ 982 LH_Aussenlicht_def 1;
BA_ "GenSigAutoGenDsp" SG_ 982 LH_Aussenlicht_def 1;
BA_ "GenSigSwitchedByIgnition" SG_ 982 LH_Standlicht_H_aktiv 0;
BA_ "GenSigSendType" SG_ 982 LH_Standlicht_H_aktiv 0;
BA_ "GenSigEnvVarType" SG_ 982 LH_Standlicht_H_aktiv 0;
BA_ "GenSigAutoGenSnd" SG_ 982 LH_Standlicht_H_aktiv 1;
BA_ "GenSigAutoGenDsp" SG_ 982 LH_Standlicht_H_aktiv 1;
BA_ "GenSigSwitchedByIgnition" SG_ 982 LH_Parklicht_HL_aktiv 0;
BA_ "GenSigSendType" SG_ 982 LH_Parklicht_HL_aktiv 0;
BA_ "GenSigEnvVarType" SG_ 982 LH_Parklicht_HL_aktiv 0;
BA_ "GenSigAutoGenSnd" SG_ 982 LH_Parklicht_HL_aktiv 1;
BA_ "GenSigAutoGenDsp" SG_ 982 LH_Parklicht_HL_aktiv 1;
BA_ "GenSigSwitchedByIgnition" SG_ 982 LH_Parklicht_HR_aktiv 0;
BA_ "GenSigSendType" SG_ 982 LH_Parklicht_HR_aktiv 0;
BA_ "GenSigEnvVarType" SG_ 982 LH_Parklicht_HR_aktiv 0;
BA_ "GenSigAutoGenSnd" SG_ 982 LH_Parklicht_HR_aktiv 1;
BA_ "GenSigAutoGenDsp" SG_ 982 LH_Parklicht_HR_aktiv 1;
BA_ "GenSigSwitchedByIgnition" SG_ 982 LH_Bremslicht_H_aktiv 0;
BA_ "GenSigSendType" SG_ 982 LH_Bremslicht_H_aktiv 0;
BA_ "GenSigEnvVarType" SG_ 982 LH_Bremslicht_H_aktiv 0;
BA_ "GenSigAutoGenSnd" SG_ 982 LH_Bremslicht_H_aktiv 1;
BA_ "GenSigAutoGenDsp" SG_ 982 LH_Bremslicht_H_aktiv 1;
BA_ "GenSigSwitchedByIgnition" SG_ 982 LH_Nebelschluss_aktiv 0;
BA_ "GenSigSendType" SG_ 982 LH_Nebelschluss_aktiv 0;
BA_ "GenSigEnvVarType" SG_ 982 LH_Nebelschluss_aktiv 0;
BA_ "GenSigAutoGenSnd" SG_ 982 LH_Nebelschluss_aktiv 1;
BA_ "GenSigAutoGenDsp" SG_ 982 LH_Nebelschluss_aktiv 1;
BA_ "GenSigSwitchedByIgnition" SG_ 982 LH_Rueckfahrlicht_aktiv 0;
BA_ "GenSigSendType" SG_ 982 LH_Rueckfahrlicht_aktiv 0;
BA_ "GenSigEnvVarType" SG_ 982 LH_Rueckfahrlicht_aktiv 0;
BA_ "GenSigAutoGenSnd" SG_ 982 LH_Rueckfahrlicht_aktiv 1;
BA_ "GenSigAutoGenDsp" SG_ 982 LH_Rueckfahrlicht_aktiv 1;
BA_ "GenSigSwitchedByIgnition" SG_ 982 LH_Blinker_HL_akt 0;
BA_ "GenSigSendType" SG_ 982 LH_Blinker_HL_akt 0;
BA_ "GenSigEnvVarType" SG_ 982 LH_Blinker_HL_akt 0;
BA_ "GenSigAutoGenSnd" SG_ 982 LH_Blinker_HL_akt 1;
BA_ "GenSigAutoGenDsp" SG_ 982 LH_Blinker_HL_akt 1;
BA_ "GenSigSwitchedByIgnition" SG_ 982 LH_Blinker_HR_akt 0;
BA_ "GenSigSendType" SG_ 982 LH_Blinker_HR_akt 0;
BA_ "GenSigEnvVarType" SG_ 982 LH_Blinker_HR_akt 0;
BA_ "GenSigAutoGenSnd" SG_ 982 LH_Blinker_HR_akt 1;
BA_ "GenSigAutoGenDsp" SG_ 982 LH_Blinker_HR_akt 1;
BA_ "GenSigSwitchedByIgnition" SG_ 982 LH_Blinker_li_def 0;
BA_ "GenSigSendType" SG_ 982 LH_Blinker_li_def 0;
BA_ "GenSigEnvVarType" SG_ 982 LH_Blinker_li_def 0;
BA_ "GenSigAutoGenSnd" SG_ 982 LH_Blinker_li_def 1;
BA_ "GenSigAutoGenDsp" SG_ 982 LH_Blinker_li_def 1;
BA_ "GenSigSwitchedByIgnition" SG_ 982 LH_Bremsl_li_def 0;
BA_ "GenSigSendType" SG_ 982 LH_Bremsl_li_def 0;
BA_ "GenSigEnvVarType" SG_ 982 LH_Bremsl_li_def 0;
BA_ "GenSigAutoGenSnd" SG_ 982 LH_Bremsl_li_def 1;
BA_ "GenSigAutoGenDsp" SG_ 982 LH_Bremsl_li_def 1;
BA_ "GenSigSwitchedByIgnition" SG_ 982 LH_Schlusslicht_li_def 0;
BA_ "GenSigSendType" SG_ 982 LH_Schlusslicht_li_def 0;
BA_ "GenSigEnvVarType" SG_ 982 LH_Schlusslicht_li_def 0;
BA_ "GenSigAutoGenSnd" SG_ 982 LH_Schlusslicht_li_def 1;
BA_ "GenSigAutoGenDsp" SG_ 982 LH_Schlusslicht_li_def 1;
BA_ "GenSigSwitchedByIgnition" SG_ 982 LH_Rueckf_li_def 0;
BA_ "GenSigSendType" SG_ 982 LH_Rueckf_li_def 0;
BA_ "GenSigEnvVarType" SG_ 982 LH_Rueckf_li_def 0;
BA_ "GenSigAutoGenSnd" SG_ 982 LH_Rueckf_li_def 1;
BA_ "GenSigAutoGenDsp" SG_ 982 LH_Rueckf_li_def 1;
BA_ "GenSigSwitchedByIgnition" SG_ 982 LH_Nebel_li_def 0;
BA_ "GenSigSendType" SG_ 982 LH_Nebel_li_def 0;
BA_ "GenSigEnvVarType" SG_ 982 LH_Nebel_li_def 0;
BA_ "GenSigAutoGenSnd" SG_ 982 LH_Nebel_li_def 1;
BA_ "GenSigAutoGenDsp" SG_ 982 LH_Nebel_li_def 1;
BA_ "GenSigSwitchedByIgnition" SG_ 982 LH_Schluss_Brems_Nebel_li_def 0;
BA_ "GenSigSendType" SG_ 982 LH_Schluss_Brems_Nebel_li_def 0;
BA_ "GenSigSwitchedByIgnition" SG_ 982 LH_Schluss_Brems_Nebel_re_def 0;
BA_ "GenSigSendType" SG_ 982 LH_Schluss_Brems_Nebel_re_def 0;
BA_ "GenSigSwitchedByIgnition" SG_ 982 LH_Schluss_Brems_li_def 0;
BA_ "GenSigSendType" SG_ 982 LH_Schluss_Brems_li_def 0;
BA_ "GenSigEnvVarType" SG_ 982 LH_Schluss_Brems_li_def 0;
BA_ "GenSigAutoGenSnd" SG_ 982 LH_Schluss_Brems_li_def 1;
BA_ "GenSigAutoGenDsp" SG_ 982 LH_Schluss_Brems_li_def 1;
BA_ "GenSigSwitchedByIgnition" SG_ 982 LH_Schluss_Nebel_li_def 0;
BA_ "GenSigSendType" SG_ 982 LH_Schluss_Nebel_li_def 0;
BA_ "GenSigEnvVarType" SG_ 982 LH_Schluss_Nebel_li_def 0;
BA_ "GenSigAutoGenSnd" SG_ 982 LH_Schluss_Nebel_li_def 1;
BA_ "GenSigAutoGenDsp" SG_ 982 LH_Schluss_Nebel_li_def 1;
BA_ "GenSigSwitchedByIgnition" SG_ 982 LH_SL_BRL_BLK_li_def 0;
BA_ "GenSigSendType" SG_ 982 LH_SL_BRL_BLK_li_def 0;
BA_ "GenSigEnvVarType" SG_ 982 LH_SL_BRL_BLK_li_def 0;
BA_ "GenSigAutoGenSnd" SG_ 982 LH_SL_BRL_BLK_li_def 1;
BA_ "GenSigAutoGenDsp" SG_ 982 LH_SL_BRL_BLK_li_def 1;
BA_ "GenSigSwitchedByIgnition" SG_ 982 LH_Brems_Blk_li_def 0;
BA_ "GenSigSendType" SG_ 982 LH_Brems_Blk_li_def 0;
BA_ "GenSigEnvVarType" SG_ 982 LH_Brems_Blk_li_def 0;
BA_ "GenSigAutoGenSnd" SG_ 982 LH_Brems_Blk_li_def 1;
BA_ "GenSigAutoGenDsp" SG_ 982 LH_Brems_Blk_li_def 1;
BA_ "GenSigSwitchedByIgnition" SG_ 982 LH_Blinker_re_def 0;
BA_ "GenSigSendType" SG_ 982 LH_Blinker_re_def 0;
BA_ "GenSigEnvVarType" SG_ 982 LH_Blinker_re_def 0;
BA_ "GenSigAutoGenSnd" SG_ 982 LH_Blinker_re_def 1;
BA_ "GenSigAutoGenDsp" SG_ 982 LH_Blinker_re_def 1;
BA_ "GenSigSwitchedByIgnition" SG_ 982 LH_Bremsl_re_def 0;
BA_ "GenSigSendType" SG_ 982 LH_Bremsl_re_def 0;
BA_ "GenSigEnvVarType" SG_ 982 LH_Bremsl_re_def 0;
BA_ "GenSigAutoGenSnd" SG_ 982 LH_Bremsl_re_def 1;
BA_ "GenSigAutoGenDsp" SG_ 982 LH_Bremsl_re_def 1;
BA_ "GenSigSwitchedByIgnition" SG_ 982 LH_Schlusslicht_re_def 0;
BA_ "GenSigSendType" SG_ 982 LH_Schlusslicht_re_def 0;
BA_ "GenSigEnvVarType" SG_ 982 LH_Schlusslicht_re_def 0;
BA_ "GenSigAutoGenSnd" SG_ 982 LH_Schlusslicht_re_def 1;
BA_ "GenSigAutoGenDsp" SG_ 982 LH_Schlusslicht_re_def 1;
BA_ "GenSigSwitchedByIgnition" SG_ 982 LH_Rueckf_re_def 0;
BA_ "GenSigSendType" SG_ 982 LH_Rueckf_re_def 0;
BA_ "GenSigEnvVarType" SG_ 982 LH_Rueckf_re_def 0;
BA_ "GenSigAutoGenSnd" SG_ 982 LH_Rueckf_re_def 1;
BA_ "GenSigAutoGenDsp" SG_ 982 LH_Rueckf_re_def 1;
BA_ "GenSigSwitchedByIgnition" SG_ 982 LH_Nebel_re_def 0;
BA_ "GenSigSendType" SG_ 982 LH_Nebel_re_def 0;
BA_ "GenSigEnvVarType" SG_ 982 LH_Nebel_re_def 0;
BA_ "GenSigAutoGenSnd" SG_ 982 LH_Nebel_re_def 1;
BA_ "GenSigAutoGenDsp" SG_ 982 LH_Nebel_re_def 1;
BA_ "GenSigSwitchedByIgnition" SG_ 982 LH_Schluss_Brems_re_def 0;
BA_ "GenSigSendType" SG_ 982 LH_Schluss_Brems_re_def 0;
BA_ "GenSigEnvVarType" SG_ 982 LH_Schluss_Brems_re_def 0;
BA_ "GenSigAutoGenSnd" SG_ 982 LH_Schluss_Brems_re_def 1;
BA_ "GenSigAutoGenDsp" SG_ 982 LH_Schluss_Brems_re_def 1;
BA_ "GenSigSwitchedByIgnition" SG_ 982 LH_Schluss_Nebel_re_def 0;
BA_ "GenSigSendType" SG_ 982 LH_Schluss_Nebel_re_def 0;
BA_ "GenSigEnvVarType" SG_ 982 LH_Schluss_Nebel_re_def 0;
BA_ "GenSigAutoGenSnd" SG_ 982 LH_Schluss_Nebel_re_def 1;
BA_ "GenSigAutoGenDsp" SG_ 982 LH_Schluss_Nebel_re_def 1;
BA_ "GenSigSwitchedByIgnition" SG_ 982 LH_SL_BRL_BLK_re_def 0;
BA_ "GenSigSendType" SG_ 982 LH_SL_BRL_BLK_re_def 0;
BA_ "GenSigEnvVarType" SG_ 982 LH_SL_BRL_BLK_re_def 0;
BA_ "GenSigAutoGenSnd" SG_ 982 LH_SL_BRL_BLK_re_def 1;
BA_ "GenSigAutoGenDsp" SG_ 982 LH_SL_BRL_BLK_re_def 1;
BA_ "GenSigSwitchedByIgnition" SG_ 982 LH_Brems_Blk_re_def 0;
BA_ "GenSigSendType" SG_ 982 LH_Brems_Blk_re_def 0;
BA_ "GenSigEnvVarType" SG_ 982 LH_Brems_Blk_re_def 0;
BA_ "GenSigAutoGenSnd" SG_ 982 LH_Brems_Blk_re_def 1;
BA_ "GenSigAutoGenDsp" SG_ 982 LH_Brems_Blk_re_def 1;
BA_ "GenSigSwitchedByIgnition" SG_ 982 LH_Kennzl_def 0;
BA_ "GenSigSendType" SG_ 982 LH_Kennzl_def 0;
BA_ "GenSigEnvVarType" SG_ 982 LH_Kennzl_def 0;
BA_ "GenSigAutoGenSnd" SG_ 982 LH_Kennzl_def 1;
BA_ "GenSigAutoGenDsp" SG_ 982 LH_Kennzl_def 1;
BA_ "GenSigSwitchedByIgnition" SG_ 982 LH_3_Bremsl_def 0;
BA_ "GenSigSendType" SG_ 982 LH_3_Bremsl_def 0;
BA_ "GenSigEnvVarType" SG_ 982 LH_3_Bremsl_def 0;
BA_ "GenSigAutoGenSnd" SG_ 982 LH_3_Bremsl_def 1;
BA_ "GenSigAutoGenDsp" SG_ 982 LH_3_Bremsl_def 1;
BA_ "GenSigSwitchedByIgnition" SG_ 982 LH_Nebel_mi_def 0;
BA_ "GenSigSendType" SG_ 982 LH_Nebel_mi_def 0;
BA_ "GenSigEnvVarType" SG_ 982 LH_Nebel_mi_def 0;
BA_ "GenSigAutoGenSnd" SG_ 982 LH_Nebel_mi_def 1;
BA_ "GenSigAutoGenDsp" SG_ 982 LH_Nebel_mi_def 1;
BA_ "GenSigSwitchedByIgnition" SG_ 982 LH_Rueckf_mi_def 0;
BA_ "GenSigSendType" SG_ 982 LH_Rueckf_mi_def 0;
BA_ "GenSigEnvVarType" SG_ 982 LH_Rueckf_mi_def 0;
BA_ "GenSigAutoGenSnd" SG_ 982 LH_Rueckf_mi_def 1;
BA_ "GenSigAutoGenDsp" SG_ 982 LH_Rueckf_mi_def 1;
BA_ "GenSigSwitchedByIgnition" SG_ 982 LH_Bremsl_li_ges_def 0;
BA_ "GenSigSendType" SG_ 982 LH_Bremsl_li_ges_def 0;
BA_ "GenSigEnvVarType" SG_ 982 LH_Bremsl_li_ges_def 0;
BA_ "GenSigAutoGenSnd" SG_ 982 LH_Bremsl_li_ges_def 1;
BA_ "GenSigAutoGenDsp" SG_ 982 LH_Bremsl_li_ges_def 1;
BA_ "GenSigSwitchedByIgnition" SG_ 982 LH_Bremsl_re_ges_def 0;
BA_ "GenSigSendType" SG_ 982 LH_Bremsl_re_ges_def 0;
BA_ "GenSigEnvVarType" SG_ 982 LH_Bremsl_re_ges_def 0;
BA_ "GenSigAutoGenSnd" SG_ 982 LH_Bremsl_re_ges_def 1;
BA_ "GenSigAutoGenDsp" SG_ 982 LH_Bremsl_re_ges_def 1;
BA_ "GenSigSwitchedByIgnition" SG_ 2549875733 Log_Airbag_01_Req_Data 0;
BA_ "GenSigFuncType" SG_ 2549875733 Log_Airbag_01_Req_Data 9;
BA_ "GenSigAutoGenSnd" SG_ 2549875733 Log_Airbag_01_Req_Data 1;
BA_ "GenSigAutoGenDsp" SG_ 2549875733 Log_Airbag_01_Req_Data 1;
BA_ "GenSigSwitchedByIgnition" SG_ 2550006805 Log_Airbag_01_Resp_Data 0;
BA_ "GenSigFuncType" SG_ 2550006805 Log_Airbag_01_Resp_Data 9;
BA_ "GenSigAutoGenSnd" SG_ 2550006805 Log_Airbag_01_Resp_Data 1;
BA_ "GenSigAutoGenDsp" SG_ 2550006805 Log_Airbag_01_Resp_Data 1;
BA_ "GenSigSwitchedByIgnition" SG_ 2549941257 Log_Datenlogger_Req_Data 0;
BA_ "GenSigFuncType" SG_ 2549941257 Log_Datenlogger_Req_Data 9;
BA_ "GenSigAutoGenSnd" SG_ 2549941257 Log_Datenlogger_Req_Data 1;
BA_ "GenSigAutoGenDsp" SG_ 2549941257 Log_Datenlogger_Req_Data 1;
BA_ "GenSigSwitchedByIgnition" SG_ 2549875836 Log_EMotor_01_Req_Data 0;
BA_ "GenSigFuncType" SG_ 2549875836 Log_EMotor_01_Req_Data 9;
BA_ "GenSigAutoGenSnd" SG_ 2549875836 Log_EMotor_01_Req_Data 1;
BA_ "GenSigAutoGenDsp" SG_ 2549875836 Log_EMotor_01_Req_Data 1;
BA_ "GenSigSwitchedByIgnition" SG_ 2550006908 Log_EMotor_01_Resp_Data 0;
BA_ "GenSigFuncType" SG_ 2550006908 Log_EMotor_01_Resp_Data 9;
BA_ "GenSigAutoGenSnd" SG_ 2550006908 Log_EMotor_01_Resp_Data 1;
BA_ "GenSigAutoGenDsp" SG_ 2550006908 Log_EMotor_01_Resp_Data 1;
BA_ "GenSigSwitchedByIgnition" SG_ 2549875831 Log_Getriebe_01_Req_Data 0;
BA_ "GenSigFuncType" SG_ 2549875831 Log_Getriebe_01_Req_Data 9;
BA_ "GenSigAutoGenSnd" SG_ 2549875831 Log_Getriebe_01_Req_Data 1;
BA_ "GenSigAutoGenDsp" SG_ 2549875831 Log_Getriebe_01_Req_Data 1;
BA_ "GenSigSwitchedByIgnition" SG_ 2550006903 Log_Getriebe_01_Resp_Data 0;
BA_ "GenSigFuncType" SG_ 2550006903 Log_Getriebe_01_Resp_Data 9;
BA_ "GenSigAutoGenSnd" SG_ 2550006903 Log_Getriebe_01_Resp_Data 1;
BA_ "GenSigAutoGenDsp" SG_ 2550006903 Log_Getriebe_01_Resp_Data 1;
BA_ "GenSigSwitchedByIgnition" SG_ 2549875835 Log_Hybrid_01_Req_Data 0;
BA_ "GenSigFuncType" SG_ 2549875835 Log_Hybrid_01_Req_Data 9;
BA_ "GenSigAutoGenSnd" SG_ 2549875835 Log_Hybrid_01_Req_Data 1;
BA_ "GenSigAutoGenDsp" SG_ 2549875835 Log_Hybrid_01_Req_Data 1;
BA_ "GenSigSwitchedByIgnition" SG_ 2550006907 Log_Hybrid_01_Resp_Data 0;
BA_ "GenSigFuncType" SG_ 2550006907 Log_Hybrid_01_Resp_Data 9;
BA_ "GenSigAutoGenSnd" SG_ 2550006907 Log_Hybrid_01_Resp_Data 1;
BA_ "GenSigAutoGenDsp" SG_ 2550006907 Log_Hybrid_01_Resp_Data 1;
BA_ "GenSigSwitchedByIgnition" SG_ 2549875830 Log_MO_01_Req_Data 0;
BA_ "GenSigFuncType" SG_ 2549875830 Log_MO_01_Req_Data 9;
BA_ "GenSigAutoGenSnd" SG_ 2549875830 Log_MO_01_Req_Data 1;
BA_ "GenSigAutoGenDsp" SG_ 2549875830 Log_MO_01_Req_Data 1;
BA_ "GenSigSwitchedByIgnition" SG_ 2550006902 Log_MO_01_Resp_Data 0;
BA_ "GenSigFuncType" SG_ 2550006902 Log_MO_01_Resp_Data 9;
BA_ "GenSigAutoGenSnd" SG_ 2550006902 Log_MO_01_Resp_Data 1;
BA_ "GenSigAutoGenDsp" SG_ 2550006902 Log_MO_01_Resp_Data 1;
BA_ "GenSigSwitchedByIgnition" SG_ 2549875740 Log_Soundaktor_Req_Data 0;
BA_ "GenSigFuncType" SG_ 2549875740 Log_Soundaktor_Req_Data 9;
BA_ "GenSigAutoGenSnd" SG_ 2549875740 Log_Soundaktor_Req_Data 1;
BA_ "GenSigAutoGenDsp" SG_ 2549875740 Log_Soundaktor_Req_Data 1;
BA_ "GenSigSwitchedByIgnition" SG_ 2550006812 Log_Soundaktor_Resp_Data 0;
BA_ "GenSigFuncType" SG_ 2550006812 Log_Soundaktor_Resp_Data 9;
BA_ "GenSigAutoGenSnd" SG_ 2550006812 Log_Soundaktor_Resp_Data 1;
BA_ "GenSigAutoGenDsp" SG_ 2550006812 Log_Soundaktor_Resp_Data 1;
BA_ "GenSigFuncType" SG_ 134 LWI_01_CRC 2;
BA_ "GenSigSendType" SG_ 134 LWI_01_CRC 0;
BA_ "GenSigEnvVarType" SG_ 134 LWI_01_CRC 0;
BA_ "GenSigAutoGenSnd" SG_ 134 LWI_01_CRC 1;
BA_ "GenSigAutoGenDsp" SG_ 134 LWI_01_CRC 1;
BA_ "GenSigFuncType" SG_ 134 LWI_01_BZ 1;
BA_ "GenSigSendType" SG_ 134 LWI_01_BZ 0;
BA_ "GenSigEnvVarType" SG_ 134 LWI_01_BZ 0;
BA_ "GenSigAutoGenSnd" SG_ 134 LWI_01_BZ 1;
BA_ "GenSigAutoGenDsp" SG_ 134 LWI_01_BZ 1;
BA_ "GenSigSendType" SG_ 134 LWI_Sensorstatus 0;
BA_ "GenSigEnvVarType" SG_ 134 LWI_Sensorstatus 0;
BA_ "GenSigAutoGenSnd" SG_ 134 LWI_Sensorstatus 1;
BA_ "GenSigAutoGenDsp" SG_ 134 LWI_Sensorstatus 1;
BA_ "GenSigSendType" SG_ 134 LWI_QBit_Sub_Daten 0;
BA_ "GenSigEnvVarType" SG_ 134 LWI_QBit_Sub_Daten 0;
BA_ "GenSigAutoGenSnd" SG_ 134 LWI_QBit_Sub_Daten 1;
BA_ "GenSigAutoGenDsp" SG_ 134 LWI_QBit_Sub_Daten 1;
BA_ "GenSigStartValue" SG_ 134 LWI_QBit_Lenkradwinkel 1;
BA_ "GenSigSendType" SG_ 134 LWI_QBit_Lenkradwinkel 0;
BA_ "GenSigEnvVarType" SG_ 134 LWI_QBit_Lenkradwinkel 0;
BA_ "GenSigAutoGenSnd" SG_ 134 LWI_QBit_Lenkradwinkel 1;
BA_ "GenSigAutoGenDsp" SG_ 134 LWI_QBit_Lenkradwinkel 1;
BA_ "Fehlerwert" SG_ 134 LWI_Lenkradwinkel 8191;
BA_ "GenSigStartValue" SG_ 134 LWI_Lenkradwinkel 8190;
BA_ "GenSigSendType" SG_ 134 LWI_Lenkradwinkel 0;
BA_ "GenSigEnvVarType" SG_ 134 LWI_Lenkradwinkel 1;
BA_ "GenSigAutoGenSnd" SG_ 134 LWI_Lenkradwinkel 1;
BA_ "GenSigAutoGenDsp" SG_ 134 LWI_Lenkradwinkel 1;
BA_ "GenSigSendType" SG_ 134 LWI_VZ_Lenkradwinkel 0;
BA_ "GenSigEnvVarType" SG_ 134 LWI_VZ_Lenkradwinkel 0;
BA_ "GenSigAutoGenSnd" SG_ 134 LWI_VZ_Lenkradwinkel 1;
BA_ "GenSigAutoGenDsp" SG_ 134 LWI_VZ_Lenkradwinkel 1;
BA_ "GenSigSendType" SG_ 134 LWI_VZ_Lenkradw_Geschw 0;
BA_ "GenSigEnvVarType" SG_ 134 LWI_VZ_Lenkradw_Geschw 0;
BA_ "GenSigAutoGenSnd" SG_ 134 LWI_VZ_Lenkradw_Geschw 1;
BA_ "GenSigAutoGenDsp" SG_ 134 LWI_VZ_Lenkradw_Geschw 1;
BA_ "Fehlerwert" SG_ 134 LWI_Lenkradw_Geschw 511;
BA_ "GenSigStartValue" SG_ 134 LWI_Lenkradw_Geschw 510;
BA_ "GenSigSendType" SG_ 134 LWI_Lenkradw_Geschw 0;
BA_ "GenSigEnvVarType" SG_ 134 LWI_Lenkradw_Geschw 0;
BA_ "GenSigAutoGenSnd" SG_ 134 LWI_Lenkradw_Geschw 1;
BA_ "GenSigAutoGenDsp" SG_ 134 LWI_Lenkradw_Geschw 1;
BA_ "GenSigSendType" SG_ 134 LWI_Sub_Daten 0;
BA_ "GenSigEnvVarType" SG_ 134 LWI_Sub_Daten 0;
BA_ "GenSigAutoGenSnd" SG_ 134 LWI_Sub_Daten 1;
BA_ "GenSigAutoGenDsp" SG_ 134 LWI_Sub_Daten 1;
BA_ "GenSigSwitchedByIgnition" SG_ 263 MO_Istgang 0;
BA_ "GenSigSendType" SG_ 263 MO_Istgang 0;
BA_ "GenSigEnvVarType" SG_ 263 MO_Istgang 0;
BA_ "GenSigAutoGenSnd" SG_ 263 MO_Istgang 1;
BA_ "GenSigAutoGenDsp" SG_ 263 MO_Istgang 1;
BA_ "GenSigSwitchedByIgnition" SG_ 263 MO_Sollgang 0;
BA_ "GenSigSendType" SG_ 263 MO_Sollgang 0;
BA_ "GenSigEnvVarType" SG_ 263 MO_Sollgang 0;
BA_ "GenSigAutoGenSnd" SG_ 263 MO_Sollgang 1;
BA_ "GenSigAutoGenDsp" SG_ 263 MO_Sollgang 1;
BA_ "Fehlerwert" SG_ 263 MO_Oeldruck 255;
BA_ "GenSigSwitchedByIgnition" SG_ 263 MO_Oeldruck 0;
BA_ "GenSigStartValue" SG_ 263 MO_Oeldruck 254;
BA_ "GenSigSendType" SG_ 263 MO_Oeldruck 0;
BA_ "GenSigAutoGenSnd" SG_ 263 MO_Oeldruck 1;
BA_ "GenSigAutoGenDsp" SG_ 263 MO_Oeldruck 1;
BA_ "Fehlerwert" SG_ 263 MO_Anzeigedrehz 4095;
BA_ "GenSigSwitchedByIgnition" SG_ 263 MO_Anzeigedrehz 0;
BA_ "GenSigSendType" SG_ 263 MO_Anzeigedrehz 0;
BA_ "GenSigEnvVarType" SG_ 263 MO_Anzeigedrehz 0;
BA_ "GenSigAutoGenSnd" SG_ 263 MO_Anzeigedrehz 1;
BA_ "GenSigAutoGenDsp" SG_ 263 MO_Anzeigedrehz 1;
BA_ "GenSigSwitchedByIgnition" SG_ 263 MO_Schaltempf_verfbar 0;
BA_ "GenSigFuncType" SG_ 263 MO_Schaltempf_verfbar 8;
BA_ "GenSigSendType" SG_ 263 MO_Schaltempf_verfbar 0;
BA_ "GenSigEnvVarType" SG_ 263 MO_Schaltempf_verfbar 0;
BA_ "GenSigAutoGenSnd" SG_ 263 MO_Schaltempf_verfbar 1;
BA_ "GenSigAutoGenDsp" SG_ 263 MO_Schaltempf_verfbar 1;
BA_ "Fehlerwert" SG_ 263 MO_Ladedruck 511;
BA_ "GenSigSwitchedByIgnition" SG_ 263 MO_Ladedruck 0;
BA_ "GenSigSendType" SG_ 263 MO_Ladedruck 0;
BA_ "GenSigEnvVarType" SG_ 263 MO_Ladedruck 1;
BA_ "GenSigAutoGenSnd" SG_ 263 MO_Ladedruck 1;
BA_ "GenSigAutoGenDsp" SG_ 263 MO_Ladedruck 1;
BA_ "GenSigSwitchedByIgnition" SG_ 263 MO_KVS 0;
BA_ "GenSigSendType" SG_ 263 MO_KVS 0;
BA_ "GenSigEnvVarType" SG_ 263 MO_KVS 0;
BA_ "GenSigAutoGenSnd" SG_ 263 MO_KVS 1;
BA_ "GenSigAutoGenDsp" SG_ 263 MO_KVS 1;
BA_ "GenSigSwitchedByIgnition" SG_ 263 MO_KVS_Ueberlauf 0;
BA_ "GenSigSendType" SG_ 263 MO_KVS_Ueberlauf 0;
BA_ "GenSigEnvVarType" SG_ 263 MO_KVS_Ueberlauf 0;
BA_ "GenSigAutoGenSnd" SG_ 263 MO_KVS_Ueberlauf 1;
BA_ "GenSigAutoGenDsp" SG_ 263 MO_KVS_Ueberlauf 1;
BA_ "GenSigSwitchedByIgnition" SG_ 1600 MO_QBit_Ansaugluft_Temp 0;
BA_ "GenSigStartValue" SG_ 1600 MO_QBit_Ansaugluft_Temp 1;
BA_ "GenSigSendType" SG_ 1600 MO_QBit_Ansaugluft_Temp 0;
BA_ "GenSigEnvVarType" SG_ 1600 MO_QBit_Ansaugluft_Temp 0;
BA_ "GenSigAutoGenSnd" SG_ 1600 MO_QBit_Ansaugluft_Temp 1;
BA_ "GenSigAutoGenDsp" SG_ 1600 MO_QBit_Ansaugluft_Temp 1;
BA_ "GenSigSwitchedByIgnition" SG_ 1600 MO_QBit_Oel_Temp 0;
BA_ "GenSigStartValue" SG_ 1600 MO_QBit_Oel_Temp 1;
BA_ "GenSigSendType" SG_ 1600 MO_QBit_Oel_Temp 0;
BA_ "GenSigEnvVarType" SG_ 1600 MO_QBit_Oel_Temp 0;
BA_ "GenSigAutoGenSnd" SG_ 1600 MO_QBit_Oel_Temp 1;
BA_ "GenSigAutoGenDsp" SG_ 1600 MO_QBit_Oel_Temp 1;
BA_ "GenSigSwitchedByIgnition" SG_ 1600 MO_QBit_Kuehlmittel_Temp 0;
BA_ "GenSigStartValue" SG_ 1600 MO_QBit_Kuehlmittel_Temp 1;
BA_ "GenSigSendType" SG_ 1600 MO_QBit_Kuehlmittel_Temp 0;
BA_ "GenSigEnvVarType" SG_ 1600 MO_QBit_Kuehlmittel_Temp 0;
BA_ "GenSigAutoGenSnd" SG_ 1600 MO_QBit_Kuehlmittel_Temp 1;
BA_ "GenSigAutoGenDsp" SG_ 1600 MO_QBit_Kuehlmittel_Temp 1;
BA_ "GenSigSwitchedByIgnition" SG_ 1600 MO_Stellgliedtest_Soundaktuator 0;
BA_ "GenSigSendType" SG_ 1600 MO_Stellgliedtest_Soundaktuator 0;
BA_ "GenSigAutoGenSnd" SG_ 1600 MO_Stellgliedtest_Soundaktuator 1;
BA_ "GenSigAutoGenDsp" SG_ 1600 MO_Stellgliedtest_Soundaktuator 1;
BA_ "GenSigSwitchedByIgnition" SG_ 1600 MO_HYB_Fehler_HV_Netz 0;
BA_ "GenSigSendType" SG_ 1600 MO_HYB_Fehler_HV_Netz 0;
BA_ "GenSigAutoGenSnd" SG_ 1600 MO_HYB_Fehler_HV_Netz 1;
BA_ "GenSigAutoGenDsp" SG_ 1600 MO_HYB_Fehler_HV_Netz 1;
BA_ "GenSigSwitchedByIgnition" SG_ 1600 MO_aktives_Getriebeheizen 0;
BA_ "GenSigSendType" SG_ 1600 MO_aktives_Getriebeheizen 0;
BA_ "GenSigAutoGenSnd" SG_ 1600 MO_aktives_Getriebeheizen 1;
BA_ "GenSigAutoGenDsp" SG_ 1600 MO_aktives_Getriebeheizen 1;
BA_ "GenSigSwitchedByIgnition" SG_ 1600 MO_Absperrventil_oeffnen 0;
BA_ "GenSigSendType" SG_ 1600 MO_Absperrventil_oeffnen 0;
BA_ "GenSigAutoGenSnd" SG_ 1600 MO_Absperrventil_oeffnen 1;
BA_ "GenSigAutoGenDsp" SG_ 1600 MO_Absperrventil_oeffnen 1;
BA_ "Fehlerwert" SG_ 1600 MO_Ansaugluft_Temp 255;
BA_ "GenSigSwitchedByIgnition" SG_ 1600 MO_Ansaugluft_Temp 0;
BA_ "GenSigStartValue" SG_ 1600 MO_Ansaugluft_Temp 254;
BA_ "GenSigSendType" SG_ 1600 MO_Ansaugluft_Temp 0;
BA_ "GenSigEnvVarType" SG_ 1600 MO_Ansaugluft_Temp 1;
BA_ "GenSigAutoGenSnd" SG_ 1600 MO_Ansaugluft_Temp 1;
BA_ "GenSigAutoGenDsp" SG_ 1600 MO_Ansaugluft_Temp 1;
BA_ "Fehlerwert" SG_ 1600 MO_Oel_Temp 255;
BA_ "GenSigSwitchedByIgnition" SG_ 1600 MO_Oel_Temp 0;
BA_ "GenSigStartValue" SG_ 1600 MO_Oel_Temp 254;
BA_ "GenSigSendType" SG_ 1600 MO_Oel_Temp 0;
BA_ "GenSigEnvVarType" SG_ 1600 MO_Oel_Temp 0;
BA_ "GenSigAutoGenSnd" SG_ 1600 MO_Oel_Temp 1;
BA_ "GenSigAutoGenDsp" SG_ 1600 MO_Oel_Temp 1;
BA_ "Fehlerwert" SG_ 1600 MO_Kuehlmittel_Temp 255;
BA_ "GenSigSwitchedByIgnition" SG_ 1600 MO_Kuehlmittel_Temp 0;
BA_ "GenSigStartValue" SG_ 1600 MO_Kuehlmittel_Temp 254;
BA_ "GenSigSendType" SG_ 1600 MO_Kuehlmittel_Temp 0;
BA_ "GenSigEnvVarType" SG_ 1600 MO_Kuehlmittel_Temp 1;
BA_ "GenSigAutoGenSnd" SG_ 1600 MO_Kuehlmittel_Temp 1;
BA_ "GenSigAutoGenDsp" SG_ 1600 MO_Kuehlmittel_Temp 1;
BA_ "Fehlerwert" SG_ 1600 MO_Hoeheninfo 255;
BA_ "GenSigSwitchedByIgnition" SG_ 1600 MO_Hoeheninfo 0;
BA_ "GenSigSendType" SG_ 1600 MO_Hoeheninfo 0;
BA_ "GenSigEnvVarType" SG_ 1600 MO_Hoeheninfo 1;
BA_ "GenSigAutoGenSnd" SG_ 1600 MO_Hoeheninfo 1;
BA_ "GenSigAutoGenDsp" SG_ 1600 MO_Hoeheninfo 1;
BA_ "GenSigSwitchedByIgnition" SG_ 1600 MO_Kennfeldk 0;
BA_ "GenSigSendType" SG_ 1600 MO_Kennfeldk 0;
BA_ "GenSigEnvVarType" SG_ 1600 MO_Kennfeldk 0;
BA_ "GenSigAutoGenSnd" SG_ 1600 MO_Kennfeldk 1;
BA_ "GenSigAutoGenDsp" SG_ 1600 MO_Kennfeldk 1;
BA_ "GenSigSwitchedByIgnition" SG_ 1600 MO_Versionsinfo 0;
BA_ "GenSigSendType" SG_ 1600 MO_Versionsinfo 0;
BA_ "GenSigEnvVarType" SG_ 1600 MO_Versionsinfo 0;
BA_ "GenSigAutoGenSnd" SG_ 1600 MO_Versionsinfo 1;
BA_ "GenSigAutoGenDsp" SG_ 1600 MO_Versionsinfo 1;
BA_ "GenSigSwitchedByIgnition" SG_ 1600 MO_Getriebe_kuehlen 0;
BA_ "GenSigSendType" SG_ 1600 MO_Getriebe_kuehlen 0;
BA_ "GenSigAutoGenSnd" SG_ 1600 MO_Getriebe_kuehlen 1;
BA_ "GenSigAutoGenDsp" SG_ 1600 MO_Getriebe_kuehlen 1;
BA_ "GenSigSwitchedByIgnition" SG_ 1600 MO_Mom_Traegheit_02 0;
BA_ "GenSigSendType" SG_ 1600 MO_Mom_Traegheit_02 0;
BA_ "GenSigEnvVarType" SG_ 1600 MO_Mom_Traegheit_02 1;
BA_ "GenSigAutoGenSnd" SG_ 1600 MO_Mom_Traegheit_02 1;
BA_ "GenSigAutoGenDsp" SG_ 1600 MO_Mom_Traegheit_02 1;
BA_ "GenSigSwitchedByIgnition" SG_ 1600 MO_Heizungspumpenansteuerung 0;
BA_ "GenSigStartValue" SG_ 1600 MO_Heizungspumpenansteuerung 14;
BA_ "GenSigSendType" SG_ 1600 MO_Heizungspumpenansteuerung 0;
BA_ "GenSigAutoGenSnd" SG_ 1600 MO_Heizungspumpenansteuerung 1;
BA_ "GenSigAutoGenDsp" SG_ 1600 MO_Heizungspumpenansteuerung 1;
BA_ "GenSigSwitchedByIgnition" SG_ 1600 MO_SpannungsAnf 0;
BA_ "GenSigSendType" SG_ 1600 MO_SpannungsAnf 0;
BA_ "GenSigAutoGenSnd" SG_ 1600 MO_SpannungsAnf 1;
BA_ "GenSigAutoGenDsp" SG_ 1600 MO_SpannungsAnf 1;
BA_ "GenSigSwitchedByIgnition" SG_ 1600 MO_Nachlaufzeit_Heizungspumpe 0;
BA_ "GenSigSendType" SG_ 1600 MO_Nachlaufzeit_Heizungspumpe 0;
BA_ "Fehlerwert" SG_ 1607 MO_ITM_Kuehlmittel_Temp 2;
BA_ "GenSigSwitchedByIgnition" SG_ 1607 MO_ITM_Kuehlmittel_Temp 0;
BA_ "GenSigStartValue" SG_ 1607 MO_ITM_Kuehlmittel_Temp 1;
BA_ "GenSigSendType" SG_ 1607 MO_ITM_Kuehlmittel_Temp 0;
BA_ "Fehlerwert" SG_ 1607 MO_E85_Sensor 15;
BA_ "GenSigSwitchedByIgnition" SG_ 1607 MO_E85_Sensor 0;
BA_ "GenSigStartValue" SG_ 1607 MO_E85_Sensor 14;
BA_ "GenSigSendType" SG_ 1607 MO_E85_Sensor 0;
BA_ "GenSigSwitchedByIgnition" SG_ 1607 SCR_Anz_Motorstarts 0;
BA_ "GenSigStartValue" SG_ 1607 SCR_Anz_Motorstarts 15;
BA_ "GenSigSendType" SG_ 1607 SCR_Anz_Motorstarts 0;
BA_ "GenSigAutoGenSnd" SG_ 1607 SCR_Anz_Motorstarts 1;
BA_ "GenSigAutoGenDsp" SG_ 1607 SCR_Anz_Motorstarts 1;
BA_ "GenSigSwitchedByIgnition" SG_ 1607 SCR_Reichweite 0;
BA_ "GenSigStartValue" SG_ 1607 SCR_Reichweite 32767;
BA_ "GenSigSendType" SG_ 1607 SCR_Reichweite 0;
BA_ "GenSigAutoGenSnd" SG_ 1607 SCR_Reichweite 1;
BA_ "GenSigAutoGenDsp" SG_ 1607 SCR_Reichweite 1;
BA_ "GenSigSwitchedByIgnition" SG_ 1607 SCR_Warnstufe_1 0;
BA_ "GenSigSendType" SG_ 1607 SCR_Warnstufe_1 0;
BA_ "GenSigAutoGenSnd" SG_ 1607 SCR_Warnstufe_1 1;
BA_ "GenSigAutoGenDsp" SG_ 1607 SCR_Warnstufe_1 1;
BA_ "GenSigSwitchedByIgnition" SG_ 1607 SCR_Warnstufe_2 0;
BA_ "GenSigSendType" SG_ 1607 SCR_Warnstufe_2 0;
BA_ "GenSigAutoGenSnd" SG_ 1607 SCR_Warnstufe_2 1;
BA_ "GenSigAutoGenDsp" SG_ 1607 SCR_Warnstufe_2 1;
BA_ "GenSigSwitchedByIgnition" SG_ 1607 SCR_Text 0;
BA_ "GenSigSendType" SG_ 1607 SCR_Text 0;
BA_ "GenSigAutoGenSnd" SG_ 1607 SCR_Text 1;
BA_ "GenSigAutoGenDsp" SG_ 1607 SCR_Text 1;
BA_ "GenSigSwitchedByIgnition" SG_ 1607 SCR_Akustik 0;
BA_ "GenSigSendType" SG_ 1607 SCR_Akustik 0;
BA_ "GenSigAutoGenSnd" SG_ 1607 SCR_Akustik 1;
BA_ "GenSigAutoGenDsp" SG_ 1607 SCR_Akustik 1;
BA_ "GenSigSwitchedByIgnition" SG_ 1607 MO_Kraftstofffilter_Wasser 0;
BA_ "GenSigSendType" SG_ 1607 MO_Kraftstofffilter_Wasser 0;
BA_ "GenSigAutoGenSnd" SG_ 1607 MO_Kraftstofffilter_Wasser 1;
BA_ "GenSigAutoGenDsp" SG_ 1607 MO_Kraftstofffilter_Wasser 1;
BA_ "GenSigSwitchedByIgnition" SG_ 1607 SCR_Systemfehler 0;
BA_ "GenSigSendType" SG_ 1607 SCR_Systemfehler 0;
BA_ "GenSigAutoGenSnd" SG_ 1607 SCR_Systemfehler 1;
BA_ "GenSigAutoGenDsp" SG_ 1607 SCR_Systemfehler 1;
BA_ "GenSigSwitchedByIgnition" SG_ 1607 SCR_Inducement_Strategie 0;
BA_ "GenSigSendType" SG_ 1607 SCR_Inducement_Strategie 0;
BA_ "GenSigAutoGenSnd" SG_ 1607 SCR_Inducement_Strategie 1;
BA_ "GenSigAutoGenDsp" SG_ 1607 SCR_Inducement_Strategie 1;
BA_ "Fehlerwert" SG_ 1607 MO_CO2_Faktor 4095;
BA_ "GenSigSwitchedByIgnition" SG_ 1607 MO_CO2_Faktor 0;
BA_ "GenSigSendType" SG_ 1607 MO_CO2_Faktor 0;
BA_ "GenSigAutoGenSnd" SG_ 1607 MO_CO2_Faktor 1;
BA_ "GenSigAutoGenDsp" SG_ 1607 MO_CO2_Faktor 1;
BA_ "GenSigSwitchedByIgnition" SG_ 1607 MO_MKB_MUX 0;
BA_ "GenSigSendType" SG_ 1607 MO_MKB_MUX 0;
BA_ "GenSigAutoGenSnd" SG_ 1607 MO_MKB_MUX 1;
BA_ "GenSigAutoGenDsp" SG_ 1607 MO_MKB_MUX 1;
BA_ "GenSigSwitchedByIgnition" SG_ 1607 MO_MKB_01 0;
BA_ "GenSigAutoGenSnd" SG_ 1607 MO_MKB_01 1;
BA_ "GenSigAutoGenDsp" SG_ 1607 MO_MKB_01 1;
BA_ "GenSigSwitchedByIgnition" SG_ 1607 MO_MKB_02 0;
BA_ "GenSigAutoGenSnd" SG_ 1607 MO_MKB_02 1;
BA_ "GenSigAutoGenDsp" SG_ 1607 MO_MKB_02 1;
BA_ "GenSigSwitchedByIgnition" SG_ 1607 MO_MKB_03 0;
BA_ "GenSigAutoGenSnd" SG_ 1607 MO_MKB_03 1;
BA_ "GenSigAutoGenDsp" SG_ 1607 MO_MKB_03 1;
BA_ "GenSigSwitchedByIgnition" SG_ 1607 MO_MKB_04 0;
BA_ "GenSigAutoGenSnd" SG_ 1607 MO_MKB_04 1;
BA_ "GenSigAutoGenDsp" SG_ 1607 MO_MKB_04 1;
BA_ "GenSigSwitchedByIgnition" SG_ 167 Motor_11_CRC 0;
BA_ "GenSigFuncType" SG_ 167 Motor_11_CRC 2;
BA_ "GenSigSendType" SG_ 167 Motor_11_CRC 0;
BA_ "GenSigEnvVarType" SG_ 167 Motor_11_CRC 0;
BA_ "GenSigAutoGenSnd" SG_ 167 Motor_11_CRC 1;
BA_ "GenSigAutoGenDsp" SG_ 167 Motor_11_CRC 1;
BA_ "GenSigSwitchedByIgnition" SG_ 167 Motor_11_BZ 0;
BA_ "GenSigFuncType" SG_ 167 Motor_11_BZ 1;
BA_ "GenSigSendType" SG_ 167 Motor_11_BZ 0;
BA_ "GenSigEnvVarType" SG_ 167 Motor_11_BZ 0;
BA_ "GenSigAutoGenSnd" SG_ 167 Motor_11_BZ 1;
BA_ "GenSigAutoGenDsp" SG_ 167 Motor_11_BZ 1;
BA_ "Fehlerwert" SG_ 167 MO_Mom_Soll_Roh 1023;
BA_ "GenSigSwitchedByIgnition" SG_ 167 MO_Mom_Soll_Roh 0;
BA_ "GenSigStartValue" SG_ 167 MO_Mom_Soll_Roh 1022;
BA_ "GenSigSendType" SG_ 167 MO_Mom_Soll_Roh 0;
BA_ "GenSigEnvVarType" SG_ 167 MO_Mom_Soll_Roh 0;
BA_ "GenSigAutoGenSnd" SG_ 167 MO_Mom_Soll_Roh 1;
BA_ "GenSigAutoGenDsp" SG_ 167 MO_Mom_Soll_Roh 1;
BA_ "Fehlerwert" SG_ 167 MO_Mom_Ist_Summe 1023;
BA_ "GenSigSwitchedByIgnition" SG_ 167 MO_Mom_Ist_Summe 0;
BA_ "GenSigStartValue" SG_ 167 MO_Mom_Ist_Summe 1022;
BA_ "GenSigSendType" SG_ 167 MO_Mom_Ist_Summe 0;
BA_ "GenSigEnvVarType" SG_ 167 MO_Mom_Ist_Summe 0;
BA_ "GenSigAutoGenSnd" SG_ 167 MO_Mom_Ist_Summe 1;
BA_ "GenSigAutoGenDsp" SG_ 167 MO_Mom_Ist_Summe 1;
BA_ "Fehlerwert" SG_ 167 MO_Mom_Traegheit_Summe 1023;
BA_ "GenSigSwitchedByIgnition" SG_ 167 MO_Mom_Traegheit_Summe 0;
BA_ "GenSigStartValue" SG_ 167 MO_Mom_Traegheit_Summe 1022;
BA_ "GenSigSendType" SG_ 167 MO_Mom_Traegheit_Summe 0;
BA_ "GenSigEnvVarType" SG_ 167 MO_Mom_Traegheit_Summe 0;
BA_ "GenSigAutoGenSnd" SG_ 167 MO_Mom_Traegheit_Summe 1;
BA_ "GenSigAutoGenDsp" SG_ 167 MO_Mom_Traegheit_Summe 1;
BA_ "Fehlerwert" SG_ 167 MO_Mom_Soll_gefiltert 1023;
BA_ "GenSigSwitchedByIgnition" SG_ 167 MO_Mom_Soll_gefiltert 0;
BA_ "GenSigStartValue" SG_ 167 MO_Mom_Soll_gefiltert 1022;
BA_ "GenSigSendType" SG_ 167 MO_Mom_Soll_gefiltert 0;
BA_ "GenSigEnvVarType" SG_ 167 MO_Mom_Soll_gefiltert 0;
BA_ "GenSigAutoGenSnd" SG_ 167 MO_Mom_Soll_gefiltert 1;
BA_ "GenSigAutoGenDsp" SG_ 167 MO_Mom_Soll_gefiltert 1;
BA_ "Fehlerwert" SG_ 167 MO_Mom_Schub 1023;
BA_ "GenSigSwitchedByIgnition" SG_ 167 MO_Mom_Schub 0;
BA_ "GenSigStartValue" SG_ 167 MO_Mom_Schub 510;
BA_ "GenSigSendType" SG_ 167 MO_Mom_Schub 0;
BA_ "GenSigEnvVarType" SG_ 167 MO_Mom_Schub 0;
BA_ "GenSigAutoGenSnd" SG_ 167 MO_Mom_Schub 1;
BA_ "GenSigAutoGenDsp" SG_ 167 MO_Mom_Schub 1;
BA_ "GenSigSwitchedByIgnition" SG_ 167 MO_Status_Normalbetrieb_01 0;
BA_ "GenSigSendType" SG_ 167 MO_Status_Normalbetrieb_01 0;
BA_ "GenSigEnvVarType" SG_ 167 MO_Status_Normalbetrieb_01 0;
BA_ "GenSigAutoGenSnd" SG_ 167 MO_Status_Normalbetrieb_01 1;
BA_ "GenSigAutoGenDsp" SG_ 167 MO_Status_Normalbetrieb_01 1;
BA_ "GenSigSwitchedByIgnition" SG_ 167 MO_erste_Ungenauschwelle 0;
BA_ "GenSigSendType" SG_ 167 MO_erste_Ungenauschwelle 0;
BA_ "GenSigEnvVarType" SG_ 167 MO_erste_Ungenauschwelle 0;
BA_ "GenSigAutoGenSnd" SG_ 167 MO_erste_Ungenauschwelle 1;
BA_ "GenSigAutoGenDsp" SG_ 167 MO_erste_Ungenauschwelle 1;
BA_ "GenSigSwitchedByIgnition" SG_ 167 MO_QBit_Motormomente 0;
BA_ "GenSigStartValue" SG_ 167 MO_QBit_Motormomente 1;
BA_ "GenSigSendType" SG_ 167 MO_QBit_Motormomente 0;
BA_ "GenSigEnvVarType" SG_ 167 MO_QBit_Motormomente 0;
BA_ "GenSigAutoGenSnd" SG_ 167 MO_QBit_Motormomente 1;
BA_ "GenSigAutoGenDsp" SG_ 167 MO_QBit_Motormomente 1;
BA_ "GenSigSwitchedByIgnition" SG_ 168 Motor_12_CRC 0;
BA_ "GenSigFuncType" SG_ 168 Motor_12_CRC 2;
BA_ "GenSigSendType" SG_ 168 Motor_12_CRC 0;
BA_ "GenSigEnvVarType" SG_ 168 Motor_12_CRC 0;
BA_ "GenSigAutoGenSnd" SG_ 168 Motor_12_CRC 1;
BA_ "GenSigAutoGenDsp" SG_ 168 Motor_12_CRC 1;
BA_ "GenSigSwitchedByIgnition" SG_ 168 Motor_12_BZ 0;
BA_ "GenSigFuncType" SG_ 168 Motor_12_BZ 1;
BA_ "GenSigSendType" SG_ 168 Motor_12_BZ 0;
BA_ "GenSigEnvVarType" SG_ 168 Motor_12_BZ 0;
BA_ "GenSigAutoGenSnd" SG_ 168 Motor_12_BZ 1;
BA_ "GenSigAutoGenDsp" SG_ 168 Motor_12_BZ 1;
BA_ "Fehlerwert" SG_ 168 MO_Mom_neg_verfuegbar 1023;
BA_ "GenSigSwitchedByIgnition" SG_ 168 MO_Mom_neg_verfuegbar 0;
BA_ "GenSigSendType" SG_ 168 MO_Mom_neg_verfuegbar 0;
BA_ "Fehlerwert" SG_ 168 MO_Mom_Begr_stat 1023;
BA_ "GenSigSwitchedByIgnition" SG_ 168 MO_Mom_Begr_stat 0;
BA_ "GenSigStartValue" SG_ 168 MO_Mom_Begr_stat 510;
BA_ "GenSigSendType" SG_ 168 MO_Mom_Begr_stat 0;
BA_ "GenSigEnvVarType" SG_ 168 MO_Mom_Begr_stat 0;
BA_ "GenSigAutoGenSnd" SG_ 168 MO_Mom_Begr_stat 1;
BA_ "GenSigAutoGenDsp" SG_ 168 MO_Mom_Begr_stat 1;
BA_ "Fehlerwert" SG_ 168 MO_Mom_Begr_dyn 1023;
BA_ "GenSigSwitchedByIgnition" SG_ 168 MO_Mom_Begr_dyn 0;
BA_ "GenSigStartValue" SG_ 168 MO_Mom_Begr_dyn 1022;
BA_ "GenSigSendType" SG_ 168 MO_Mom_Begr_dyn 0;
BA_ "GenSigEnvVarType" SG_ 168 MO_Mom_Begr_dyn 0;
BA_ "GenSigAutoGenSnd" SG_ 168 MO_Mom_Begr_dyn 1;
BA_ "GenSigAutoGenDsp" SG_ 168 MO_Mom_Begr_dyn 1;
BA_ "GenSigSwitchedByIgnition" SG_ 168 MO_Momentenintegral_02 0;
BA_ "GenSigSendType" SG_ 168 MO_Momentenintegral_02 0;
BA_ "GenSigEnvVarType" SG_ 168 MO_Momentenintegral_02 1;
BA_ "GenSigAutoGenSnd" SG_ 168 MO_Momentenintegral_02 1;
BA_ "GenSigAutoGenDsp" SG_ 168 MO_Momentenintegral_02 1;
BA_ "GenSigSwitchedByIgnition" SG_ 168 MO_QBit_Drehzahl_01 0;
BA_ "GenSigStartValue" SG_ 168 MO_QBit_Drehzahl_01 1;
BA_ "GenSigSendType" SG_ 168 MO_QBit_Drehzahl_01 0;
BA_ "GenSigEnvVarType" SG_ 168 MO_QBit_Drehzahl_01 0;
BA_ "GenSigAutoGenSnd" SG_ 168 MO_QBit_Drehzahl_01 1;
BA_ "GenSigAutoGenDsp" SG_ 168 MO_QBit_Drehzahl_01 1;
BA_ "Fehlerwert" SG_ 168 MO_Drehzahl_01 65535;
BA_ "GenSigSwitchedByIgnition" SG_ 168 MO_Drehzahl_01 0;
BA_ "GenSigSendType" SG_ 168 MO_Drehzahl_01 0;
BA_ "GenSigEnvVarType" SG_ 168 MO_Drehzahl_01 1;
BA_ "GenSigAutoGenSnd" SG_ 168 MO_Drehzahl_01 1;
BA_ "GenSigAutoGenDsp" SG_ 168 MO_Drehzahl_01 1;
BA_ "GenSigSwitchedByIgnition" SG_ 958 MO_StartStopp_Status 0;
BA_ "GenSigSendType" SG_ 958 MO_StartStopp_Status 0;
BA_ "GenSigAutoGenSnd" SG_ 958 MO_StartStopp_Status 1;
BA_ "GenSigAutoGenDsp" SG_ 958 MO_StartStopp_Status 1;
BA_ "GenSigSwitchedByIgnition" SG_ 958 MO_StartStopp_Wiederstart 0;
BA_ "GenSigSendType" SG_ 958 MO_StartStopp_Wiederstart 3;
BA_ "GenSigAutoGenSnd" SG_ 958 MO_StartStopp_Wiederstart 1;
BA_ "GenSigAutoGenDsp" SG_ 958 MO_StartStopp_Wiederstart 1;
BA_ "GenSigSwitchedByIgnition" SG_ 958 MO_StartStopp_Motorstopp 0;
BA_ "GenSigSendType" SG_ 958 MO_StartStopp_Motorstopp 3;
BA_ "GenSigAutoGenSnd" SG_ 958 MO_StartStopp_Motorstopp 1;
BA_ "GenSigAutoGenDsp" SG_ 958 MO_StartStopp_Motorstopp 1;
BA_ "GenSigSwitchedByIgnition" SG_ 958 MO_Freig_Reku 0;
BA_ "GenSigSendType" SG_ 958 MO_Freig_Reku 0;
BA_ "GenSigAutoGenSnd" SG_ 958 MO_Freig_Reku 1;
BA_ "GenSigAutoGenDsp" SG_ 958 MO_Freig_Reku 1;
BA_ "GenSigSwitchedByIgnition" SG_ 958 MO_Kl_75 0;
BA_ "GenSigSendType" SG_ 958 MO_Kl_75 3;
BA_ "GenSigEnvVarType" SG_ 958 MO_Kl_75 0;
BA_ "GenSigAutoGenSnd" SG_ 958 MO_Kl_75 1;
BA_ "GenSigAutoGenDsp" SG_ 958 MO_Kl_75 1;
BA_ "GenSigSwitchedByIgnition" SG_ 958 MO_Kl_50 0;
BA_ "GenSigSendType" SG_ 958 MO_Kl_50 3;
BA_ "GenSigEnvVarType" SG_ 958 MO_Kl_50 0;
BA_ "GenSigAutoGenSnd" SG_ 958 MO_Kl_50 1;
BA_ "GenSigAutoGenDsp" SG_ 958 MO_Kl_50 1;
BA_ "Fehlerwert" SG_ 958 MO_Gangposition 15;
BA_ "GenSigSwitchedByIgnition" SG_ 958 MO_Gangposition 0;
BA_ "GenSigStartValue" SG_ 958 MO_Gangposition 14;
BA_ "GenSigSendType" SG_ 958 MO_Gangposition 3;
BA_ "GenSigAutoGenSnd" SG_ 958 MO_Gangposition 1;
BA_ "GenSigAutoGenDsp" SG_ 958 MO_Gangposition 1;
BA_ "GenSigSwitchedByIgnition" SG_ 958 MO_StartStopp_Fahrerwunsch 0;
BA_ "GenSigSendType" SG_ 958 MO_StartStopp_Fahrerwunsch 0;
BA_ "GenSigSwitchedByIgnition" SG_ 958 MO_HYB_Fahrbereitschaft 0;
BA_ "GenSigSendType" SG_ 958 MO_HYB_Fahrbereitschaft 0;
BA_ "GenSigAutoGenSnd" SG_ 958 MO_HYB_Fahrbereitschaft 1;
BA_ "GenSigAutoGenDsp" SG_ 958 MO_HYB_Fahrbereitschaft 1;
BA_ "GenSigSwitchedByIgnition" SG_ 958 MO_Ext_E_Fahrt_aktiv 0;
BA_ "NWM-WakeupAllowed" SG_ 958 MO_Ext_E_Fahrt_aktiv 1;
BA_ "GenSigSendType" SG_ 958 MO_Ext_E_Fahrt_aktiv 3;
BA_ "GenSigAutoGenSnd" SG_ 958 MO_Ext_E_Fahrt_aktiv 1;
BA_ "GenSigAutoGenDsp" SG_ 958 MO_Ext_E_Fahrt_aktiv 1;
BA_ "GenSigSwitchedByIgnition" SG_ 958 MO_Fahrer_bremst 0;
BA_ "GenSigSendType" SG_ 958 MO_Fahrer_bremst 3;
BA_ "GenSigEnvVarType" SG_ 958 MO_Fahrer_bremst 0;
BA_ "GenSigAutoGenSnd" SG_ 958 MO_Fahrer_bremst 1;
BA_ "GenSigAutoGenDsp" SG_ 958 MO_Fahrer_bremst 1;
BA_ "GenSigSwitchedByIgnition" SG_ 958 MO_QBit_Fahrer_bremst 0;
BA_ "GenSigStartValue" SG_ 958 MO_QBit_Fahrer_bremst 1;
BA_ "GenSigSendType" SG_ 958 MO_QBit_Fahrer_bremst 3;
BA_ "GenSigEnvVarType" SG_ 958 MO_QBit_Fahrer_bremst 0;
BA_ "GenSigAutoGenSnd" SG_ 958 MO_QBit_Fahrer_bremst 1;
BA_ "GenSigAutoGenDsp" SG_ 958 MO_QBit_Fahrer_bremst 1;
BA_ "GenSigSwitchedByIgnition" SG_ 958 MO_BLS 0;
BA_ "GenSigSendType" SG_ 958 MO_BLS 3;
BA_ "GenSigEnvVarType" SG_ 958 MO_BLS 0;
BA_ "GenSigAutoGenSnd" SG_ 958 MO_BLS 1;
BA_ "GenSigAutoGenDsp" SG_ 958 MO_BLS 1;
BA_ "GenSigSwitchedByIgnition" SG_ 958 MO_Konsistenz_Bremsped 0;
BA_ "GenSigSendType" SG_ 958 MO_Konsistenz_Bremsped 3;
BA_ "GenSigEnvVarType" SG_ 958 MO_Konsistenz_Bremsped 0;
BA_ "GenSigAutoGenSnd" SG_ 958 MO_Konsistenz_Bremsped 1;
BA_ "GenSigAutoGenDsp" SG_ 958 MO_Konsistenz_Bremsped 1;
BA_ "GenSigSwitchedByIgnition" SG_ 958 MO_Timeout_ESP 0;
BA_ "GenSigSendType" SG_ 958 MO_Timeout_ESP 3;
BA_ "GenSigEnvVarType" SG_ 958 MO_Timeout_ESP 0;
BA_ "GenSigAutoGenSnd" SG_ 958 MO_Timeout_ESP 1;
BA_ "GenSigAutoGenDsp" SG_ 958 MO_Timeout_ESP 1;
BA_ "GenSigSwitchedByIgnition" SG_ 958 MO_Klima_Eingr 0;
BA_ "GenSigSendType" SG_ 958 MO_Klima_Eingr 0;
BA_ "GenSigEnvVarType" SG_ 958 MO_Klima_Eingr 0;
BA_ "GenSigAutoGenSnd" SG_ 958 MO_Klima_Eingr 1;
BA_ "GenSigAutoGenDsp" SG_ 958 MO_Klima_Eingr 1;
BA_ "GenSigSwitchedByIgnition" SG_ 958 MO_Aussp_Anlass 0;
BA_ "GenSigSendType" SG_ 958 MO_Aussp_Anlass 3;
BA_ "GenSigEnvVarType" SG_ 958 MO_Aussp_Anlass 0;
BA_ "GenSigAutoGenSnd" SG_ 958 MO_Aussp_Anlass 1;
BA_ "GenSigAutoGenDsp" SG_ 958 MO_Aussp_Anlass 1;
BA_ "GenSigSwitchedByIgnition" SG_ 958 MO_Freig_Anlass 0;
BA_ "GenSigSendType" SG_ 958 MO_Freig_Anlass 3;
BA_ "GenSigEnvVarType" SG_ 958 MO_Freig_Anlass 0;
BA_ "GenSigAutoGenSnd" SG_ 958 MO_Freig_Anlass 1;
BA_ "GenSigAutoGenDsp" SG_ 958 MO_Freig_Anlass 1;
BA_ "GenSigSwitchedByIgnition" SG_ 958 MO_Kuppl_schalter 0;
BA_ "GenSigSendType" SG_ 958 MO_Kuppl_schalter 3;
BA_ "GenSigEnvVarType" SG_ 958 MO_Kuppl_schalter 0;
BA_ "GenSigAutoGenSnd" SG_ 958 MO_Kuppl_schalter 1;
BA_ "GenSigAutoGenDsp" SG_ 958 MO_Kuppl_schalter 1;
BA_ "GenSigSwitchedByIgnition" SG_ 958 MO_Interlock 0;
BA_ "GenSigSendType" SG_ 958 MO_Interlock 3;
BA_ "GenSigEnvVarType" SG_ 958 MO_Interlock 0;
BA_ "GenSigAutoGenSnd" SG_ 958 MO_Interlock 1;
BA_ "GenSigAutoGenDsp" SG_ 958 MO_Interlock 1;
BA_ "GenSigSwitchedByIgnition" SG_ 958 MO_Motor_laeuft 0;
BA_ "GenSigSendType" SG_ 958 MO_Motor_laeuft 3;
BA_ "GenSigEnvVarType" SG_ 958 MO_Motor_laeuft 0;
BA_ "GenSigAutoGenSnd" SG_ 958 MO_Motor_laeuft 1;
BA_ "GenSigAutoGenDsp" SG_ 958 MO_Motor_laeuft 1;
BA_ "GenSigSwitchedByIgnition" SG_ 958 MO_Kickdown 0;
BA_ "GenSigSendType" SG_ 958 MO_Kickdown 3;
BA_ "GenSigEnvVarType" SG_ 958 MO_Kickdown 0;
BA_ "GenSigAutoGenSnd" SG_ 958 MO_Kickdown 1;
BA_ "GenSigAutoGenDsp" SG_ 958 MO_Kickdown 1;
BA_ "GenSigSwitchedByIgnition" SG_ 958 MO_Status_Zylabschalt_01 0;
BA_ "GenSigSendType" SG_ 958 MO_Status_Zylabschalt_01 3;
BA_ "GenSigEnvVarType" SG_ 958 MO_Status_Zylabschalt_01 0;
BA_ "GenSigAutoGenSnd" SG_ 958 MO_Status_Zylabschalt_01 1;
BA_ "GenSigAutoGenDsp" SG_ 958 MO_Status_Zylabschalt_01 1;
BA_ "GenSigSwitchedByIgnition" SG_ 958 MO_EKlKomLeiRed 0;
BA_ "GenSigSendType" SG_ 958 MO_EKlKomLeiRed 0;
BA_ "GenSigAutoGenSnd" SG_ 958 MO_EKlKomLeiRed 1;
BA_ "GenSigAutoGenDsp" SG_ 958 MO_EKlKomLeiRed 1;
BA_ "GenSigSwitchedByIgnition" SG_ 958 MO_Handshake_STH 0;
BA_ "GenSigSendType" SG_ 958 MO_Handshake_STH 5;
BA_ "GenSigEnvVarType" SG_ 958 MO_Handshake_STH 0;
BA_ "GenSigAutoGenSnd" SG_ 958 MO_Handshake_STH 1;
BA_ "GenSigAutoGenDsp" SG_ 958 MO_Handshake_STH 1;
BA_ "GenSigSwitchedByIgnition" SG_ 958 MO_BKV_Unterdruckwarnung 0;
BA_ "GenSigSendType" SG_ 958 MO_BKV_Unterdruckwarnung 0;
BA_ "GenSigSwitchedByIgnition" SG_ 958 MO_Freigabe_Segeln 0;
BA_ "GenSigSendType" SG_ 958 MO_Freigabe_Segeln 0;
BA_ "GenSigSwitchedByIgnition" SG_ 958 MO_PTC_Status 0;
BA_ "GenSigSendType" SG_ 958 MO_PTC_Status 0;
BA_ "GenSigSwitchedByIgnition" SG_ 958 MO_QBit_Gangposition 0;
BA_ "GenSigStartValue" SG_ 958 MO_QBit_Gangposition 1;
BA_ "GenSigSendType" SG_ 958 MO_QBit_Gangposition 3;
BA_ "GenSigEnvVarType" SG_ 958 MO_QBit_Gangposition 0;
BA_ "GenSigAutoGenSnd" SG_ 958 MO_QBit_Gangposition 1;
BA_ "GenSigAutoGenDsp" SG_ 958 MO_QBit_Gangposition 1;
BA_ "GenSigSwitchedByIgnition" SG_ 958 MO_Signalquelle_Gangposition 0;
BA_ "GenSigSendType" SG_ 958 MO_Signalquelle_Gangposition 0;
BA_ "GenSigEnvVarType" SG_ 958 MO_Signalquelle_Gangposition 0;
BA_ "GenSigAutoGenSnd" SG_ 958 MO_Signalquelle_Gangposition 1;
BA_ "GenSigAutoGenDsp" SG_ 958 MO_Signalquelle_Gangposition 1;
BA_ "GenSigSwitchedByIgnition" SG_ 958 MO_Remotestart_Betrieb 0;
BA_ "GenSigSendType" SG_ 958 MO_Remotestart_Betrieb 3;
BA_ "GenSigSwitchedByIgnition" SG_ 1631 TSK_QBit_Steigung 0;
BA_ "GenSigStartValue" SG_ 1631 TSK_QBit_Steigung 1;
BA_ "GenSigSendType" SG_ 1631 TSK_QBit_Steigung 0;
BA_ "GenSigEnvVarType" SG_ 1631 TSK_QBit_Steigung 0;
BA_ "GenSigAutoGenSnd" SG_ 1631 TSK_QBit_Steigung 1;
BA_ "GenSigAutoGenDsp" SG_ 1631 TSK_QBit_Steigung 1;
BA_ "GenSigSwitchedByIgnition" SG_ 1631 TSK_QBit_Fahrzeugmasse 0;
BA_ "GenSigStartValue" SG_ 1631 TSK_QBit_Fahrzeugmasse 1;
BA_ "GenSigSendType" SG_ 1631 TSK_QBit_Fahrzeugmasse 0;
BA_ "GenSigEnvVarType" SG_ 1631 TSK_QBit_Fahrzeugmasse 0;
BA_ "GenSigAutoGenSnd" SG_ 1631 TSK_QBit_Fahrzeugmasse 1;
BA_ "GenSigAutoGenDsp" SG_ 1631 TSK_QBit_Fahrzeugmasse 1;
BA_ "GenSigSwitchedByIgnition" SG_ 1631 MO_SpannungsAnf_02 0;
BA_ "GenSigSendType" SG_ 1631 MO_SpannungsAnf_02 0;
BA_ "GenSigAutoGenSnd" SG_ 1631 MO_SpannungsAnf_02 1;
BA_ "GenSigAutoGenDsp" SG_ 1631 MO_SpannungsAnf_02 1;
BA_ "GenSigSwitchedByIgnition" SG_ 1631 MO_DPF_reg 0;
BA_ "GenSigSendType" SG_ 1631 MO_DPF_reg 0;
BA_ "Fehlerwert" SG_ 1631 MO_Heizstrom_EKAT 127;
BA_ "GenSigSwitchedByIgnition" SG_ 1631 MO_Heizstrom_EKAT 0;
BA_ "GenSigSendType" SG_ 1631 MO_Heizstrom_EKAT 0;
BA_ "Fehlerwert" SG_ 1631 MO_Heizstrom_SCR 63;
BA_ "GenSigSwitchedByIgnition" SG_ 1631 MO_Heizstrom_SCR 0;
BA_ "GenSigSendType" SG_ 1631 MO_Heizstrom_SCR 0;
BA_ "Fehlerwert" SG_ 1631 TSK_Fahrzeugmasse_02 255;
BA_ "GenSigSwitchedByIgnition" SG_ 1631 TSK_Fahrzeugmasse_02 0;
BA_ "GenSigSendType" SG_ 1631 TSK_Fahrzeugmasse_02 0;
BA_ "GenSigEnvVarType" SG_ 1631 TSK_Fahrzeugmasse_02 0;
BA_ "GenSigAutoGenSnd" SG_ 1631 TSK_Fahrzeugmasse_02 1;
BA_ "GenSigAutoGenDsp" SG_ 1631 TSK_Fahrzeugmasse_02 1;
BA_ "Fehlerwert" SG_ 1631 TSK_Steigung 255;
BA_ "GenSigSwitchedByIgnition" SG_ 1631 TSK_Steigung 0;
BA_ "GenSigSendType" SG_ 1631 TSK_Steigung 0;
BA_ "GenSigEnvVarType" SG_ 1631 TSK_Steigung 1;
BA_ "GenSigAutoGenSnd" SG_ 1631 TSK_Steigung 1;
BA_ "GenSigAutoGenDsp" SG_ 1631 TSK_Steigung 1;
BA_REL_ "GenSigTimeoutTime" BU_SG_REL_ Motor_Diesel_MQB SG_ 299 GRA_ACC_01_CRC 500;
BA_REL_ "GenSigTimeoutTime" BU_SG_REL_ Motor_Hybrid_MQB SG_ 299 GRA_ACC_01_CRC 500;
BA_REL_ "GenSigTimeoutTime" BU_SG_REL_ Motor_Otto_MQB SG_ 299 GRA_ACC_01_CRC 500;
BA_REL_ "GenSigTimeoutTime" BU_SG_REL_ Motor_Diesel_MQB SG_ 299 GRA_ACC_01_BZ 500;
BA_REL_ "GenSigTimeoutTime" BU_SG_REL_ Motor_Hybrid_MQB SG_ 299 GRA_ACC_01_BZ 500;
BA_REL_ "GenSigTimeoutTime" BU_SG_REL_ Motor_Otto_MQB SG_ 299 GRA_ACC_01_BZ 500;
BA_REL_ "GenSigTimeoutTime" BU_SG_REL_ Motor_Diesel_MQB SG_ 299 GRA_Hauptschalter 500;
BA_REL_ "GenSigTimeoutTime" BU_SG_REL_ Motor_Hybrid_MQB SG_ 299 GRA_Hauptschalter 500;
BA_REL_ "GenSigTimeoutTime" BU_SG_REL_ Motor_Otto_MQB SG_ 299 GRA_Hauptschalter 500;
BA_REL_ "GenSigTimeoutTime" BU_SG_REL_ Motor_Diesel_MQB SG_ 299 GRA_Abbrechen 500;
BA_REL_ "GenSigTimeoutTime" BU_SG_REL_ Motor_Hybrid_MQB SG_ 299 GRA_Abbrechen 500;
BA_REL_ "GenSigTimeoutTime" BU_SG_REL_ Motor_Otto_MQB SG_ 299 GRA_Abbrechen 500;
BA_REL_ "GenSigTimeoutTime" BU_SG_REL_ Motor_Diesel_MQB SG_ 299 GRA_Typ_Hauptschalter 500;
BA_REL_ "GenSigTimeoutTime" BU_SG_REL_ Motor_Hybrid_MQB SG_ 299 GRA_Typ_Hauptschalter 500;
BA_REL_ "GenSigTimeoutTime" BU_SG_REL_ Motor_Otto_MQB SG_ 299 GRA_Typ_Hauptschalter 500;
BA_REL_ "GenSigTimeoutTime" BU_SG_REL_ Getriebe_DQ_Hybrid_MQB SG_ 299 GRA_Limiter 500;
BA_REL_ "GenSigTimeoutTime" BU_SG_REL_ Getriebe_DQ_MQB SG_ 299 GRA_Limiter 500;
BA_REL_ "GenSigTimeoutTime" BU_SG_REL_ Motor_Diesel_MQB SG_ 299 GRA_Limiter 500;
BA_REL_ "GenSigTimeoutTime" BU_SG_REL_ Motor_Hybrid_MQB SG_ 299 GRA_Limiter 500;
BA_REL_ "GenSigTimeoutTime" BU_SG_REL_ Motor_Otto_MQB SG_ 299 GRA_Limiter 500;
BA_REL_ "GenSigTimeoutTime" BU_SG_REL_ Getriebe_DQ_Hybrid_MQB SG_ 299 GRA_Tip_Setzen 500;
BA_REL_ "GenSigTimeoutTime" BU_SG_REL_ Getriebe_DQ_MQB SG_ 299 GRA_Tip_Setzen 500;
BA_REL_ "GenSigTimeoutTime" BU_SG_REL_ Motor_Diesel_MQB SG_ 299 GRA_Tip_Setzen 500;
BA_REL_ "GenSigTimeoutTime" BU_SG_REL_ Motor_Hybrid_MQB SG_ 299 GRA_Tip_Setzen 500;
BA_REL_ "GenSigTimeoutTime" BU_SG_REL_ Motor_Otto_MQB SG_ 299 GRA_Tip_Setzen 500;
BA_REL_ "GenSigTimeoutTime" BU_SG_REL_ Getriebe_DQ_Hybrid_MQB SG_ 299 GRA_Tip_Hoch 500;
BA_REL_ "GenSigTimeoutTime" BU_SG_REL_ Getriebe_DQ_MQB SG_ 299 GRA_Tip_Hoch 500;
BA_REL_ "GenSigTimeoutTime" BU_SG_REL_ Motor_Diesel_MQB SG_ 299 GRA_Tip_Hoch 500;
BA_REL_ "GenSigTimeoutTime" BU_SG_REL_ Motor_Hybrid_MQB SG_ 299 GRA_Tip_Hoch 500;
BA_REL_ "GenSigTimeoutTime" BU_SG_REL_ Motor_Otto_MQB SG_ 299 GRA_Tip_Hoch 500;
BA_REL_ "GenSigTimeoutTime" BU_SG_REL_ Getriebe_DQ_Hybrid_MQB SG_ 299 GRA_Tip_Runter 500;
BA_REL_ "GenSigTimeoutTime" BU_SG_REL_ Getriebe_DQ_MQB SG_ 299 GRA_Tip_Runter 500;
BA_REL_ "GenSigTimeoutTime" BU_SG_REL_ Motor_Diesel_MQB SG_ 299 GRA_Tip_Runter 500;
BA_REL_ "GenSigTimeoutTime" BU_SG_REL_ Motor_Hybrid_MQB SG_ 299 GRA_Tip_Runter 500;
BA_REL_ "GenSigTimeoutTime" BU_SG_REL_ Motor_Otto_MQB SG_ 299 GRA_Tip_Runter 500;
BA_REL_ "GenSigTimeoutTime" BU_SG_REL_ Getriebe_DQ_Hybrid_MQB SG_ 299 GRA_Tip_Wiederaufnahme 500;
BA_REL_ "GenSigTimeoutTime" BU_SG_REL_ Getriebe_DQ_MQB SG_ 299 GRA_Tip_Wiederaufnahme 500;
BA_REL_ "GenSigTimeoutTime" BU_SG_REL_ Motor_Diesel_MQB SG_ 299 GRA_Tip_Wiederaufnahme 500;
BA_REL_ "GenSigTimeoutTime" BU_SG_REL_ Motor_Hybrid_MQB SG_ 299 GRA_Tip_Wiederaufnahme 500;
BA_REL_ "GenSigTimeoutTime" BU_SG_REL_ Motor_Otto_MQB SG_ 299 GRA_Tip_Wiederaufnahme 500;
BA_REL_ "GenSigTimeoutTime" BU_SG_REL_ Motor_Diesel_MQB SG_ 299 GRA_Verstellung_Zeitluecke 500;
BA_REL_ "GenSigTimeoutTime" BU_SG_REL_ Motor_Hybrid_MQB SG_ 299 GRA_Verstellung_Zeitluecke 500;
BA_REL_ "GenSigTimeoutTime" BU_SG_REL_ Motor_Otto_MQB SG_ 299 GRA_Verstellung_Zeitluecke 500;
BA_REL_ "GenSigTimeoutTime" BU_SG_REL_ Motor_Diesel_MQB SG_ 299 GRA_Codierung 500;
BA_REL_ "GenSigTimeoutTime" BU_SG_REL_ Motor_Hybrid_MQB SG_ 299 GRA_Codierung 500;
BA_REL_ "GenSigTimeoutTime" BU_SG_REL_ Motor_Otto_MQB SG_ 299 GRA_Codierung 500;
BA_REL_ "GenSigTimeoutTime" BU_SG_REL_ Getriebe_DQ_Hybrid_MQB SG_ 299 GRA_Fehler 500;
BA_REL_ "GenSigTimeoutTime" BU_SG_REL_ Getriebe_DQ_MQB SG_ 299 GRA_Fehler 500;
BA_REL_ "GenSigTimeoutTime" BU_SG_REL_ Motor_Diesel_MQB SG_ 299 GRA_Fehler 500;
BA_REL_ "GenSigTimeoutTime" BU_SG_REL_ Motor_Hybrid_MQB SG_ 299 GRA_Fehler 500;
BA_REL_ "GenSigTimeoutTime" BU_SG_REL_ Motor_Otto_MQB SG_ 299 GRA_Fehler 500;
BA_REL_ "GenSigTimeoutTime" BU_SG_REL_ Motor_Diesel_MQB SG_ 299 GRA_Typ468 500;
BA_REL_ "GenSigTimeoutTime" BU_SG_REL_ Motor_Hybrid_MQB SG_ 299 GRA_Typ468 500;
BA_REL_ "GenSigTimeoutTime" BU_SG_REL_ Motor_Otto_MQB SG_ 299 GRA_Typ468 500;
BA_REL_ "GenSigTimeoutTime" BU_SG_REL_ Motor_Diesel_MQB SG_ 299 GRA_Tip_Stufe_2 500;
BA_REL_ "GenSigTimeoutTime" BU_SG_REL_ Motor_Hybrid_MQB SG_ 299 GRA_Tip_Stufe_2 500;
BA_REL_ "GenSigTimeoutTime" BU_SG_REL_ Motor_Otto_MQB SG_ 299 GRA_Tip_Stufe_2 500;
BA_REL_ "GenSigTimeoutTime" BU_SG_REL_ Airbag_MQB SG_ 960 Klemmen_Status_01_CRC 1000;
BA_REL_ "GenSigTimeoutTime" BU_SG_REL_ BMS_MQB SG_ 960 Klemmen_Status_01_CRC 1000;
BA_REL_ "GenSigTimeoutTime" BU_SG_REL_ Motor_Diesel_MQB SG_ 960 Klemmen_Status_01_CRC 1000;
BA_REL_ "GenSigTimeoutTime" BU_SG_REL_ Motor_Hybrid_MQB SG_ 960 Klemmen_Status_01_CRC 1000;
BA_REL_ "GenSigTimeoutTime" BU_SG_REL_ Motor_Otto_MQB SG_ 960 Klemmen_Status_01_CRC 1000;
BA_REL_ "GenSigTimeoutTime" BU_SG_REL_ Airbag_MQB SG_ 960 Klemmen_Status_01_BZ 1000;
BA_REL_ "GenSigTimeoutTime" BU_SG_REL_ BMS_MQB SG_ 960 Klemmen_Status_01_BZ 1000;
BA_REL_ "GenSigTimeoutTime" BU_SG_REL_ Motor_Diesel_MQB SG_ 960 Klemmen_Status_01_BZ 1000;
BA_REL_ "GenSigTimeoutTime" BU_SG_REL_ Motor_Hybrid_MQB SG_ 960 Klemmen_Status_01_BZ 1000;
BA_REL_ "GenSigTimeoutTime" BU_SG_REL_ Motor_Otto_MQB SG_ 960 Klemmen_Status_01_BZ 1000;
BA_REL_ "GenSigTimeoutTime" BU_SG_REL_ Airbag_MQB SG_ 960 ZAS_Kl_15 1000;
BA_REL_ "GenSigTimeoutTime" BU_SG_REL_ BMS_MQB SG_ 960 ZAS_Kl_15 1000;
BA_REL_ "GenSigTimeoutTime" BU_SG_REL_ Motor_Diesel_MQB SG_ 960 ZAS_Kl_15 1000;
BA_REL_ "GenSigTimeoutTime" BU_SG_REL_ Motor_Hybrid_MQB SG_ 960 ZAS_Kl_15 1000;
BA_REL_ "GenSigTimeoutTime" BU_SG_REL_ Motor_Otto_MQB SG_ 960 ZAS_Kl_15 1000;
BA_REL_ "GenSigTimeoutTime" BU_SG_REL_ Motor_Diesel_MQB SG_ 949 KL_Drehz_Anh 1000;
BA_REL_ "GenSigTimeoutTime" BU_SG_REL_ Motor_Hybrid_MQB SG_ 949 KL_Drehz_Anh 1000;
BA_REL_ "GenSigTimeoutTime" BU_SG_REL_ Motor_Otto_MQB SG_ 949 KL_Drehz_Anh 1000;
BA_REL_ "GenSigTimeoutTime" BU_SG_REL_ Motor_Diesel_MQB SG_ 949 KL_Vorwarn_Komp_ein 1000;
BA_REL_ "GenSigTimeoutTime" BU_SG_REL_ Motor_Hybrid_MQB SG_ 949 KL_Vorwarn_Komp_ein 1000;
BA_REL_ "GenSigTimeoutTime" BU_SG_REL_ Motor_Otto_MQB SG_ 949 KL_Vorwarn_Komp_ein 1000;
BA_REL_ "GenSigTimeoutTime" BU_SG_REL_ Motor_Diesel_MQB SG_ 949 KL_Zonen 1000;
BA_REL_ "GenSigTimeoutTime" BU_SG_REL_ Motor_Hybrid_MQB SG_ 949 KL_Zonen 1000;
BA_REL_ "GenSigTimeoutTime" BU_SG_REL_ Motor_Otto_MQB SG_ 949 KL_Zonen 1000;
BA_REL_ "GenSigTimeoutTime" BU_SG_REL_ Motor_Diesel_MQB SG_ 949 KL_Zustand 1000;
BA_REL_ "GenSigTimeoutTime" BU_SG_REL_ Motor_Hybrid_MQB SG_ 949 KL_Zustand 1000;
BA_REL_ "GenSigTimeoutTime" BU_SG_REL_ Motor_Otto_MQB SG_ 949 KL_Zustand 1000;
BA_REL_ "GenSigTimeoutTime" BU_SG_REL_ Motor_Diesel_MQB SG_ 949 KL_Last_Kompr 1000;
BA_REL_ "GenSigTimeoutTime" BU_SG_REL_ Motor_Hybrid_MQB SG_ 949 KL_Last_Kompr 1000;
BA_REL_ "GenSigTimeoutTime" BU_SG_REL_ Motor_Otto_MQB SG_ 949 KL_Last_Kompr 1000;
BA_REL_ "GenSigTimeoutTime" BU_SG_REL_ Motor_Diesel_MQB SG_ 949 KL_Thermomanagement 1000;
BA_REL_ "GenSigTimeoutTime" BU_SG_REL_ Motor_Hybrid_MQB SG_ 949 KL_Thermomanagement 1000;
BA_REL_ "GenSigTimeoutTime" BU_SG_REL_ Motor_Otto_MQB SG_ 949 KL_Thermomanagement 1000;
BA_REL_ "GenSigTimeoutTime" BU_SG_REL_ Motor_Diesel_MQB SG_ 949 KL_StartStopp_Info 1000;
BA_REL_ "GenSigTimeoutTime" BU_SG_REL_ Motor_Otto_MQB SG_ 949 KL_StartStopp_Info 1000;
BA_REL_ "GenSigTimeoutTime" BU_SG_REL_ Motor_Diesel_MQB SG_ 949 KL_Anf_KL 1000;
BA_REL_ "GenSigTimeoutTime" BU_SG_REL_ Motor_Hybrid_MQB SG_ 949 KL_Anf_KL 1000;
BA_REL_ "GenSigTimeoutTime" BU_SG_REL_ Motor_Otto_MQB SG_ 949 KL_Anf_KL 1000;
BA_REL_ "GenSigTimeoutTime" BU_SG_REL_ Motor_Diesel_MQB SG_ 949 KL_el_Zuheizer_Stufe 1000;
BA_REL_ "GenSigTimeoutTime" BU_SG_REL_ Motor_Hybrid_MQB SG_ 1625 EKL_Comp_current 5000;
BA_REL_ "GenSigTimeoutTime" BU_SG_REL_ Gateway_MQB SG_ 2549088277 Airbag_01_Nachlauftyp 5000;
BA_REL_ "GenSigTimeoutTime" BU_SG_REL_ Gateway_MQB SG_ 2549088277 AB_KD_Fehler 5000;
BA_REL_ "GenSigTimeoutTime" BU_SG_REL_ Gateway_MQB SG_ 2549088380 EMotor_Nachlauftyp 5000;
BA_REL_ "GenSigTimeoutTime" BU_SG_REL_ Gateway_MQB SG_ 2549088380 EM_HYB_KD_Fehler 5000;
BA_REL_ "GenSigTimeoutTime" BU_SG_REL_ Gateway_MQB SG_ 2549088375 Getriebe_Nachlauftyp 5000;
BA_REL_ "GenSigTimeoutTime" BU_SG_REL_ Gateway_MQB SG_ 2549088375 GE_KD_Fehler 5000;
BA_REL_ "GenSigTimeoutTime" BU_SG_REL_ Gateway_MQB SG_ 2549088379 Hybrid_Nachlauftyp 5000;
BA_REL_ "GenSigTimeoutTime" BU_SG_REL_ Gateway_MQB SG_ 2549088379 BMS_HYB_KD_Fehler 5000;
BA_REL_ "GenSigTimeoutTime" BU_SG_REL_ Gateway_MQB SG_ 2549088374 Motor_Nachlauftyp 5000;
BA_REL_ "GenSigTimeoutTime" BU_SG_REL_ Gateway_MQB SG_ 2549088374 MO_KD_Fehler 5000;
BA_REL_ "GenSigTimeoutTime" BU_SG_REL_ Gateway_MQB SG_ 2549088284 SAK_Nachlauftyp 5000;
BA_REL_ "GenSigTimeoutTime" BU_SG_REL_ Gateway_MQB SG_ 2549088284 SAK_KD_Fehler 5000;
BA_REL_ "GenSigTimeoutTime" BU_SG_REL_ Airbag_MQB SG_ 779 KBI_Airbag_Lampe 500;
BA_REL_ "GenSigTimeoutTime" BU_SG_REL_ Airbag_MQB SG_ 779 KBI_SILA_gueltig 500;
BA_REL_ "GenSigTimeoutTime" BU_SG_REL_ Motor_Diesel_MQB SG_ 779 KBI_Vorglueh_System_Lampe 500;
BA_REL_ "GenSigTimeoutTime" BU_SG_REL_ Motor_Diesel_MQB SG_ 779 Kombi_01_BZ 500;
BA_REL_ "GenSigTimeoutTime" BU_SG_REL_ Motor_Hybrid_MQB SG_ 779 Kombi_01_BZ 500;
BA_REL_ "GenSigTimeoutTime" BU_SG_REL_ Motor_Otto_MQB SG_ 779 Kombi_01_BZ 500;
BA_REL_ "GenSigTimeoutTime" BU_SG_REL_ Motor_Diesel_MQB SG_ 779 KBI_Anzeigestatus_GRA 500;
BA_REL_ "GenSigTimeoutTime" BU_SG_REL_ Motor_Hybrid_MQB SG_ 779 KBI_Anzeigestatus_GRA 500;
BA_REL_ "GenSigTimeoutTime" BU_SG_REL_ Motor_Otto_MQB SG_ 779 KBI_Anzeigestatus_GRA 500;
BA_REL_ "GenSigTimeoutTime" BU_SG_REL_ Motor_Diesel_MQB SG_ 779 KBI_Tankwarnung 500;
BA_REL_ "GenSigTimeoutTime" BU_SG_REL_ Motor_Diesel_MQB SG_ 779 KBI_Tankwarnung 500;
BA_REL_ "GenSigTimeoutTime" BU_SG_REL_ Motor_Hybrid_MQB SG_ 779 KBI_Tankwarnung 500;
BA_REL_ "GenSigTimeoutTime" BU_SG_REL_ Motor_Otto_MQB SG_ 779 KBI_Tankwarnung 500;
BA_REL_ "GenSigTimeoutTime" BU_SG_REL_ Motor_Otto_MQB SG_ 779 KBI_Tankwarnung 500;
BA_REL_ "GenSigTimeoutTime" BU_SG_REL_ Motor_Diesel_MQB SG_ 779 KBI_MFA_v_Einheit_01 500;
BA_REL_ "GenSigTimeoutTime" BU_SG_REL_ Motor_Hybrid_MQB SG_ 779 KBI_MFA_v_Einheit_01 500;
BA_REL_ "GenSigTimeoutTime" BU_SG_REL_ Motor_Otto_MQB SG_ 779 KBI_MFA_v_Einheit_01 500;
BA_REL_ "GenSigTimeoutTime" BU_SG_REL_ Airbag_MQB SG_ 779 KBI_im_Stellgliedtest 500;
BA_REL_ "GenSigTimeoutTime" BU_SG_REL_ Getriebe_DQ_Hybrid_MQB SG_ 779 KBI_Handbremse 500;
BA_REL_ "GenSigTimeoutTime" BU_SG_REL_ Getriebe_DQ_MQB SG_ 779 KBI_Handbremse 500;
BA_REL_ "GenSigTimeoutTime" BU_SG_REL_ Motor_Diesel_MQB SG_ 779 KBI_Anzeigestatus_LIM 500;
BA_REL_ "GenSigTimeoutTime" BU_SG_REL_ Motor_Hybrid_MQB SG_ 779 KBI_Anzeigestatus_LIM 500;
BA_REL_ "GenSigTimeoutTime" BU_SG_REL_ Motor_Otto_MQB SG_ 779 KBI_Anzeigestatus_LIM 500;
BA_REL_ "GenSigTimeoutTime" BU_SG_REL_ Getriebe_DQ_Hybrid_MQB SG_ 779 KBI_angez_Geschw 500;
BA_REL_ "GenSigTimeoutTime" BU_SG_REL_ Getriebe_DQ_MQB SG_ 779 KBI_angez_Geschw 500;
BA_REL_ "GenSigTimeoutTime" BU_SG_REL_ Motor_Diesel_MQB SG_ 779 KBI_angez_Geschw 500;
BA_REL_ "GenSigTimeoutTime" BU_SG_REL_ Motor_Hybrid_MQB SG_ 779 KBI_angez_Geschw 500;
BA_REL_ "GenSigTimeoutTime" BU_SG_REL_ Motor_Otto_MQB SG_ 779 KBI_angez_Geschw 500;
BA_REL_ "GenSigTimeoutTime" BU_SG_REL_ Motor_Diesel_MQB SG_ 779 KBI_Einheit_Tacho 500;
BA_REL_ "GenSigTimeoutTime" BU_SG_REL_ Motor_Diesel_MQB SG_ 779 KBI_Einheit_Tacho 500;
BA_REL_ "GenSigTimeoutTime" BU_SG_REL_ Motor_Hybrid_MQB SG_ 779 KBI_Einheit_Tacho 500;
BA_REL_ "GenSigTimeoutTime" BU_SG_REL_ Motor_Hybrid_MQB SG_ 779 KBI_Einheit_Tacho 500;
BA_REL_ "GenSigTimeoutTime" BU_SG_REL_ Motor_Otto_MQB SG_ 779 KBI_Einheit_Tacho 500;
BA_REL_ "GenSigTimeoutTime" BU_SG_REL_ Motor_Otto_MQB SG_ 779 KBI_Einheit_Tacho 500;
BA_REL_ "GenSigTimeoutTime" BU_SG_REL_ Getriebe_DQ_Hybrid_MQB SG_ 1719 KBI_Standzeit_02 5000;
BA_REL_ "GenSigTimeoutTime" BU_SG_REL_ Getriebe_DQ_MQB SG_ 1719 KBI_Standzeit_02 5000;
BA_REL_ "GenSigTimeoutTime" BU_SG_REL_ Motor_Diesel_MQB SG_ 1719 KBI_Standzeit_02 5000;
BA_REL_ "GenSigTimeoutTime" BU_SG_REL_ Motor_Hybrid_MQB SG_ 1719 KBI_Standzeit_02 5000;
BA_REL_ "GenSigTimeoutTime" BU_SG_REL_ Motor_Otto_MQB SG_ 1719 KBI_Standzeit_02 5000;
BA_REL_ "GenSigTimeoutTime" BU_SG_REL_ Motor_Diesel_MQB SG_ 1719 KBI_Inhalt_Tank 5000;
BA_REL_ "GenSigTimeoutTime" BU_SG_REL_ Motor_Hybrid_MQB SG_ 1719 KBI_Inhalt_Tank 5000;
BA_REL_ "GenSigTimeoutTime" BU_SG_REL_ Motor_Otto_MQB SG_ 1719 KBI_Inhalt_Tank 5000;
BA_REL_ "GenSigTimeoutTime" BU_SG_REL_ Motor_Diesel_MQB SG_ 1719 KBI_FStatus_Tank 5000;
BA_REL_ "GenSigTimeoutTime" BU_SG_REL_ Motor_Hybrid_MQB SG_ 1719 KBI_FStatus_Tank 5000;
BA_REL_ "GenSigTimeoutTime" BU_SG_REL_ Motor_Otto_MQB SG_ 1719 KBI_FStatus_Tank 5000;
BA_REL_ "GenSigTimeoutTime" BU_SG_REL_ Getriebe_DQ_Hybrid_MQB SG_ 1719 KBI_QBit_Aussen_Temp_gef 5000;
BA_REL_ "GenSigTimeoutTime" BU_SG_REL_ Getriebe_DQ_MQB SG_ 1719 KBI_QBit_Aussen_Temp_gef 5000;
BA_REL_ "GenSigTimeoutTime" BU_SG_REL_ Motor_Diesel_MQB SG_ 1719 KBI_QBit_Aussen_Temp_gef 5000;
BA_REL_ "GenSigTimeoutTime" BU_SG_REL_ Motor_Hybrid_MQB SG_ 1719 KBI_QBit_Aussen_Temp_gef 5000;
BA_REL_ "GenSigTimeoutTime" BU_SG_REL_ Motor_Otto_MQB SG_ 1719 KBI_QBit_Aussen_Temp_gef 5000;
BA_REL_ "GenSigTimeoutTime" BU_SG_REL_ Getriebe_DQ_Hybrid_MQB SG_ 1719 KBI_Aussen_Temp_gef 5000;
BA_REL_ "GenSigTimeoutTime" BU_SG_REL_ Getriebe_DQ_MQB SG_ 1719 KBI_Aussen_Temp_gef 5000;
BA_REL_ "GenSigTimeoutTime" BU_SG_REL_ Motor_Diesel_MQB SG_ 1719 KBI_Aussen_Temp_gef 5000;
BA_REL_ "GenSigTimeoutTime" BU_SG_REL_ Motor_Hybrid_MQB SG_ 1719 KBI_Aussen_Temp_gef 5000;
BA_REL_ "GenSigTimeoutTime" BU_SG_REL_ Motor_Otto_MQB SG_ 1719 KBI_Aussen_Temp_gef 5000;
BA_REL_ "GenSigTimeoutTime" BU_SG_REL_ Motor_Diesel_MQB SG_ 982 Licht_hinten_01_BZ 1000;
BA_REL_ "GenSigTimeoutTime" BU_SG_REL_ Motor_Hybrid_MQB SG_ 982 Licht_hinten_01_BZ 1000;
BA_REL_ "GenSigTimeoutTime" BU_SG_REL_ Motor_Otto_MQB SG_ 982 Licht_hinten_01_BZ 1000;
BA_REL_ "GenSigTimeoutTime" BU_SG_REL_ Motor_Diesel_MQB SG_ 982 BCM2_Bremsl_durch_ECD 1000;
BA_REL_ "GenSigTimeoutTime" BU_SG_REL_ Motor_Hybrid_MQB SG_ 982 BCM2_Bremsl_durch_ECD 1000;
BA_REL_ "GenSigTimeoutTime" BU_SG_REL_ Motor_Otto_MQB SG_ 982 BCM2_Bremsl_durch_ECD 1000;
BA_REL_ "GenSigTimeoutTime" BU_SG_REL_ Motor_Diesel_MQB SG_ 982 LH_3_Bremsl_def 1000;
BA_REL_ "GenSigTimeoutTime" BU_SG_REL_ Motor_Hybrid_MQB SG_ 982 LH_3_Bremsl_def 1000;
BA_REL_ "GenSigTimeoutTime" BU_SG_REL_ Motor_Otto_MQB SG_ 982 LH_3_Bremsl_def 1000;
BA_REL_ "GenSigTimeoutTime" BU_SG_REL_ Motor_Diesel_MQB SG_ 982 LH_Bremsl_li_ges_def 1000;
BA_REL_ "GenSigTimeoutTime" BU_SG_REL_ Motor_Hybrid_MQB SG_ 982 LH_Bremsl_li_ges_def 1000;
BA_REL_ "GenSigTimeoutTime" BU_SG_REL_ Motor_Otto_MQB SG_ 982 LH_Bremsl_li_ges_def 1000;
BA_REL_ "GenSigTimeoutTime" BU_SG_REL_ Motor_Diesel_MQB SG_ 982 LH_Bremsl_re_ges_def 1000;
BA_REL_ "GenSigTimeoutTime" BU_SG_REL_ Motor_Hybrid_MQB SG_ 982 LH_Bremsl_re_ges_def 1000;
BA_REL_ "GenSigTimeoutTime" BU_SG_REL_ Motor_Otto_MQB SG_ 982 LH_Bremsl_re_ges_def 1000;
BA_REL_ "GenSigTimeoutTime" BU_SG_REL_ Airbag_MQB SG_ 134 LWI_01_CRC 500;
BA_REL_ "GenSigTimeoutTime" BU_SG_REL_ Getriebe_DQ_Hybrid_MQB SG_ 134 LWI_01_CRC 500;
BA_REL_ "GenSigTimeoutTime" BU_SG_REL_ Getriebe_DQ_MQB SG_ 134 LWI_01_CRC 500;
BA_REL_ "GenSigTimeoutTime" BU_SG_REL_ Motor_Diesel_MQB SG_ 134 LWI_01_CRC 500;
BA_REL_ "GenSigTimeoutTime" BU_SG_REL_ Motor_Hybrid_MQB SG_ 134 LWI_01_CRC 500;
BA_REL_ "GenSigTimeoutTime" BU_SG_REL_ Motor_Otto_MQB SG_ 134 LWI_01_CRC 500;
BA_REL_ "GenSigTimeoutTime" BU_SG_REL_ Airbag_MQB SG_ 134 LWI_01_BZ 500;
BA_REL_ "GenSigTimeoutTime" BU_SG_REL_ Getriebe_DQ_Hybrid_MQB SG_ 134 LWI_01_BZ 500;
BA_REL_ "GenSigTimeoutTime" BU_SG_REL_ Getriebe_DQ_MQB SG_ 134 LWI_01_BZ 500;
BA_REL_ "GenSigTimeoutTime" BU_SG_REL_ Motor_Diesel_MQB SG_ 134 LWI_01_BZ 500;
BA_REL_ "GenSigTimeoutTime" BU_SG_REL_ Motor_Hybrid_MQB SG_ 134 LWI_01_BZ 500;
BA_REL_ "GenSigTimeoutTime" BU_SG_REL_ Motor_Otto_MQB SG_ 134 LWI_01_BZ 500;
BA_REL_ "GenSigTimeoutTime" BU_SG_REL_ Airbag_MQB SG_ 134 LWI_Sensorstatus 500;
BA_REL_ "GenSigTimeoutTime" BU_SG_REL_ Getriebe_DQ_Hybrid_MQB SG_ 134 LWI_Sensorstatus 500;
BA_REL_ "GenSigTimeoutTime" BU_SG_REL_ Getriebe_DQ_MQB SG_ 134 LWI_Sensorstatus 500;
BA_REL_ "GenSigTimeoutTime" BU_SG_REL_ Motor_Diesel_MQB SG_ 134 LWI_Sensorstatus 500;
BA_REL_ "GenSigTimeoutTime" BU_SG_REL_ Motor_Hybrid_MQB SG_ 134 LWI_Sensorstatus 500;
BA_REL_ "GenSigTimeoutTime" BU_SG_REL_ Motor_Otto_MQB SG_ 134 LWI_Sensorstatus 500;
BA_REL_ "GenSigTimeoutTime" BU_SG_REL_ Airbag_MQB SG_ 134 LWI_QBit_Lenkradwinkel 500;
BA_REL_ "GenSigTimeoutTime" BU_SG_REL_ Getriebe_DQ_Hybrid_MQB SG_ 134 LWI_QBit_Lenkradwinkel 500;
BA_REL_ "GenSigTimeoutTime" BU_SG_REL_ Getriebe_DQ_MQB SG_ 134 LWI_QBit_Lenkradwinkel 500;
BA_REL_ "GenSigTimeoutTime" BU_SG_REL_ Motor_Diesel_MQB SG_ 134 LWI_QBit_Lenkradwinkel 500;
BA_REL_ "GenSigTimeoutTime" BU_SG_REL_ Motor_Hybrid_MQB SG_ 134 LWI_QBit_Lenkradwinkel 500;
BA_REL_ "GenSigTimeoutTime" BU_SG_REL_ Motor_Otto_MQB SG_ 134 LWI_QBit_Lenkradwinkel 500;
BA_REL_ "GenSigTimeoutTime" BU_SG_REL_ Airbag_MQB SG_ 134 LWI_Lenkradwinkel 500;
BA_REL_ "GenSigTimeoutTime" BU_SG_REL_ Getriebe_DQ_Hybrid_MQB SG_ 134 LWI_Lenkradwinkel 500;
BA_REL_ "GenSigTimeoutTime" BU_SG_REL_ Getriebe_DQ_MQB SG_ 134 LWI_Lenkradwinkel 500;
BA_REL_ "GenSigTimeoutTime" BU_SG_REL_ Motor_Diesel_MQB SG_ 134 LWI_Lenkradwinkel 500;
BA_REL_ "GenSigTimeoutTime" BU_SG_REL_ Motor_Hybrid_MQB SG_ 134 LWI_Lenkradwinkel 500;
BA_REL_ "GenSigTimeoutTime" BU_SG_REL_ Motor_Otto_MQB SG_ 134 LWI_Lenkradwinkel 500;
BA_REL_ "GenSigTimeoutTime" BU_SG_REL_ Airbag_MQB SG_ 134 LWI_VZ_Lenkradwinkel 500;
BA_REL_ "GenSigTimeoutTime" BU_SG_REL_ Getriebe_DQ_Hybrid_MQB SG_ 134 LWI_VZ_Lenkradwinkel 500;
BA_REL_ "GenSigTimeoutTime" BU_SG_REL_ Getriebe_DQ_MQB SG_ 134 LWI_VZ_Lenkradwinkel 500;
BA_REL_ "GenSigTimeoutTime" BU_SG_REL_ Motor_Diesel_MQB SG_ 134 LWI_VZ_Lenkradwinkel 500;
BA_REL_ "GenSigTimeoutTime" BU_SG_REL_ Motor_Hybrid_MQB SG_ 134 LWI_VZ_Lenkradwinkel 500;
BA_REL_ "GenSigTimeoutTime" BU_SG_REL_ Motor_Otto_MQB SG_ 134 LWI_VZ_Lenkradwinkel 500;
BA_REL_ "GenSigTimeoutTime" BU_SG_REL_ Gateway_MQB SG_ 263 MO_Istgang 500;
BA_REL_ "GenSigTimeoutTime" BU_SG_REL_ Gateway_MQB SG_ 263 MO_Sollgang 500;
BA_REL_ "GenSigTimeoutTime" BU_SG_REL_ Getriebe_DQ_Hybrid_MQB SG_ 1600 MO_QBit_Oel_Temp 5000;
BA_REL_ "GenSigTimeoutTime" BU_SG_REL_ Getriebe_DQ_MQB SG_ 1600 MO_QBit_Oel_Temp 5000;
BA_REL_ "GenSigTimeoutTime" BU_SG_REL_ Getriebe_DQ_Hybrid_MQB SG_ 1600 MO_QBit_Kuehlmittel_Temp 5000;
BA_REL_ "GenSigTimeoutTime" BU_SG_REL_ Getriebe_DQ_MQB SG_ 1600 MO_QBit_Kuehlmittel_Temp 5000;
BA_REL_ "GenSigTimeoutTime" BU_SG_REL_ LEH_MQB SG_ 1600 MO_QBit_Kuehlmittel_Temp 5000;
BA_REL_ "GenSigTimeoutTime" BU_SG_REL_ Getriebe_DQ_Hybrid_MQB SG_ 1600 MO_aktives_Getriebeheizen 5000;
BA_REL_ "GenSigTimeoutTime" BU_SG_REL_ Getriebe_DQ_MQB SG_ 1600 MO_aktives_Getriebeheizen 5000;
BA_REL_ "GenSigTimeoutTime" BU_SG_REL_ Getriebe_DQ_Hybrid_MQB SG_ 1600 MO_Oel_Temp 5000;
BA_REL_ "GenSigTimeoutTime" BU_SG_REL_ Getriebe_DQ_MQB SG_ 1600 MO_Oel_Temp 5000;
BA_REL_ "GenSigTimeoutTime" BU_SG_REL_ Gateway_MQB SG_ 1600 MO_Kuehlmittel_Temp 5000;
BA_REL_ "GenSigTimeoutTime" BU_SG_REL_ Gateway_MQB SG_ 1600 MO_Kuehlmittel_Temp 5000;
BA_REL_ "GenSigTimeoutTime" BU_SG_REL_ Getriebe_DQ_Hybrid_MQB SG_ 1600 MO_Kuehlmittel_Temp 5000;
BA_REL_ "GenSigTimeoutTime" BU_SG_REL_ Getriebe_DQ_MQB SG_ 1600 MO_Kuehlmittel_Temp 5000;
BA_REL_ "GenSigTimeoutTime" BU_SG_REL_ LEH_MQB SG_ 1600 MO_Kuehlmittel_Temp 5000;
BA_REL_ "GenSigTimeoutTime" BU_SG_REL_ Getriebe_DQ_Hybrid_MQB SG_ 1600 MO_Hoeheninfo 5000;
BA_REL_ "GenSigTimeoutTime" BU_SG_REL_ Getriebe_DQ_MQB SG_ 1600 MO_Hoeheninfo 5000;
BA_REL_ "GenSigTimeoutTime" BU_SG_REL_ Getriebe_DQ_Hybrid_MQB SG_ 1600 MO_Getriebe_kuehlen 5000;
BA_REL_ "GenSigTimeoutTime" BU_SG_REL_ Getriebe_DQ_MQB SG_ 1600 MO_Getriebe_kuehlen 5000;
BA_REL_ "GenSigTimeoutTime" BU_SG_REL_ Getriebe_DQ_Hybrid_MQB SG_ 1600 MO_Mom_Traegheit_02 5000;
BA_REL_ "GenSigTimeoutTime" BU_SG_REL_ Getriebe_DQ_MQB SG_ 1600 MO_Mom_Traegheit_02 5000;
BA_REL_ "GenSigTimeoutTime" BU_SG_REL_ Getriebe_DQ_Hybrid_MQB SG_ 1607 MO_ITM_Kuehlmittel_Temp 5000;
BA_REL_ "GenSigTimeoutTime" BU_SG_REL_ Getriebe_DQ_MQB SG_ 1607 MO_ITM_Kuehlmittel_Temp 5000;
BA_REL_ "GenSigTimeoutTime" BU_SG_REL_ Getriebe_DQ_Hybrid_MQB SG_ 167 Motor_11_CRC 500;
BA_REL_ "GenSigTimeoutTime" BU_SG_REL_ Getriebe_DQ_MQB SG_ 167 Motor_11_CRC 500;
BA_REL_ "GenSigTimeoutTime" BU_SG_REL_ Getriebe_DQ_Hybrid_MQB SG_ 167 Motor_11_BZ 500;
BA_REL_ "GenSigTimeoutTime" BU_SG_REL_ Getriebe_DQ_MQB SG_ 167 Motor_11_BZ 500;
BA_REL_ "GenSigTimeoutTime" BU_SG_REL_ Getriebe_DQ_Hybrid_MQB SG_ 167 MO_Mom_Soll_Roh 500;
BA_REL_ "GenSigTimeoutTime" BU_SG_REL_ Getriebe_DQ_MQB SG_ 167 MO_Mom_Soll_Roh 500;
BA_REL_ "GenSigTimeoutTime" BU_SG_REL_ Getriebe_DQ_Hybrid_MQB SG_ 167 MO_Mom_Ist_Summe 500;
BA_REL_ "GenSigTimeoutTime" BU_SG_REL_ Getriebe_DQ_MQB SG_ 167 MO_Mom_Ist_Summe 500;
BA_REL_ "GenSigTimeoutTime" BU_SG_REL_ SAK_MQB SG_ 167 MO_Mom_Ist_Summe 500;
BA_REL_ "GenSigTimeoutTime" BU_SG_REL_ Getriebe_DQ_Hybrid_MQB SG_ 167 MO_Mom_Traegheit_Summe 500;
BA_REL_ "GenSigTimeoutTime" BU_SG_REL_ Getriebe_DQ_MQB SG_ 167 MO_Mom_Traegheit_Summe 500;
BA_REL_ "GenSigTimeoutTime" BU_SG_REL_ Getriebe_DQ_Hybrid_MQB SG_ 167 MO_Mom_Soll_gefiltert 500;
BA_REL_ "GenSigTimeoutTime" BU_SG_REL_ Getriebe_DQ_MQB SG_ 167 MO_Mom_Soll_gefiltert 500;
BA_REL_ "GenSigTimeoutTime" BU_SG_REL_ Getriebe_DQ_Hybrid_MQB SG_ 167 MO_Mom_Schub 500;
BA_REL_ "GenSigTimeoutTime" BU_SG_REL_ Getriebe_DQ_MQB SG_ 167 MO_Mom_Schub 500;
BA_REL_ "GenSigTimeoutTime" BU_SG_REL_ Getriebe_DQ_Hybrid_MQB SG_ 167 MO_Status_Normalbetrieb_01 500;
BA_REL_ "GenSigTimeoutTime" BU_SG_REL_ Getriebe_DQ_MQB SG_ 167 MO_Status_Normalbetrieb_01 500;
BA_REL_ "GenSigTimeoutTime" BU_SG_REL_ Getriebe_DQ_Hybrid_MQB SG_ 167 MO_QBit_Motormomente 500;
BA_REL_ "GenSigTimeoutTime" BU_SG_REL_ Getriebe_DQ_MQB SG_ 167 MO_QBit_Motormomente 500;
BA_REL_ "GenSigTimeoutTime" BU_SG_REL_ Getriebe_DQ_Hybrid_MQB SG_ 168 Motor_12_CRC 500;
BA_REL_ "GenSigTimeoutTime" BU_SG_REL_ Getriebe_DQ_MQB SG_ 168 Motor_12_CRC 500;
BA_REL_ "GenSigTimeoutTime" BU_SG_REL_ LEH_MQB SG_ 168 Motor_12_CRC 500;
BA_REL_ "GenSigTimeoutTime" BU_SG_REL_ BMS_MQB SG_ 168 Motor_12_BZ 500;
BA_REL_ "GenSigTimeoutTime" BU_SG_REL_ Getriebe_DQ_Hybrid_MQB SG_ 168 Motor_12_BZ 500;
BA_REL_ "GenSigTimeoutTime" BU_SG_REL_ Getriebe_DQ_MQB SG_ 168 Motor_12_BZ 500;
BA_REL_ "GenSigTimeoutTime" BU_SG_REL_ LEH_MQB SG_ 168 Motor_12_BZ 500;
BA_REL_ "GenSigTimeoutTime" BU_SG_REL_ Getriebe_DQ_Hybrid_MQB SG_ 168 MO_Mom_Begr_stat 500;
BA_REL_ "GenSigTimeoutTime" BU_SG_REL_ Getriebe_DQ_MQB SG_ 168 MO_Mom_Begr_stat 500;
BA_REL_ "GenSigTimeoutTime" BU_SG_REL_ Getriebe_DQ_Hybrid_MQB SG_ 168 MO_Momentenintegral_02 500;
BA_REL_ "GenSigTimeoutTime" BU_SG_REL_ Getriebe_DQ_MQB SG_ 168 MO_Momentenintegral_02 500;
BA_REL_ "GenSigTimeoutTime" BU_SG_REL_ BMS_MQB SG_ 168 MO_QBit_Drehzahl_01 500;
BA_REL_ "GenSigTimeoutTime" BU_SG_REL_ Gateway_MQB SG_ 168 MO_QBit_Drehzahl_01 500;
BA_REL_ "GenSigTimeoutTime" BU_SG_REL_ Gateway_MQB SG_ 168 MO_QBit_Drehzahl_01 500;
BA_REL_ "GenSigTimeoutTime" BU_SG_REL_ Gateway_MQB SG_ 168 MO_QBit_Drehzahl_01 500;
BA_REL_ "GenSigTimeoutTime" BU_SG_REL_ Getriebe_DQ_Hybrid_MQB SG_ 168 MO_QBit_Drehzahl_01 500;
BA_REL_ "GenSigTimeoutTime" BU_SG_REL_ Getriebe_DQ_MQB SG_ 168 MO_QBit_Drehzahl_01 500;
BA_REL_ "GenSigTimeoutTime" BU_SG_REL_ LEH_MQB SG_ 168 MO_QBit_Drehzahl_01 500;
BA_REL_ "GenSigTimeoutTime" BU_SG_REL_ BMS_MQB SG_ 168 MO_Drehzahl_01 500;
BA_REL_ "GenSigTimeoutTime" BU_SG_REL_ Gateway_MQB SG_ 168 MO_Drehzahl_01 500;
BA_REL_ "GenSigTimeoutTime" BU_SG_REL_ Gateway_MQB SG_ 168 MO_Drehzahl_01 500;
BA_REL_ "GenSigTimeoutTime" BU_SG_REL_ Gateway_MQB SG_ 168 MO_Drehzahl_01 500;
BA_REL_ "GenSigTimeoutTime" BU_SG_REL_ Gateway_MQB SG_ 168 MO_Drehzahl_01 500;
BA_REL_ "GenSigTimeoutTime" BU_SG_REL_ Gateway_MQB SG_ 168 MO_Drehzahl_01 500;
BA_REL_ "GenSigTimeoutTime" BU_SG_REL_ Gateway_MQB SG_ 168 MO_Drehzahl_01 500;
BA_REL_ "GenSigTimeoutTime" BU_SG_REL_ Getriebe_DQ_Hybrid_MQB SG_ 168 MO_Drehzahl_01 500;
BA_REL_ "GenSigTimeoutTime" BU_SG_REL_ Getriebe_DQ_MQB SG_ 168 MO_Drehzahl_01 500;
BA_REL_ "GenSigTimeoutTime" BU_SG_REL_ LEH_MQB SG_ 168 MO_Drehzahl_01 500;
BA_REL_ "GenSigTimeoutTime" BU_SG_REL_ SAK_MQB SG_ 168 MO_Drehzahl_01 500;
BA_REL_ "GenSigTimeoutTime" BU_SG_REL_ Gateway_MQB SG_ 958 MO_StartStopp_Status 1000;
BA_REL_ "GenSigTimeoutTime" BU_SG_REL_ Gateway_MQB SG_ 958 MO_StartStopp_Status 1000;
BA_REL_ "GenSigTimeoutTime" BU_SG_REL_ Getriebe_DQ_Hybrid_MQB SG_ 958 MO_StartStopp_Status 1000;
BA_REL_ "GenSigTimeoutTime" BU_SG_REL_ Getriebe_DQ_MQB SG_ 958 MO_StartStopp_Status 1000;
BA_REL_ "GenSigTimeoutTime" BU_SG_REL_ Gateway_MQB SG_ 958 MO_StartStopp_Wiederstart 1000;
BA_REL_ "GenSigTimeoutTime" BU_SG_REL_ Gateway_MQB SG_ 958 MO_StartStopp_Wiederstart 1000;
BA_REL_ "GenSigTimeoutTime" BU_SG_REL_ Gateway_MQB SG_ 958 MO_StartStopp_Wiederstart 1000;
BA_REL_ "GenSigTimeoutTime" BU_SG_REL_ Getriebe_DQ_Hybrid_MQB SG_ 958 MO_StartStopp_Wiederstart 1000;
BA_REL_ "GenSigTimeoutTime" BU_SG_REL_ Getriebe_DQ_MQB SG_ 958 MO_StartStopp_Wiederstart 1000;
BA_REL_ "GenSigTimeoutTime" BU_SG_REL_ Gateway_MQB SG_ 958 MO_StartStopp_Motorstopp 1000;
BA_REL_ "GenSigTimeoutTime" BU_SG_REL_ Gateway_MQB SG_ 958 MO_StartStopp_Motorstopp 1000;
BA_REL_ "GenSigTimeoutTime" BU_SG_REL_ Getriebe_DQ_Hybrid_MQB SG_ 958 MO_StartStopp_Motorstopp 1000;
BA_REL_ "GenSigTimeoutTime" BU_SG_REL_ Getriebe_DQ_MQB SG_ 958 MO_StartStopp_Motorstopp 1000;
BA_REL_ "GenSigTimeoutTime" BU_SG_REL_ Gateway_MQB SG_ 958 MO_Freig_Reku 1000;
BA_REL_ "GenSigTimeoutTime" BU_SG_REL_ Gateway_MQB SG_ 958 MO_Kl_75 1000;
BA_REL_ "GenSigTimeoutTime" BU_SG_REL_ Gateway_MQB SG_ 958 MO_Kl_75 1000;
BA_REL_ "GenSigTimeoutTime" BU_SG_REL_ Gateway_MQB SG_ 958 MO_Kl_50 1000;
BA_REL_ "GenSigTimeoutTime" BU_SG_REL_ Gateway_MQB SG_ 958 MO_Kl_50 1000;
BA_REL_ "GenSigTimeoutTime" BU_SG_REL_ Gateway_MQB SG_ 958 MO_Kl_50 1000;
BA_REL_ "GenSigTimeoutTime" BU_SG_REL_ LEH_MQB SG_ 958 MO_Kl_50 1000;
BA_REL_ "GenSigTimeoutTime" BU_SG_REL_ Gateway_MQB SG_ 958 MO_StartStopp_Fahrerwunsch 1000;
BA_REL_ "GenSigTimeoutTime" BU_SG_REL_ Getriebe_DQ_Hybrid_MQB SG_ 958 MO_StartStopp_Fahrerwunsch 1000;
BA_REL_ "GenSigTimeoutTime" BU_SG_REL_ Getriebe_DQ_MQB SG_ 958 MO_StartStopp_Fahrerwunsch 1000;
BA_REL_ "GenSigTimeoutTime" BU_SG_REL_ BMS_MQB SG_ 958 MO_HYB_Fahrbereitschaft 1000;
BA_REL_ "GenSigTimeoutTime" BU_SG_REL_ Getriebe_DQ_Hybrid_MQB SG_ 958 MO_Fahrer_bremst 1000;
BA_REL_ "GenSigTimeoutTime" BU_SG_REL_ Getriebe_DQ_MQB SG_ 958 MO_Fahrer_bremst 1000;
BA_REL_ "GenSigTimeoutTime" BU_SG_REL_ Getriebe_DQ_Hybrid_MQB SG_ 958 MO_QBit_Fahrer_bremst 1000;
BA_REL_ "GenSigTimeoutTime" BU_SG_REL_ Getriebe_DQ_MQB SG_ 958 MO_QBit_Fahrer_bremst 1000;
BA_REL_ "GenSigTimeoutTime" BU_SG_REL_ Getriebe_DQ_Hybrid_MQB SG_ 958 MO_BLS 1000;
BA_REL_ "GenSigTimeoutTime" BU_SG_REL_ Getriebe_DQ_MQB SG_ 958 MO_BLS 1000;
BA_REL_ "GenSigTimeoutTime" BU_SG_REL_ Gateway_MQB SG_ 958 MO_Kuppl_schalter 1000;
BA_REL_ "GenSigTimeoutTime" BU_SG_REL_ Gateway_MQB SG_ 958 MO_Kuppl_schalter 1000;
BA_REL_ "GenSigTimeoutTime" BU_SG_REL_ Gateway_MQB SG_ 958 MO_Interlock 1000;
BA_REL_ "GenSigTimeoutTime" BU_SG_REL_ Gateway_MQB SG_ 958 MO_Motor_laeuft 1000;
BA_REL_ "GenSigTimeoutTime" BU_SG_REL_ Gateway_MQB SG_ 958 MO_Motor_laeuft 1000;
BA_REL_ "GenSigTimeoutTime" BU_SG_REL_ Getriebe_DQ_Hybrid_MQB SG_ 958 MO_Motor_laeuft 1000;
BA_REL_ "GenSigTimeoutTime" BU_SG_REL_ Getriebe_DQ_MQB SG_ 958 MO_Motor_laeuft 1000;
BA_REL_ "GenSigTimeoutTime" BU_SG_REL_ Getriebe_DQ_Hybrid_MQB SG_ 958 MO_Kickdown 1000;
BA_REL_ "GenSigTimeoutTime" BU_SG_REL_ Getriebe_DQ_MQB SG_ 958 MO_Kickdown 1000;
BA_REL_ "GenSigTimeoutTime" BU_SG_REL_ Getriebe_DQ_Hybrid_MQB SG_ 958 MO_Freigabe_Segeln 1000;
BA_REL_ "GenSigTimeoutTime" BU_SG_REL_ Getriebe_DQ_MQB SG_ 958 MO_Freigabe_Segeln 1000;
BA_REL_ "GenSigTimeoutTime" BU_SG_REL_ Getriebe_DQ_Hybrid_MQB SG_ 1631 TSK_QBit_Steigung 5000;
BA_REL_ "GenSigTimeoutTime" BU_SG_REL_ Getriebe_DQ_MQB SG_ 1631 TSK_QBit_Steigung 5000;
BA_REL_ "GenSigTimeoutTime" BU_SG_REL_ Getriebe_DQ_Hybrid_MQB SG_ 1631 TSK_QBit_Fahrzeugmasse 5000;
BA_REL_ "GenSigTimeoutTime" BU_SG_REL_ Getriebe_DQ_MQB SG_ 1631 TSK_QBit_Fahrzeugmasse 5000;
BA_REL_ "GenSigTimeoutTime" BU_SG_REL_ Gateway_MQB SG_ 1631 MO_SpannungsAnf_02 5000;
BA_REL_ "GenSigTimeoutTime" BU_SG_REL_ Getriebe_DQ_Hybrid_MQB SG_ 1631 MO_DPF_reg 5000;
BA_REL_ "GenSigTimeoutTime" BU_SG_REL_ Getriebe_DQ_MQB SG_ 1631 MO_DPF_reg 5000;
BA_REL_ "GenSigTimeoutTime" BU_SG_REL_ Gateway_MQB SG_ 1631 MO_Heizstrom_EKAT 5000;
BA_REL_ "GenSigTimeoutTime" BU_SG_REL_ Gateway_MQB SG_ 1631 MO_Heizstrom_SCR 5000;
BA_REL_ "GenSigTimeoutTime" BU_SG_REL_ Getriebe_DQ_Hybrid_MQB SG_ 1631 TSK_Fahrzeugmasse_02 5000;
BA_REL_ "GenSigTimeoutTime" BU_SG_REL_ Getriebe_DQ_MQB SG_ 1631 TSK_Fahrzeugmasse_02 5000;
BA_REL_ "GenSigTimeoutTime" BU_SG_REL_ Getriebe_DQ_Hybrid_MQB SG_ 1631 TSK_Steigung 5000;
BA_REL_ "GenSigTimeoutTime" BU_SG_REL_ Getriebe_DQ_MQB SG_ 1631 TSK_Steigung 5000;
VAL_ 299 GRA_Hauptschalter 0 "Gerastet_Aus" 1 "Ein" ;
VAL_ 299 GRA_Abbrechen 0 "nicht_betaetigt" 1 "betaetigt" ;
VAL_ 299 GRA_Typ_Hauptschalter 0 "gerasteter_Lenkstockschalter" 1 "getasteter_Lenkstockschalter" ;
VAL_ 299 GRA_Limiter 0 "Aus" 1 "Ein" ;
VAL_ 299 GRA_Tip_Setzen 0 "nicht_betaetigt" 1 "betaetigt" ;
VAL_ 299 GRA_Tip_Hoch 0 "nicht_betaetigt" 1 "betaetigt" ;
VAL_ 299 GRA_Tip_Runter 0 "nicht_betaetigt" 1 "betaetigt" ;
VAL_ 299 GRA_Tip_Wiederaufnahme 0 "nicht_betaetigt" 1 "betaetigt" ;
VAL_ 299 GRA_Verstellung_Zeitluecke 0 "Taste_nicht_betaetigt" 1 "Dist_minus_1" 2 "Dist_plus_1" 3 "nicht_belegt" ;
VAL_ 299 GRA_Codierung 0 "kein_Hebel" 1 "GRA_Hebel" 2 "ACC_Hebel" 3 "nicht_verwendet" ;
VAL_ 299 GRA_Fehler 0 "normal" 1 "Fehler" ;
VAL_ 299 GRA_Typ468 0 "undef" 1 "4_Positions_Bedienteil" 2 "6_Positions_Bedienteil" 3 "8_Positions_Bedienteil" ;
VAL_ 299 GRA_Tip_Stufe_2 0 "Tip_Stufe_1__keine_Betaetigung" 1 "Tip_Stufe_2" ;
VAL_ 960 ZAS_Kl_S 0 "aus" 1 "S_Kontakt_ein" ;
VAL_ 960 ZAS_Kl_15 0 "aus" 1 "ein" ;
VAL_ 960 ZAS_Kl_X 0 "aus" 1 "ein" ;
VAL_ 960 ZAS_Kl_50 0 "aus" 1 "KL50_ein_Startwunsch_Fahrer" ;
VAL_ 949 KL_Drehz_Anh 0 "keine_Anhebung" 1 "Drehzahlanhebung_vom_Motor_angefordert" ;
VAL_ 949 KL_Vorwarn_Komp_ein 1 "Vorwarnung Kompressor ein" ;
VAL_ 949 KL_AC_Schalter 0 "aus" 1 "ein" ;
VAL_ 949 KL_Komp_Moment_alt 1 "veraltet_bzw_Ermittlung_des_Moments_nicht_moeglich__zB_keine_Drehzahl_kein_Kaeltemitteldruck" ;
VAL_ 949 KL_Zonen 0 "1_Zone" 1 "2_Zonen" 2 "3_Zonen" 3 "4_Zonen" ;
VAL_ 949 KL_Vorwarn_Zuheizer_ein 1 "Vorwarnung_Zuheizer_ein" ;
VAL_ 949 KL_Zustand 0 "aus" 1 "ein" ;
VAL_ 949 KL_Comp_rev_rq 255 "Fehler" ;
VAL_ 949 KL_Charisma_FahrPr 0 "nicht_belegt" 1 "Programm_1" 2 "Programm_2" 3 "Programm_3" 4 "Programm_4" 5 "Programm_5" 6 "Programm_6" 7 "Programm_7" 8 "Programm_8" 9 "Programm_9" 10 "Programm_10" 11 "Programm_11" 12 "Programm_12" 13 "Programm_13" 14 "Programm_14" 15 "Programm_15" ;
VAL_ 949 KL_Charisma_Status 0 "Init" 1 "verfuegbar" 2 "nicht_verfuegbar" 3 "asynchron_durch_Fahrerwunsch" ;
VAL_ 949 KL_Comp_enable 0 "Disable" 1 "Enable" ;
VAL_ 949 KL_Last_Kompr 255 "Fehler" ;
VAL_ 949 KL_Spannungs_Anf 0 "keine_Anforderung" 1 "13_5_V_Anforderung" 2 "14_7_V_Anforderung" 3 "Rekuperation_verboten" ;
VAL_ 949 KL_Thermomanagement 0 "keine_Freigabe_TMM__max_Heizbedarf" 1 "kleine_Freigabe_TMM" 2 "mittlere_Freigabe_TMM" 3 "volle_Freigabe_TMM__kein_Heizbedarf" ;
VAL_ 949 KL_StartStopp_Info 0 "Motorlauf_nicht_notwendig_(Stoppfreigabe)" 1 "Motoranlauf_nicht_zwingend_notwendig_(Stoppverbot,keine_Startanforderung)" 2 "Motoranlauf_zwingend_notwendig_(Startanforderung)" 3 "Systemfehler" ;
VAL_ 949 KL_Anf_KL 255 "Fehler" ;
VAL_ 1625 EKL_KD_Fehler 0 "kein_KD_Fehler" 1 "KD_Fehler" ;
VAL_ 1625 EKL_Comp_SCI_com_stat 0 "normal" 1 "CAN_error" 2 "Inverter_error" 3 "CAN_and_Inverter_error" ;
VAL_ 1625 EKL_Comp_output_stat 0 "normal" 1 "output_line_short" 2 "output_line_cut_out" 3 "abnormal_current_detection" ;
VAL_ 1625 EKL_Comp_main_stat 0 "Comp_not_enabled" 1 "Comp_enabled" ;
VAL_ 1625 EKL_Comp_ovld_stat 0 "normal" 1 "voltage_restriction" 2 "current_restriction" 3 "software_over_current" 4 "over_load" 6 "over_input_current" ;
VAL_ 1625 EKL_Comp_Inv_stat 0 "normal" 1 "start_fail" 2 "temperature_protection" 3 "system_abnormal_stop" ;
VAL_ 1625 EKL_Comp_photo_temp_stat 0 "normal" 1 "over_heat_L" 2 "over_heat_S" 3 "sermister_abnormal" ;
VAL_ 1625 EKL_Comp_photo_temp 255 "Fehler" ;
VAL_ 1625 EKL_Comp_current 255 "Fehler" ;
VAL_ 1625 EKL_Comp_rev_stat 255 "Fehler" ;
VAL_ 2549088277 Airbag_01_KompSchutz 0 "inaktiv" 1 "aktiv" ;
VAL_ 2549088277 Airbag_01_Nachlauftyp 0 "Komm_bei_KL15_EIN" 1 "Komm_nach_KL15_AUS" 2 "Komm_bei_KL15_AUS" ;
VAL_ 2549088277 AB_KD_Fehler 0 "kein_KD_Fehler" 1 "KD_Fehler" ;
VAL_ 2549088380 EMotor_KompSchutz 0 "inaktiv" 1 "aktiv" ;
VAL_ 2549088380 EMotor_Nachlauftyp 0 "Komm_bei_KL15_EIN" 1 "Komm_nach_KL15_AUS" 2 "Komm_bei_KL15_AUS" ;
VAL_ 2549088380 EM_HYB_KD_Fehler 0 "kein_KD_Fehler" 1 "KD_Fehler" ;
VAL_ 2549088375 Getriebe_KompSchutz 0 "inaktiv" 1 "aktiv" ;
VAL_ 2549088375 Getriebe_Nachlauftyp 0 "Komm_bei_KL15_EIN" 1 "Komm_nach_KL15_AUS" 2 "Komm_bei_KL15_AUS" ;
VAL_ 2549088375 GE_KD_Fehler 0 "kein_KD_Fehler" 1 "KD_Fehler" ;
VAL_ 2549088379 Hybrid_KompSchutz 0 "inaktiv" 1 "aktiv" ;
VAL_ 2549088379 Hybrid_Nachlauftyp 0 "Komm_bei_KL15_EIN" 1 "Komm_nach_KL15_AUS" 2 "Komm_bei_KL15_AUS" ;
VAL_ 2549088379 BMS_HYB_KD_Fehler 0 "kein_KD_Fehler" 1 "KD_Fehler" ;
VAL_ 2549088374 Motor_KompSchutz 0 "inaktiv" 1 "aktiv" ;
VAL_ 2549088374 Motor_Nachlauftyp 0 "Komm_bei_KL15_EIN" 1 "Komm_nach_KL15_AUS" 2 "Komm_bei_KL15_AUS" ;
VAL_ 2549088374 MO_KD_Fehler 0 "kein_KD_Fehler" 1 "KD_Fehler" ;
VAL_ 2549088284 SAK_KompSchutz 0 "inaktiv" 1 "aktiv" ;
VAL_ 2549088284 SAK_Nachlauftyp 0 "Komm_bei_KL15_EIN" 1 "Komm_nach_KL15_AUS" 2 "Komm_bei_KL15_AUS" ;
VAL_ 2549088284 SAK_KD_Fehler 0 "kein_KD_Fehler" 1 "KD_Fehler" ;
VAL_ 779 KBI_ABS_Lampe 0 "ABS Lampe aus" 1 "ABS Lampe ein" ;
VAL_ 779 KBI_ESP_Lampe 0 "ESP Lampe aus" 1 "ESP Lampe ein" ;
VAL_ 779 KBI_BKL_Lampe 0 "BKL aus" 1 "BKL ein" ;
VAL_ 779 KBI_Airbag_Lampe 0 "Airbag Lampe aus" 1 "Airbag Lampe ein" ;
VAL_ 779 KBI_SILA_gueltig 0 "ungueltig" 1 "gueltig" ;
VAL_ 779 KBI_Vorglueh_System_Lampe 0 "Lampe aus" 1 "Lampe ein" ;
VAL_ 779 KBI_NV_in_Anzeige 0 "NV_nicht_in_Anzeige" 1 "NV_in_Anzeige" ;
VAL_ 779 KBI_Anzeigestatus_ACC 0 "keine_ACC_Anzeige" 1 "ACC_Anzeige_aktiv" ;
VAL_ 779 KBI_Anzeigestatus_GRA 0 "nicht_vorhanden" 1 "Anzeigemoeglichkeit_vorhanden" 2 "reserviert" 3 "Fehler" ;
VAL_ 779 KBI_Tankwarnung 0 "Lampe aus" 1 "Lampe ein" ;
VAL_ 779 KBI_MFA_v_Einheit_01 0 "kmh" 1 "mph" ;
VAL_ 779 KBI_im_Stellgliedtest 0 "kein Stellgliedtest" 1 "Kombi im Stellgliedtest" ;
VAL_ 779 KBI_Anzeigefehler_LDW 0 "nicht vorhanden bzw. unterstützt" 1 "Anzeige iO" 2 "Anzeigefehler" 3 "nicht definiert" ;
VAL_ 779 KBI_Variante_USA 0 "keine USA-Variante" 1 "USA-Variante" ;
VAL_ 779 KBI_Oeldruckwarnung 0 "inaktiv" 1 "aktiv" ;
VAL_ 779 KBI_Handbremse 0 "nicht_angezogen" 1 "angezogen" ;
VAL_ 779 KBI_PLA_in_Anzeige 0 "PLA_nicht_in_Anzeige" 1 "PLA_in_Anzeige" ;
VAL_ 779 KBI_Anzeigefehler_NV 0 "kein_Anzeigefehler" 1 "Anzeigefehler" ;
VAL_ 779 KBI_Anzeigestatus_LIM 0 "nicht_vorhanden" 1 "Anzeigemoeglichkeit_vorhanden" 2 "reserviert" 3 "Fehler" ;
VAL_ 779 KBI_Einheit_Tacho 0 "km/h" 1 "mph" ;
VAL_ 779 KBI_Konsistenz_ACC 0 "ACC Botschaft konsistent" 1 "ACC Botschaft inkonsistent    " ;
VAL_ 779 KBI_Fehler_Anzeige_ACC 0 " iO" 1 "Anzeigefehler ACC" ;
VAL_ 779 KBI_Anzeigefehler_SWA 0 "nicht vorhanden bzw. unterstützt" 1 "Anzeige iO" 2 "Anzeigefehler" 3 "nicht definiert" ;
VAL_ 1719 KBI_Kilometerstand 1048574 "Init" 1048575 "Fehler" ;
VAL_ 1719 KBI_Standzeit_02 131069 "nicht_verfuegbar" 131070 "Init" 131071 "Fehler" ;
VAL_ 1719 KBI_Inhalt_Tank 127 "Fehler" ;
VAL_ 1719 KBI_FStatus_Tank 0 "Tankfüllstand i.O." 1 "Tankfüllstand n.i.O" ;
VAL_ 1719 KBI_QBit_Aussen_Temp_gef 0 "gueltiger_Wert" 1 "Ersatz_Init_oder_Fehlerwert" ;
VAL_ 1719 KBI_Aussen_Temp_gef 253 "nicht verbaut" 254 "Init" 255 "Fehler" ;
VAL_ 982 BCM2_Bremsl_durch_ECD 0 "Bremslicht_ist_aus" 1 "Bremslicht_durch_ECD_aktiv" ;
VAL_ 982 LH_Aussenlicht_def 0 "OK" 1 "defekt" ;
VAL_ 982 LH_Standlicht_H_aktiv 1 "Standlicht hinten aktiv" ;
VAL_ 982 LH_Parklicht_HL_aktiv 0 "nicht aktiv" 1 "Parklicht hinten links aktiv" ;
VAL_ 982 LH_Parklicht_HR_aktiv 0 "nicht aktiv" 1 "Parklicht hinten rechts aktiv" ;
VAL_ 982 LH_Bremslicht_H_aktiv 1 "Bremslicht hinten aktiv" ;
VAL_ 982 LH_Nebelschluss_aktiv 0 "nicht aktiv" 1 "aktiv" ;
VAL_ 982 LH_Rueckfahrlicht_aktiv 0 "nicht aktiv" 1 "aktiv" ;
VAL_ 982 LH_Blinker_HL_akt 1 "Blinker hinten links aktiv" ;
VAL_ 982 LH_Blinker_HR_akt 1 "Blinker hinten rechts aktiv" ;
VAL_ 982 LH_Blinker_li_def 0 "OK" 1 "Blinker hinten links defekt" ;
VAL_ 982 LH_Bremsl_li_def 0 "OK" 1 "mindestens ein Bremslicht hinten links defekt" ;
VAL_ 982 LH_Schlusslicht_li_def 0 "OK" 1 "mindestens ein Schlusslicht hinten links defekt" ;
VAL_ 982 LH_Rueckf_li_def 0 "OK" 1 "Rückfahrlicht hinten links defekt" ;
VAL_ 982 LH_Nebel_li_def 0 "OK" 1 " Nebelschlusslicht hinten links defekt" ;
VAL_ 982 LH_Schluss_Brems_Nebel_li_def 0 "iO" 1 "defekt" ;
VAL_ 982 LH_Schluss_Brems_Nebel_re_def 0 "iO" 1 "defekt" ;
VAL_ 982 LH_Schluss_Brems_li_def 0 "OK" 1 "defekt" ;
VAL_ 982 LH_Schluss_Nebel_li_def 0 "OK" 1 "defekt" ;
VAL_ 982 LH_SL_BRL_BLK_li_def 0 "OK" 1 "defekt" ;
VAL_ 982 LH_Brems_Blk_li_def 0 "OK" 1 "defekt" ;
VAL_ 982 LH_Blinker_re_def 0 "OK" 1 "Blinker hinten rechts defekt" ;
VAL_ 982 LH_Bremsl_re_def 0 "OK" 1 "mindestens ein Bremslicht hinten rechts defekt" ;
VAL_ 982 LH_Schlusslicht_re_def 0 "OK" 1 "mindestens ein Schlusslicht hinten rechts defekt" ;
VAL_ 982 LH_Rueckf_re_def 0 "OK" 1 "Rückfahrlicht hinten rechts defekt" ;
VAL_ 982 LH_Nebel_re_def 0 "OK" 1 "Nebelschlusslicht hinten rechts defekt" ;
VAL_ 982 LH_Schluss_Brems_re_def 0 "OK" 1 "defekt" ;
VAL_ 982 LH_Schluss_Nebel_re_def 0 "OK" 1 "defekt" ;
VAL_ 982 LH_SL_BRL_BLK_re_def 0 "OK" 1 "defekt" ;
VAL_ 982 LH_Brems_Blk_re_def 0 "OK" 1 "defekt" ;
VAL_ 982 LH_Kennzl_def 0 "OK" 1 "Kennzeichenbeleuchtung hinten defekt" ;
VAL_ 982 LH_3_Bremsl_def 0 "OK" 1 "hochgesetzte  Bremsleuchte defekt" ;
VAL_ 982 LH_Nebel_mi_def 0 "OK" 1 " Nebelschlusslicht hinten Mitte defekt" ;
VAL_ 982 LH_Rueckf_mi_def 0 "OK" 1 "Rückfahllicht Mitte defekt" ;
VAL_ 982 LH_Bremsl_li_ges_def 0 "OK" 1 "Alle Bremslichter hinten links defekt" ;
VAL_ 982 LH_Bremsl_re_ges_def 0 "OK" 1 "Alle Bremslichter hinten rechts defekt" ;
VAL_ 134 LWI_Sensorstatus 0 "iO" 1 "nicht kalibriert" ;
VAL_ 134 LWI_QBit_Sub_Daten 0 "LWS-Subinfo 'real' (Lenkradwinkelinformation ADS-tauglich) " 1 "LWS-Subinfo 'simuliert' (Lenkradwinkelinformation nicht ADS-tauglich )" ;
VAL_ 134 LWI_QBit_Lenkradwinkel 0 "gültiger Wert" 1 "ausserhalb der Spezifikation" ;
VAL_ 134 LWI_Lenkradwinkel 8190 "Init" 8191 "Fehler" ;
VAL_ 134 LWI_VZ_Lenkradwinkel 0 "positiv_links_von_der_Nullstellung" 1 "negativ" ;
VAL_ 134 LWI_VZ_Lenkradw_Geschw 0 "positiv_links_von_der_Nullstellung" 1 "negativ" ;
VAL_ 134 LWI_Lenkradw_Geschw 510 "Init" 511 "Fehler" ;
VAL_ 263 MO_Istgang 0 "kein_Gang_eingelegt" 1 "Gang_1" 2 "Gang_2" 3 "Gang_3" 4 "Gang_4" 5 "Gang_5" 6 "Gang_6" 7 "Gang_7" 8 "Gang_8" 9 "Gang_9" ;
VAL_ 263 MO_Sollgang 0 "keine_Empfehlung" 1 "Gang_1" 2 "Gang_2" 3 "Gang_3" 4 "Gang_4" 5 "Gang_5" 6 "Gang_6" 7 "Gang_7" 8 "Gang_8" 9 "Gang_9" ;
VAL_ 263 MO_Oeldruck 255 "Fehler" ;
VAL_ 263 MO_Anzeigedrehz 4095 "Fehler" ;
VAL_ 263 MO_Schaltempf_verfbar 0 "nicht_verfuegbar" 1 "verfuegbar" ;
VAL_ 263 MO_Ladedruck 511 "Fehler" ;
VAL_ 263 MO_KVS_Ueberlauf 0 "kein Ueberlauf" 1 "Kraftstoffverbrauchsignale mindestens 1x übergelaufen" ;
VAL_ 1600 MO_QBit_Ansaugluft_Temp 0 "gueltiger_Wert" 1 "Ersatz_Init_oder_Fehlerwert" ;
VAL_ 1600 MO_QBit_Oel_Temp 0 "gueltiger_Wert" 1 "Ersatz_Init_oder_Fehlerwert" ;
VAL_ 1600 MO_QBit_Kuehlmittel_Temp 0 "gueltiger_Wert" 1 "Ersatz_Init_oder_Fehlerwert" ;
VAL_ 1600 MO_Stellgliedtest_Soundaktuator 0 "kein_Stellgliedtest" 1 "Anforderung_des_Stellgliedtest" ;
VAL_ 1600 MO_HYB_Fehler_HV_Netz 0 "i_O" 1 "kein_generatorischer_Betrieb_moeglich" ;
VAL_ 1600 MO_aktives_Getriebeheizen 0 "kein_Ventil_ansteuern" 1 "Ventil_muss_angesteuert_werden" ;
VAL_ 1600 MO_Absperrventil_oeffnen 0 "nicht_verfuegbar" 1 "Ansteuerung_Ventil_zulaessig" 2 "Ventil_oeffnen_oder_geoeffnet" 3 "Ventil_schliessen_oder_geschlossen" ;
VAL_ 1600 MO_Ansaugluft_Temp 254 "Init" 255 "Fehler" ;
VAL_ 1600 MO_Oel_Temp 253 "nicht_verbaut" 254 "Init" 255 "Fehler" ;
VAL_ 1600 MO_Kuehlmittel_Temp 254 "Init" 255 "Fehler" ;
VAL_ 1600 MO_Hoeheninfo 255 "Fehler" ;
VAL_ 1600 MO_Kennfeldk 0 "keine Kennfeldkühlung vorhanden" 1 "Kennfeldkühlung vorhanden" ;
VAL_ 1600 MO_Versionsinfo 0 "zum Projektbeginn 'aufgeräumter CAN' " 1 "Motor_03_mit_10ms" 16 "MQB_mit_neuer_Momentenschnittstelle" ;
VAL_ 1600 MO_Getriebe_kuehlen 0 "nicht_kuehlen" 1 "kuehlen" ;
VAL_ 1600 MO_Heizungspumpenansteuerung 15 "nicht_verbaut" ;
VAL_ 1600 MO_SpannungsAnf 0 "keine_Anforderung" 1 "Anforderung" ;
VAL_ 1607 MO_ITM_Kuehlmittel_Temp 0 "nicht_verbaut" 2 "Fehler" ;
VAL_ 1607 MO_E85_Sensor 13 "nicht_verbaut" 15 "Fehler" ;
VAL_ 1607 SCR_Anz_Motorstarts 15 "keine Einschränkung (Anzeige Reichweite)" ;
VAL_ 1607 SCR_Reichweite 32767 "Init" ;
VAL_ 1607 SCR_Warnstufe_1 0 "nicht aktiv" 1 "Warnstufe 1 aktiv" ;
VAL_ 1607 SCR_Warnstufe_2 0 "nicht aktiv" 1 "Warnstufe 2 aktiv" ;
VAL_ 1607 SCR_Text 0 "kein Text" 1 "Warntext 1" 2 "Warntext 2" 3 "Hinweistext (nur AUDI)" 4 "Reserve" 5 "Warntext 'SCR-Systemfehler Stufe 1'" 6 "Warntext 'SCR-Systemfehler Stufe 2'" ;
VAL_ 1607 SCR_Akustik 0 "keine Akustik" 1 "Akustik 1" 2 "Akustik 2" 3 "Akustik_bei_Hinweis_(VW)" ;
VAL_ 1607 MO_Kraftstofffilter_Wasser 0 "keine_Anzeige" 1 "Abscheidevolumen_erschoepft" ;
VAL_ 1607 SCR_Systemfehler 0 "Warnung_nicht_aktiv" 1 "Warnung_aktiv" ;
VAL_ 1607 SCR_Inducement_Strategie 0 "Restart_Strategie" 1 "Reduced_Drivability_Strategie" ;
VAL_ 1607 MO_CO2_Faktor 0 "nicht_verbaut" 4095 "Fehler" ;
VAL_ 1607 MO_MKB_MUX 0 "MKB_01" 1 "MKB_02" 2 "MKB_03" 3 "MKB_04" ;
VAL_ 1607 MO_MKB_01 0 "Minus" 1 "A" 2 "B" 3 "C" 4 "D" 5 "E" 6 "F" 7 "G" 8 "H" 9 "I" 10 "J" 11 "K" 12 "L" 13 "M" 14 "N" 15 "O" 16 "P" 17 "Q" 18 "R" 19 "S" 20 "T" 21 "U" 22 "V" 23 "W" 24 "X" 25 "Y" 26 "Z" 27 "Leerzeichen" 28 "Leerzeichen" 29 "Leerzeichen" 30 "Leerzeichen" 31 "Unterstrich" ;
VAL_ 1607 MO_MKB_02 0 "Minus" 1 "A" 2 "B" 3 "C" 4 "D" 5 "E" 6 "F" 7 "G" 8 "H" 9 "I" 10 "J" 11 "K" 12 "L" 13 "M" 14 "N" 15 "O" 16 "P" 17 "Q" 18 "R" 19 "S" 20 "T" 21 "U" 22 "V" 23 "W" 24 "X" 25 "Y" 26 "Z" 27 "Leerzeichen" 28 "Leerzeichen" 29 "Leerzeichen" 30 "Leerzeichen" 31 "Unterstrich" ;
VAL_ 1607 MO_MKB_03 0 "Minus" 1 "A" 2 "B" 3 "C" 4 "D" 5 "E" 6 "F" 7 "G" 8 "H" 9 "I" 10 "J" 11 "K" 12 "L" 13 "M" 14 "N" 15 "O" 16 "P" 17 "Q" 18 "R" 19 "S" 20 "T" 21 "U" 22 "V" 23 "W" 24 "X" 25 "Y" 26 "Z" 27 "Leerzeichen" 28 "Leerzeichen" 29 "Leerzeichen" 30 "Leerzeichen" 31 "Unterstrich" ;
VAL_ 1607 MO_MKB_04 0 "Minus" 1 "A" 2 "B" 3 "C" 4 "D" 5 "E" 6 "F" 7 "G" 8 "H" 9 "I" 10 "J" 11 "K" 12 "L" 13 "M" 14 "N" 15 "O" 16 "P" 17 "Q" 18 "R" 19 "S" 20 "T" 21 "U" 22 "V" 23 "W" 24 "X" 25 "Y" 26 "Z" 27 "Leerzeichen" 28 "Leerzeichen" 29 "Leerzeichen" 30 "Leerzeichen" 31 "Unterstrich" ;
VAL_ 167 MO_Mom_Soll_Roh 1022 "Init" 1023 "Fehler" ;
VAL_ 167 MO_Mom_Ist_Summe 1022 "Init" 1023 "Fehler" ;
VAL_ 167 MO_Mom_Traegheit_Summe 1022 "Init" 1023 "Fehler" ;
VAL_ 167 MO_Mom_Soll_gefiltert 1022 "Init" 1023 "Fehler" ;
VAL_ 167 MO_Mom_Schub 510 "Init" 511 "Fehler" ;
VAL_ 167 MO_Status_Normalbetrieb_01 0 "kein Normalbetrieb" 1 "Normalbetrieb erreicht" ;
VAL_ 167 MO_erste_Ungenauschwelle 0 "genau" 1 "Momente ungenauer >8%" ;
VAL_ 167 MO_QBit_Motormomente 0 "gueltiger_Wert" 1 "Ersatz_Init_oder_Fehlerwert" ;
VAL_ 168 MO_Mom_neg_verfuegbar 510 "Init" 511 "Fehler" ;
VAL_ 168 MO_Mom_Begr_stat 510 "Init" 511 "Fehler" ;
VAL_ 168 MO_Mom_Begr_dyn 1022 "Init" 1023 "Fehler" ;
VAL_ 168 MO_QBit_Drehzahl_01 0 "gueltiger_Wert" 1 "Ersatz_Init_oder_Fehlerwert" ;
VAL_ 168 MO_Drehzahl_01 65535 "Fehler" ;
VAL_ 958 MO_StartStopp_Status 0 "System_in_diesem_KL15_Zyklus_nicht_verfuegbar" 1 "System_aktiv_keine_Freigabe_durch_StartStop_Koordinator" 2 "System_aktiv_alle Freigaben_liegen_vor" 3 "System_aktiv_mindestens_eine_Freigabe_fehlt" ;
VAL_ 958 MO_StartStopp_Wiederstart 0 "Wiederstart_inaktiv" 1 "Wiederstart_aktiv" ;
VAL_ 958 MO_StartStopp_Motorstopp 0 "Motor_Stop_inaktiv" 1 "Motor_Stop_aktiv" ;
VAL_ 958 MO_Freig_Reku 0 "Rekuperations-Modus aus" 1 "Empfehlung Spannungsanhebung" 2 "Empfehlung Spannungsabsenkung" 3 "Rekuperationsmodus aktiv, Spannungsvariation nicht notwendig" ;
VAL_ 958 MO_Kl_75 0 "Aus" 1 "Ein" ;
VAL_ 958 MO_Kl_50 0 "aus" 1 "KL50_ein_Startausfuehrung_Fahrer" ;
VAL_ 958 MO_Gangposition 0 "Gang_N" 1 "Gang_1" 2 "Gang_2" 3 "Gang_3" 4 "Gang_4" 5 "Gang_5" 6 "Gang_6" 7 "Gang_7" 8 "Gang_8" 12 "Zwischenstellung" 13 "Gang_R" 14 "Istgang_nicht_definiert" 15 "Fehler" ;
VAL_ 958 MO_StartStopp_Fahrerwunsch 0 "Init" 1 "Stoppverbot_durch_Fahrer" 2 "Stoppfreigabe_durch_Fahrer" 3 "Stoppanforderung_durch_Fahrer" ;
VAL_ 958 MO_HYB_Fahrbereitschaft 0 "keine_Fahrbereitschaft" 1 "Fahrbereitschaft" ;
VAL_ 958 MO_Ext_E_Fahrt_aktiv 0 "Rueckmeldung_E_Taster_aus" 1 "Rueckmeldung_E_Taster_ein" ;
VAL_ 958 MO_Fahrer_bremst 0 "kein_Bremsen" 1 "Bremse_betaetigt" ;
VAL_ 958 MO_QBit_Fahrer_bremst 0 "gueltiger_Wert" 1 "Ersatz_Init_oder_Fehlerwert" ;
VAL_ 958 MO_BLS 0 "kein_Bremsen" 1 "Bremse_betaetigt" ;
VAL_ 958 MO_Konsistenz_Bremsped 0 "Bremspedalinformation_plausibel" 1 "Bremspedalinformation_unplausibel" ;
VAL_ 958 MO_Timeout_ESP 0 "Empfang_iO" 1 "Timeout" ;
VAL_ 958 MO_Klima_Eingr 0 "kein Eingriff" 1 "Klimakompressor ausschalten" 2 "Klimakompressor Leistungsreduzierung" 3 "Klimakompressor aufgrund der Heissleuchtenvorwarnung ausschalten" ;
VAL_ 958 MO_Aussp_Anlass 0 "Motor_laeuft_nicht_stabil" 1 "Anlasser_ausspuren___Motor_laeuft_stabil" ;
VAL_ 958 MO_Freig_Anlass 0 "Start_nicht_zulaessig" 1 "Startfreigabe" ;
VAL_ 958 MO_Kuppl_schalter 0 "Schalter_sagt_ausgekuppelt" 1 "Schalter_sagt_eingekuppelt" ;
VAL_ 958 MO_Interlock 0 "Interlockschalter_nicht_betaetigt" 1 "Interlockschalter_betaetigt" ;
VAL_ 958 MO_Motor_laeuft 0 "Motor_laeuft_nicht" 1 "Motor_laeuft_autark_und_stabil_und_darf_mechanisch_belastet_werden" ;
VAL_ 958 MO_Kickdown 0 "kein_Kickdown" 1 "Kickdown" ;
VAL_ 958 MO_Status_Zylabschalt_01 0 "alle_Zylinder_brennen" 1 "mindestens_ein_Zylinder_wurde_abgeschaltet" ;
VAL_ 958 MO_EKlKomLeiRed 0 "keine_Leistungsbegr" 1 "Leistungsbegr_75" 2 "Leistungsbegr_50" 3 "Leistungsbegr_25" ;
VAL_ 958 MO_Handshake_STH 0 "keine EKP-Ansteuerung durch STH-Anforderung" 1 "EKP-Ansteuerung durch STH-Anforderung" ;
VAL_ 958 MO_BKV_Unterdruckwarnung 0 "Unterdruckhaushalt_iO" 1 "Unterdruckhaushalt_niO" ;
VAL_ 958 MO_Freigabe_Segeln 0 "Segelbetrieb_nicht_freigegeben" 1 "Segelbetrieb_freigegeben" ;
VAL_ 958 MO_PTC_Status 0 "nicht_verbaut" 1 "Stufe_0" 2 "Stufe_1" 3 "Stufe_2" 4 "Stufe_3" ;
VAL_ 958 MO_QBit_Gangposition 0 "gueltiger_Wert" 1 "Ersatz_Init_oder_Fehlerwert" ;
VAL_ 958 MO_Signalquelle_Gangposition 0 "Sensorsignal" 1 "Modellsignal" ;
VAL_ 958 MO_Remotestart_Betrieb 0 "MSG_nicht_bereit_fuer_Remotestartbetrieb" 1 "MSG_bereit_fuer_oder_im_Remotestartbetrieb" ;
VAL_ 1631 TSK_QBit_Steigung 0 "gueltiger_Wert" 1 "Ersatz_Init_oder_Fehlerwert" ;
VAL_ 1631 TSK_QBit_Fahrzeugmasse 0 "gueltiger_Wert" 1 "Ersatz_Init_oder_Fehlerwert" ;
VAL_ 1631 MO_SpannungsAnf_02 0 "keine_Anforderung" 1 "Mindestspannung_Stufe_1__13_5V" 2 "Mindestspannung_Stufe_2__14_7V" ;
VAL_ 1631 MO_DPF_reg 0 "DPF_regeneriert_nicht" 1 "DPF_regeneriert" ;
VAL_ 1631 MO_Heizstrom_EKAT 127 "Fehler" ;
VAL_ 1631 MO_Heizstrom_SCR 63 "Fehler" ;
VAL_ 1631 TSK_Fahrzeugmasse_02 255 "Fehler" ;
VAL_ 1631 TSK_Steigung 255 "Fehler" ;
